VERSION ""

NS_ :

BS_:

BU_: HIL_Tester LOGGER HIL BMS
VAL_TABLE_ TC_StepStatus 2 "TestStepFail" 1 "TestStepPass" 0 "TestStepRunning" ;
VAL_TABLE_ TC_Step 65535 "Beschreibung fr den Wert '0x0'" ;
VAL_TABLE_ TCId 65535 "SNA" ;
VAL_TABLE_ AA_CNTR_State 1 "CLOSED" 0 "OPEN" ;

BO_ 3221225472 VECTOR__INDEPENDENT_SIG_MSG: 0 Vector__XXX
 SG_ ISOSPI_StatusRegContent10 : 0|8@1+ (1,0) [0|0] "" Vector__XXX
 SG_ ISOSPI_StatusRegContent09 : 0|8@1+ (1,0) [0|0] "" Vector__XXX
 SG_ ISOSPI_StatusRegContent08 : 0|8@1+ (1,0) [0|0] "" Vector__XXX
 SG_ ISOSPI_StatusRegContent07 : 0|8@1+ (1,0) [0|0] "" Vector__XXX
 SG_ ISOSPI_StatusRegContent06 : 0|8@1+ (1,0) [0|0] "" Vector__XXX
 SG_ ISOSPI_StatusRegContent05 : 0|8@1+ (1,0) [0|0] "" Vector__XXX
 SG_ ISOSPI_StatusRegContent04 : 0|8@1+ (1,0) [0|0] "" Vector__XXX
 SG_ ISOSPI_GPIOVoltage10 : 0|16@1+ (0.0001,0) [0|6.5535] "V" Vector__XXX
 SG_ ISOSPI_GPIOVoltage09 : 0|16@1+ (0.0001,0) [0|6.5535] "V" Vector__XXX
 SG_ ISOSPI_GPIOVoltage08 : 0|16@1+ (0.0001,0) [0|6.5535] "V" Vector__XXX
 SG_ ISOSPI_GPIOVoltage07 : 0|16@1+ (0.0001,0) [0|6.5535] "V" Vector__XXX
 SG_ ISOSPI_GPIOVoltage06 : 0|16@1+ (0.0001,0) [0|6.5535] "V" Vector__XXX
 SG_ ISOSPI_GPIOVoltage05 : 0|16@1+ (0.0001,0) [0|6.5535] "V" Vector__XXX
 SG_ ISOSPI_GPIOVoltage04 : 0|16@1+ (0.0001,0) [0|6.5535] "V" Vector__XXX
 SG_ ISOSPI_CellVoltage10 : 0|16@1+ (0.0001,0) [0|6.5535] "V" Vector__XXX
 SG_ ISOSPI_CellVoltage09 : 0|16@1+ (0.0001,0) [0|6.5535] "V" Vector__XXX
 SG_ ISOSPI_CellVoltage08 : 0|16@1+ (0.0001,0) [0|6.5535] "V" Vector__XXX
 SG_ ISOSPI_CellVoltage07 : 0|16@1+ (0.0001,0) [0|6.5535] "V" Vector__XXX
 SG_ ISOSPI_CellVoltage06 : 0|16@1+ (0.0001,0) [0|6.5535] "V" Vector__XXX
 SG_ ISOSPI_CellVoltage05 : 0|16@1+ (0.0001,0) [0|6.5535] "V" Vector__XXX
 SG_ ISOSPI_CellVoltage04 : 0|16@1+ (0.0001,0) [0|6.5535] "V" Vector__XXX
 SG_ ISOSPI_StatusRegReadTime : 0|8@1+ (1,0) [0|0] "ms" Vector__XXX
 SG_ ISOSPI_request_03 : 0|8@1- (1,0) [0|0] "" Vector__XXX
 SG_ ISOSPI_request_04 : 0|8@1- (1,0) [0|0] "" Vector__XXX
 SG_ ISOSPI_request_05 : 0|8@1- (1,0) [0|0] "" Vector__XXX
 SG_ ISOSPI_request_02 : 0|8@1- (1,0) [0|0] "" Vector__XXX
 SG_ ISOSPI_request_01 : 0|8@1- (1,0) [0|0] "" Vector__XXX
 SG_ ISOSPI_GPIOMeasTime : 0|8@1- (1,0) [0|0] "ms" Vector__XXX

BO_ 777 RC_Status9: 8 Vector__XXX
 SG_ RC_cntrl09 m9 : 4|60@1- (1,0) [0|0] "" Vector__XXX
 SG_ RC_mux M : 0|4@1- (1,0) [0|0] "" Vector__XXX

BO_ 775 RC_Status7: 8 Vector__XXX
 SG_ RC_cntrl07 m7 : 4|60@1- (1,0) [0|0] "" Vector__XXX
 SG_ RC_mux M : 0|4@1- (1,0) [0|0] "" Vector__XXX

BO_ 774 RC_Status6: 8 Vector__XXX
 SG_ RC_mux M : 0|4@1- (1,0) [0|0] "" Vector__XXX
 SG_ RC_cntrl06 m6 : 4|60@1- (1,0) [0|0] "" Vector__XXX

BO_ 773 RC_Status5: 8 Vector__XXX
 SG_ RC_mux M : 0|4@1- (1,0) [0|0] "" Vector__XXX
 SG_ RC_cntrl05 m5 : 4|60@1- (1,0) [0|0] "" Vector__XXX

BO_ 772 RC_Status4: 8 Vector__XXX
 SG_ RC_mux M : 0|4@1- (1,0) [0|0] "" Vector__XXX
 SG_ RC_cntrl04 m4 : 4|60@1- (1,0) [0|0] "" Vector__XXX

BO_ 771 RC_Status3: 8 Vector__XXX
 SG_ RC_mux M : 0|4@1- (1,0) [0|0] "" Vector__XXX
 SG_ RC_cntrl03 m3 : 4|60@1- (1,0) [0|0] "" Vector__XXX

BO_ 770 RC_Status2: 8 Vector__XXX
 SG_ RC_mux M : 0|4@1- (1,0) [0|0] "" Vector__XXX
 SG_ RC_cntrl02 m2 : 4|60@1- (1,0) [0|0] "" Vector__XXX

BO_ 769 RC_Status1: 8 Vector__XXX
 SG_ RC_mux M : 0|4@1- (1,0) [0|0] "" Vector__XXX
 SG_ RC_cntrl01 m1 : 4|60@1- (1,0) [0|0] "" Vector__XXX

BO_ 768 RC_Status0: 8 Vector__XXX
 SG_ RC_mux M : 0|4@1- (1,0) [0|0] "" Vector__XXX
 SG_ RC_cntrl00 m0 : 4|60@1- (1,0) [0|0] "" Vector__XXX

BO_ 406 RC_CycleCount: 5 Vector__XXX
 SG_ RC_cycleCount16 m16 : 15|32@0+ (1,0) [0|0] "" Vector__XXX
 SG_ RC_cycleCount15 m15 : 15|32@0+ (1,0) [0|0] "" Vector__XXX
 SG_ RC_cycleCount14 m14 : 15|32@0+ (1,0) [0|0] "" Vector__XXX
 SG_ RC_cycleCount13 m13 : 15|32@0+ (1,0) [0|0] "" Vector__XXX
 SG_ RC_cycleCount12 m12 : 15|32@0+ (1,0) [0|0] "" Vector__XXX
 SG_ RC_cycleCount11 m11 : 15|32@0+ (1,0) [0|0] "" Vector__XXX
 SG_ RC_cycleCount10 m10 : 15|32@0+ (1,0) [0|0] "" Vector__XXX
 SG_ RC_cycleCount09 m9 : 15|32@0+ (1,0) [0|0] "" Vector__XXX
 SG_ RC_cycleCount08 m8 : 15|32@0+ (1,0) [0|0] "" Vector__XXX
 SG_ RC_cycleCount07 m7 : 15|32@0+ (1,0) [0|0] "" Vector__XXX
 SG_ RC_cycleCount06 m6 : 15|32@0+ (1,0) [0|0] "" Vector__XXX
 SG_ RC_cycleCount05 m5 : 15|32@0+ (1,0) [0|0] "" Vector__XXX
 SG_ RC_cycleCount04 m4 : 15|32@0+ (1,0) [0|0] "" Vector__XXX
 SG_ RC_cycleCount03 m3 : 15|32@0+ (1,0) [0|0] "" Vector__XXX
 SG_ RC_cycleCount02 m2 : 15|32@0+ (1,0) [0|0] "" Vector__XXX
 SG_ RC_cycleCount01 m1 : 15|32@0+ (1,0) [0|0] "" Vector__XXX
 SG_ RC_cycleCount_mux M : 0|8@1- (1,0) [0|0] "" Vector__XXX
 SG_ RC_cycleCount00 m0 : 15|32@0+ (1,0) [0|0] "" Vector__XXX

BO_ 272 RC_Status: 8 Vector__XXX
 SG_ RC_status07 m7 : 4|60@1- (1,0) [0|0] "" Vector__XXX
 SG_ RC_status06 m6 : 4|60@1- (1,0) [0|0] "" Vector__XXX
 SG_ RC_status05 m5 : 4|60@1- (1,0) [0|0] "" Vector__XXX
 SG_ RC_status04 m4 : 4|60@1- (1,0) [0|0] "" Vector__XXX
 SG_ RC_status03 m3 : 4|60@1- (1,0) [0|0] "" Vector__XXX
 SG_ RC_status02 m2 : 4|60@1- (1,0) [0|0] "" Vector__XXX
 SG_ RC_status01 m1 : 4|60@1- (1,0) [0|0] "" Vector__XXX
 SG_ RC_status00 m0 : 4|60@1- (1,0) [0|0] "" Vector__XXX
 SG_ RC_mux M : 0|4@1- (1,0) [0|0] "" Vector__XXX

BO_ 528 RC_Cntrl: 8 Vector__XXX
 SG_ RC_cntrl15 m15 : 4|60@1- (1,0) [0|0] "" Vector__XXX
 SG_ RC_cntrl09 m9 : 4|60@1- (1,0) [0|0] "" Vector__XXX
 SG_ RC_cntrl07 m7 : 4|60@1- (1,0) [0|0] "" Vector__XXX
 SG_ RC_cntrl06 m6 : 4|60@1- (1,0) [0|0] "" Vector__XXX
 SG_ RC_cntrl05 m5 : 4|60@1- (1,0) [0|0] "" Vector__XXX
 SG_ RC_cntrl04 m4 : 4|60@1- (1,0) [0|0] "" Vector__XXX
 SG_ RC_cntrl03 m3 : 4|60@1- (1,0) [0|0] "" Vector__XXX
 SG_ RC_cntrl02 m2 : 4|60@1- (1,0) [0|0] "" Vector__XXX
 SG_ RC_cntrl01 m1 : 4|60@1- (1,0) [0|0] "" Vector__XXX
 SG_ RC_mux M : 0|4@1+ (1,0) [0|0] "" Vector__XXX
 SG_ RC_cntrl00 m0 : 4|60@1- (1,0) [0|0] "" Vector__XXX

BO_ 277 RC_Stat_ShortToKL30: 8 HIL_Tester
 SG_ RC_Stat_ShortToKL30 : 0|64@1+ (1,0) [0|0] "" Vector__XXX

BO_ 276 RC_Stat_ShortToGND: 8 HIL_Tester
 SG_ RC_Stat_ShortToGND : 0|64@1+ (1,0) [0|0] "" Vector__XXX

BO_ 533 RC_Cntrl_ShortToKL30: 8 HIL_Tester
 SG_ RC_Cntrl_ShortToKL30 : 0|64@1+ (1,0) [0|0] "" Vector__XXX

BO_ 532 RC_Cntrl_ShortToGND: 8 HIL_Tester
 SG_ RC_Cntrl_ShortToGND : 0|64@1+ (1,0) [0|0] "" Vector__XXX

BO_ 368 USB_ISOSPI_RESPONSE_00: 8 Vector__XXX
 SG_ ISOSPI_StatusRegToRead m7 : 8|8@1+ (1,0) [0|0] "0" Vector__XXX
 SG_ ISOSPI_StatusRegContent03 m8 : 32|8@1+ (1,0) [0|0] "" Vector__XXX
 SG_ ISOSPI_StatusRegContent02 m8 : 24|8@1+ (1,0) [0|0] "" Vector__XXX
 SG_ ISOSPI_StatusRegContent01 m8 : 16|8@1+ (1,0) [0|0] "" Vector__XXX
 SG_ ISOSPI_GPIOVoltage03 m6 : 48|16@1+ (0.0001,0) [0|6.5535] "V" Vector__XXX
 SG_ ISOSPI_GPIOVoltage02 m6 : 32|16@1+ (0.0001,0) [0|6.5535] "V" Vector__XXX
 SG_ ISOSPI_GPIOVoltage01 m6 : 16|16@1+ (0.0001,0) [0|6.5535] "V" Vector__XXX
 SG_ ISOSPI_CellVoltage03 m4 : 48|16@1+ (0.0001,0) [0|6.5535] "V" Vector__XXX
 SG_ ISOSPI_CellVoltage02 m4 : 32|16@1+ (0.0001,0) [0|6.5535] "V" Vector__XXX
 SG_ ISOSPI_CellVoltage01 m4 : 16|16@1+ (0.0001,0) [0|6.5535] "V" Vector__XXX
 SG_ ISOSPI_GPIOToRead m6 : 8|8@1- (1,0) [0|0] "" Vector__XXX
 SG_ ISOSPI_GPIOMeasTime m5 : 8|8@1- (1,0) [0|0] "ms" Vector__XXX
 SG_ ISOSPI_configReadTime m2 : 8|8@1- (1,0) [0|0] "ms" Vector__XXX
 SG_ ISOSPI_CellVoltageToRead m4 : 8|8@1- (1,0) [0|0] "0" Vector__XXX
 SG_ ISOSPI_CellMeasTime m3 : 8|8@1- (1,0) [0|0] "ms" Vector__XXX
 SG_ ISOSPI_request_00 M : 0|8@1- (1,0) [0|0] "" Vector__XXX

BO_ 629 USB_ISOSPI_05: 1 Vector__XXX
 SG_ ISOSPI_request_00 M : 0|8@1- (1,0) [0|0] "" Vector__XXX

BO_ 628 USB_ISOSPI_04: 1 Vector__XXX
 SG_ ISOSPI_request_00 M : 0|8@1- (1,0) [0|0] "" Vector__XXX

BO_ 627 USB_ISOSPI_03: 1 Vector__XXX
 SG_ ISOSPI_request_00 M : 0|8@1- (1,0) [0|0] "" Vector__XXX

BO_ 626 USB_ISOSPI_02: 1 Vector__XXX
 SG_ ISOSPI_request_00 M : 0|8@1- (1,0) [0|0] "" Vector__XXX

BO_ 625 USB_ISOSPI_01: 1 Vector__XXX
 SG_ ISOSPI_request_00 M : 0|8@1- (1,0) [0|0] "" Vector__XXX

BO_ 624 USB_ISOSPI_00: 3 Vector__XXX
 SG_ ISOSPI_selftests m13 : 8|8@1- (1,0) [0|0] "" Vector__XXX
 SG_ ISOSPI_ChanneltoBalance m11 : 8|8@1- (1,0) [0|0] "" Vector__XXX
 SG_ ISOSPI_request_00 M : 0|8@1- (1,0) [0|0] "" Vector__XXX

BO_ 297 DAC_CMB_Status: 3 HIL
 SG_ DAC_CMB_Status_05_04_Voltage m67 : 15|16@0+ (0.00122100122100122,0) [0|5] ""  HIL_Tester
 SG_ DAC_CMB_Status_05_03_Voltage m66 : 15|16@0+ (0.00122100122100122,0) [0|5] ""  HIL_Tester
 SG_ DAC_CMB_Status_05_02_Voltage m65 : 15|16@0+ (0.00122100122100122,0) [0|5] ""  HIL_Tester
 SG_ DAC_CMB_Status_05_01_Voltage m64 : 15|16@0+ (0.00122100122100122,0) [0|5] ""  HIL_Tester
 SG_ DAC_CMB_Status_04_04_Voltage m51 : 15|16@0+ (0.00122100122100122,0) [0|5] ""  HIL_Tester
 SG_ DAC_CMB_Status_04_03_Voltage m50 : 15|16@0+ (0.00122100122100122,0) [0|5] ""  HIL_Tester
 SG_ DAC_CMB_Status_04_02_Voltage m49 : 15|16@0+ (0.00122100122100122,0) [0|5] ""  HIL_Tester
 SG_ DAC_CMB_Status_04_01_Voltage m48 : 15|16@0+ (0.00122100122100122,0) [0|5] ""  HIL_Tester
 SG_ DAC_CMB_Status_03_04_Voltage m35 : 15|16@0+ (0.00122100122100122,0) [0|5] ""  HIL_Tester
 SG_ DAC_CMB_Status_03_03_Voltage m34 : 15|16@0+ (0.00122100122100122,0) [0|5] ""  HIL_Tester
 SG_ DAC_CMB_Status_03_02_Voltage m33 : 15|16@0+ (0.00122100122100122,0) [0|5] ""  HIL_Tester
 SG_ DAC_CMB_Status_03_01_Voltage m32 : 15|16@0+ (0.00122100122100122,0) [0|5] ""  HIL_Tester
 SG_ DAC_CMB_Status_02_04_Voltage m19 : 15|16@0+ (0.00122100122100122,0) [0|5] ""  HIL_Tester
 SG_ DAC_CMB_Status_02_03_Voltage m18 : 15|16@0+ (0.00122100122100122,0) [0|5] ""  HIL_Tester
 SG_ DAC_CMB_Status_02_02_Voltage m17 : 15|16@0+ (0.00122100122100122,0) [0|5] ""  HIL_Tester
 SG_ DAC_CMB_Status_02_01_Voltage m16 : 15|16@0+ (0.00122100122100122,0) [0|5] ""  HIL_Tester
 SG_ DAC_CMB_Status_01_04_Voltage m3 : 15|16@0+ (0.00122100122100122,0) [0|5] ""  HIL_Tester
 SG_ DAC_CMB_Status_01_03_Voltage m2 : 15|16@0+ (0.00122100122100122,0) [0|5] ""  HIL_Tester
 SG_ DAC_CMB_Status_01_02_Voltage m1 : 15|16@0+ (0.00122100122100122,0) [0|5] ""  HIL_Tester
 SG_ DAC_CMB_Status_01_01_Voltage m0 : 15|16@0+ (0.00122100122100122,0) [0|5] ""  HIL_Tester
 SG_ DAC_CMB_Status_Channel M : 7|8@0- (1,0) [0|0] ""  HIL_Tester

BO_ 553 DAC_CMB_Cntrl: 3 HIL_Tester
 SG_ DAC_CMB_Cntrl_05_04_Voltage m67 : 15|16@0+ (0.00122100122100122,0) [0|5] ""  HIL_Tester
 SG_ DAC_CMB_Cntrl_05_03_Voltage m66 : 15|16@0+ (0.00122100122100122,0) [0|5] ""  HIL_Tester
 SG_ DAC_CMB_Cntrl_05_02_Voltage m65 : 15|16@0+ (0.00122100122100122,0) [0|5] ""  HIL_Tester
 SG_ DAC_CMB_Cntrl_05_01_Voltage m64 : 15|16@0+ (0.00122100122100122,0) [0|5] ""  HIL_Tester
 SG_ DAC_CMB_Cntrl_04_04_Voltage m51 : 15|16@0+ (0.00122100122100122,0) [0|5] ""  HIL_Tester
 SG_ DAC_CMB_Cntrl_04_03_Voltage m50 : 15|16@0+ (0.00122100122100122,0) [0|5] ""  HIL_Tester
 SG_ DAC_CMB_Cntrl_04_02_Voltage m49 : 15|16@0+ (0.00122100122100122,0) [0|5] ""  HIL_Tester
 SG_ DAC_CMB_Cntrl_04_01_Voltage m48 : 15|16@0+ (0.00122100122100122,0) [0|5] ""  HIL_Tester
 SG_ DAC_CMB_Cntrl_03_04_Voltage m35 : 15|16@0+ (0.00122100122100122,0) [0|5] ""  HIL_Tester
 SG_ DAC_CMB_Cntrl_03_03_Voltage m34 : 15|16@0+ (0.00122100122100122,0) [0|5] ""  HIL_Tester
 SG_ DAC_CMB_Cntrl_03_02_Voltage m33 : 15|16@0+ (0.00122100122100122,0) [0|5] ""  HIL_Tester
 SG_ DAC_CMB_Cntrl_03_01_Voltage m32 : 15|16@0+ (0.00122100122100122,0) [0|5] ""  HIL_Tester
 SG_ DAC_CMB_Cntrl_02_04_Voltage m19 : 15|16@0+ (0.00122100122100122,0) [0|5] ""  HIL_Tester
 SG_ DAC_CMB_Cntrl_02_03_Voltage m18 : 15|16@0+ (0.00122100122100122,0) [0|5] ""  HIL_Tester
 SG_ DAC_CMB_Cntrl_02_02_Voltage m17 : 15|16@0+ (0.00122100122100122,0) [0|5] ""  HIL_Tester
 SG_ DAC_CMB_Cntrl_02_01_Voltage m16 : 15|16@0+ (0.00122100122100122,0) [0|5] ""  HIL_Tester
 SG_ DAC_CMB_Cntrl_01_04_Voltage m3 : 15|16@0+ (0.00122100122100122,0) [0|5] ""  HIL_Tester
 SG_ DAC_CMB_Cntrl_01_03_Voltage m2 : 15|16@0+ (0.00122100122100122,0) [0|5] ""  HIL_Tester
 SG_ DAC_CMB_Cntrl_01_02_Voltage m1 : 15|16@0+ (0.00122100122100122,0) [0|5] ""  HIL_Tester
 SG_ DAC_CMB_Cntrl_01_01_Voltage m0 : 15|16@0+ (0.00122100122100122,0) [0|5] ""  HIL_Tester
 SG_ DAC_CMB_Cntrl_Channel M : 7|8@0- (1,0) [0|0] ""  HIL_Tester

BO_ 554 DAC_CMB_Cntrl2: 3 HIL_Tester
 SG_ DAC_CMB_Cntrl_05_04_Voltage m67 : 15|16@0+ (0.00122100122100122,0) [0|5] ""  HIL_Tester
 SG_ DAC_CMB_Cntrl_05_03_Voltage m66 : 15|16@0+ (0.00122100122100122,0) [0|5] ""  HIL_Tester
 SG_ DAC_CMB_Cntrl_05_02_Voltage m65 : 15|16@0+ (0.00122100122100122,0) [0|5] ""  HIL_Tester
 SG_ DAC_CMB_Cntrl_05_01_Voltage m64 : 15|16@0+ (0.00122100122100122,0) [0|5] ""  HIL_Tester
 SG_ DAC_CMB_Cntrl_04_04_Voltage m51 : 15|16@0+ (0.00122100122100122,0) [0|5] ""  HIL_Tester
 SG_ DAC_CMB_Cntrl_04_03_Voltage m50 : 15|16@0+ (0.00122100122100122,0) [0|5] ""  HIL_Tester
 SG_ DAC_CMB_Cntrl_04_02_Voltage m49 : 15|16@0+ (0.00122100122100122,0) [0|5] ""  HIL_Tester
 SG_ DAC_CMB_Cntrl_04_01_Voltage m48 : 15|16@0+ (0.00122100122100122,0) [0|5] ""  HIL_Tester
 SG_ DAC_CMB_Cntrl_03_04_Voltage m35 : 15|16@0+ (0.00122100122100122,0) [0|5] ""  HIL_Tester
 SG_ DAC_CMB_Cntrl_03_03_Voltage m34 : 15|16@0+ (0.00122100122100122,0) [0|5] ""  HIL_Tester
 SG_ DAC_CMB_Cntrl_03_02_Voltage m33 : 15|16@0+ (0.00122100122100122,0) [0|5] ""  HIL_Tester
 SG_ DAC_CMB_Cntrl_03_01_Voltage m32 : 15|16@0+ (0.00122100122100122,0) [0|5] ""  HIL_Tester
 SG_ DAC_CMB_Cntrl_02_04_Voltage m19 : 15|16@0+ (0.00122100122100122,0) [0|5] ""  HIL_Tester
 SG_ DAC_CMB_Cntrl_02_03_Voltage m18 : 15|16@0+ (0.00122100122100122,0) [0|5] ""  HIL_Tester
 SG_ DAC_CMB_Cntrl_02_02_Voltage m17 : 15|16@0+ (0.00122100122100122,0) [0|5] ""  HIL_Tester
 SG_ DAC_CMB_Cntrl_02_01_Voltage m16 : 15|16@0+ (0.00122100122100122,0) [0|5] ""  HIL_Tester
 SG_ DAC_CMB_Cntrl_01_04_Voltage m3 : 15|16@0+ (0.00122100122100122,0) [0|5] ""  HIL_Tester
 SG_ DAC_CMB_Cntrl_01_03_Voltage m2 : 15|16@0+ (0.00122100122100122,0) [0|5] ""  HIL_Tester
 SG_ DAC_CMB_Cntrl_01_02_Voltage m1 : 15|16@0+ (0.00122100122100122,0) [0|5] ""  HIL_Tester
 SG_ DAC_CMB_Cntrl_01_01_Voltage m0 : 15|16@0+ (0.00122100122100122,0) [0|5] ""  HIL_Tester
 SG_ DAC_CMB_Cntrl_Channel M : 7|8@0- (1,0) [0|0] ""  HIL_Tester

BO_ 555 DAC_CMB_Cntrl3: 3 HIL_Tester
 SG_ DAC_CMB_Cntrl_05_04_Voltage m67 : 15|16@0+ (0.00122100122100122,0) [0|5] ""  HIL_Tester
 SG_ DAC_CMB_Cntrl_05_03_Voltage m66 : 15|16@0+ (0.00122100122100122,0) [0|5] ""  HIL_Tester
 SG_ DAC_CMB_Cntrl_05_02_Voltage m65 : 15|16@0+ (0.00122100122100122,0) [0|5] ""  HIL_Tester
 SG_ DAC_CMB_Cntrl_05_01_Voltage m64 : 15|16@0+ (0.00122100122100122,0) [0|5] ""  HIL_Tester
 SG_ DAC_CMB_Cntrl_04_04_Voltage m51 : 15|16@0+ (0.00122100122100122,0) [0|5] ""  HIL_Tester
 SG_ DAC_CMB_Cntrl_04_03_Voltage m50 : 15|16@0+ (0.00122100122100122,0) [0|5] ""  HIL_Tester
 SG_ DAC_CMB_Cntrl_04_02_Voltage m49 : 15|16@0+ (0.00122100122100122,0) [0|5] ""  HIL_Tester
 SG_ DAC_CMB_Cntrl_04_01_Voltage m48 : 15|16@0+ (0.00122100122100122,0) [0|5] ""  HIL_Tester
 SG_ DAC_CMB_Cntrl_03_04_Voltage m35 : 15|16@0+ (0.00122100122100122,0) [0|5] ""  HIL_Tester
 SG_ DAC_CMB_Cntrl_03_03_Voltage m34 : 15|16@0+ (0.00122100122100122,0) [0|5] ""  HIL_Tester
 SG_ DAC_CMB_Cntrl_03_02_Voltage m33 : 15|16@0+ (0.00122100122100122,0) [0|5] ""  HIL_Tester
 SG_ DAC_CMB_Cntrl_03_01_Voltage m32 : 15|16@0+ (0.00122100122100122,0) [0|5] ""  HIL_Tester
 SG_ DAC_CMB_Cntrl_02_04_Voltage m19 : 15|16@0+ (0.00122100122100122,0) [0|5] ""  HIL_Tester
 SG_ DAC_CMB_Cntrl_02_03_Voltage m18 : 15|16@0+ (0.00122100122100122,0) [0|5] ""  HIL_Tester
 SG_ DAC_CMB_Cntrl_02_02_Voltage m17 : 15|16@0+ (0.00122100122100122,0) [0|5] ""  HIL_Tester
 SG_ DAC_CMB_Cntrl_02_01_Voltage m16 : 15|16@0+ (0.00122100122100122,0) [0|5] ""  HIL_Tester
 SG_ DAC_CMB_Cntrl_01_04_Voltage m3 : 15|16@0+ (0.00122100122100122,0) [0|5] ""  HIL_Tester
 SG_ DAC_CMB_Cntrl_01_03_Voltage m2 : 15|16@0+ (0.00122100122100122,0) [0|5] ""  HIL_Tester
 SG_ DAC_CMB_Cntrl_01_02_Voltage m1 : 15|16@0+ (0.00122100122100122,0) [0|5] ""  HIL_Tester
 SG_ DAC_CMB_Cntrl_01_01_Voltage m0 : 15|16@0+ (0.00122100122100122,0) [0|5] ""  HIL_Tester
 SG_ DAC_CMB_Cntrl_Channel M : 7|8@0- (1,0) [0|0] ""  HIL_Tester

BO_ 288 DAC_BMS_Status: 3 HIL
 SG_ DAC_BMS_Status_05_04_Voltage m67 : 15|16@0+ (0.00122100122100122,0) [0|5] ""  HIL_Tester
 SG_ DAC_BMS_Status_05_03_Voltage m66 : 15|16@0+ (0.00122100122100122,0) [0|5] ""  HIL_Tester
 SG_ DAC_BMS_Status_05_02_Voltage m65 : 15|16@0+ (0.00122100122100122,0) [0|5] ""  HIL_Tester
 SG_ DAC_BMS_Status_05_01_Voltage m64 : 15|16@0+ (0.00122100122100122,0) [0|5] ""  HIL_Tester
 SG_ DAC_BMS_Status_04_04_Voltage m51 : 15|16@0+ (0.00122100122100122,0) [0|5] ""  HIL_Tester
 SG_ DAC_BMS_Status_04_03_Voltage m50 : 15|16@0+ (0.00122100122100122,0) [0|5] ""  HIL_Tester
 SG_ DAC_BMS_Status_04_02_Voltage m49 : 15|16@0+ (0.00122100122100122,0) [0|5] ""  HIL_Tester
 SG_ DAC_BMS_Status_04_01_Voltage m48 : 15|16@0+ (0.00122100122100122,0) [0|5] ""  HIL_Tester
 SG_ DAC_BMS_Status_03_04_Voltage m35 : 15|16@0+ (0.00122100122100122,0) [0|5] ""  HIL_Tester
 SG_ DAC_BMS_Status_03_03_Voltage m34 : 15|16@0+ (0.00122100122100122,0) [0|5] ""  HIL_Tester
 SG_ DAC_BMS_Status_03_02_Voltage m33 : 15|16@0+ (0.00122100122100122,0) [0|5] ""  HIL_Tester
 SG_ DAC_BMS_Status_03_01_Voltage m32 : 15|16@0+ (0.00122100122100122,0) [0|5] ""  HIL_Tester
 SG_ DAC_BMS_Status_02_04_Voltage m19 : 15|16@0+ (0.00122100122100122,0) [0|5] ""  HIL_Tester
 SG_ DAC_BMS_Status_02_03_Voltage m18 : 15|16@0+ (0.00122100122100122,0) [0|5] ""  HIL_Tester
 SG_ DAC_BMS_Status_02_02_Voltage m17 : 15|16@0+ (0.00122100122100122,0) [0|5] ""  HIL_Tester
 SG_ DAC_BMS_Status_02_01_Voltage m16 : 15|16@0+ (0.00122100122100122,0) [0|5] ""  HIL_Tester
 SG_ DAC_BMS_Status_01_04_Voltage m3 : 15|16@0+ (0.00122100122100122,0) [0|5] ""  HIL_Tester
 SG_ DAC_BMS_Status_01_03_Voltage m2 : 15|16@0+ (0.00122100122100122,0) [0|5] ""  HIL_Tester
 SG_ DAC_BMS_Status_01_02_Voltage m1 : 15|16@0+ (0.00122100122100122,0) [0|5] ""  HIL_Tester
 SG_ DAC_BMS_Status_01_01_Voltage m0 : 15|16@0+ (0.00122100122100122,0) [0|5] ""  HIL_Tester
 SG_ DAC_BMS_Status_Channel M : 7|8@0+ (1,0) [0|0] ""  HIL_Tester

BO_ 544 DAC_BMS_Cntrl: 3 HIL_Tester
 SG_ DAC_BMS_Cntrl_05_04_Voltage m67 : 15|16@0+ (0.00122100122100122,0) [0|5] ""  HIL_Tester
 SG_ DAC_BMS_Cntrl_05_03_Voltage m66 : 15|16@0+ (0.00122100122100122,0) [0|5] ""  HIL_Tester
 SG_ DAC_BMS_Cntrl_05_02_Voltage m65 : 15|16@0+ (0.00122100122100122,0) [0|5] ""  HIL_Tester
 SG_ DAC_BMS_Cntrl_05_01_Voltage m64 : 15|16@0+ (0.00122100122100122,0) [0|5] ""  HIL_Tester
 SG_ DAC_BMS_Cntrl_04_04_Voltage m51 : 15|16@0+ (0.00122100122100122,0) [0|5] ""  HIL_Tester
 SG_ DAC_BMS_Cntrl_04_03_Voltage m50 : 15|16@0+ (0.00122100122100122,0) [0|5] ""  HIL_Tester
 SG_ DAC_BMS_Cntrl_04_02_Voltage m49 : 15|16@0+ (0.00122100122100122,0) [0|5] ""  HIL_Tester
 SG_ DAC_BMS_Cntrl_04_01_Voltage m48 : 15|16@0+ (0.00122100122100122,0) [0|5] ""  HIL_Tester
 SG_ DAC_BMS_Cntrl_03_04_Voltage m35 : 15|16@0+ (0.00122100122100122,0) [0|5] ""  HIL_Tester
 SG_ DAC_BMS_Cntrl_03_03_Voltage m34 : 15|16@0+ (0.00122100122100122,0) [0|5] ""  HIL_Tester
 SG_ DAC_BMS_Cntrl_03_02_Voltage m33 : 15|16@0+ (0.00122100122100122,0) [0|5] ""  HIL_Tester
 SG_ DAC_BMS_Cntrl_03_01_Voltage m32 : 15|16@0+ (0.00122100122100122,0) [0|5] ""  HIL_Tester
 SG_ DAC_BMS_Cntrl_02_04_Voltage m19 : 15|16@0+ (0.00122100122100122,0) [0|5] ""  HIL_Tester
 SG_ DAC_BMS_Cntrl_02_03_Voltage m18 : 15|16@0+ (0.00122100122100122,0) [0|5] ""  HIL_Tester
 SG_ DAC_BMS_Cntrl_02_02_Voltage m17 : 15|16@0+ (0.00122100122100122,0) [0|5] ""  HIL_Tester
 SG_ DAC_BMS_Cntrl_02_01_Voltage m16 : 15|16@0+ (0.00122100122100122,0) [0|5] ""  HIL_Tester
 SG_ DAC_BMS_Cntrl_01_04_Voltage m3 : 15|16@0+ (0.00122100122100122,0) [0|5] ""  HIL_Tester
 SG_ DAC_BMS_Cntrl_01_03_Voltage m2 : 15|16@0+ (0.00122100122100122,0) [0|5] ""  HIL_Tester
 SG_ DAC_BMS_Cntrl_01_02_Voltage m1 : 15|16@0+ (0.00122100122100122,0) [0|5] ""  HIL_Tester
 SG_ DAC_BMS_Cntrl_01_01_Voltage m0 : 15|16@0+ (0.00122100122100122,0) [0|5] ""  HIL_Tester
 SG_ DAC_BMS_Cntrl_Channel M : 7|8@0- (1,0) [0|0] ""  HIL_Tester

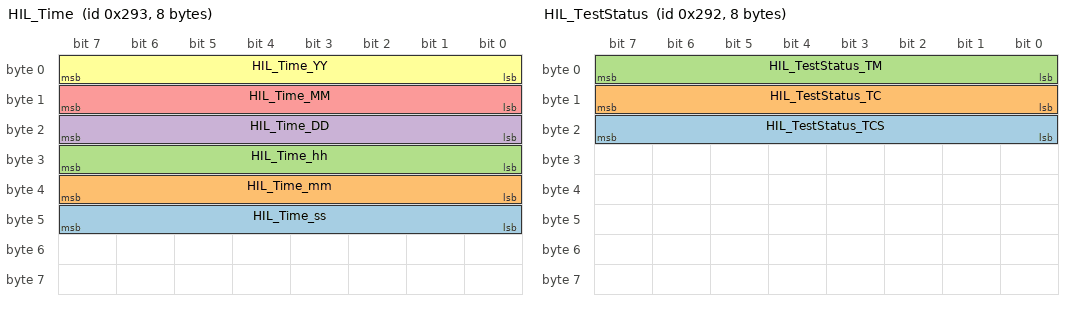
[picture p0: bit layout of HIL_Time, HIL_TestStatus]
BO_ 659 HIL_Time: 8 HIL
 SG_ HIL_Time_ss : 47|8@0+ (1,0) [0|0] ""  HIL_Tester
 SG_ HIL_Time_mm : 39|8@0+ (1,0) [0|0] ""  HIL_Tester
 SG_ HIL_Time_hh : 31|8@0+ (1,0) [0|0] ""  HIL_Tester
 SG_ HIL_Time_DD : 23|8@0+ (1,0) [0|0] ""  HIL_Tester
 SG_ HIL_Time_MM : 15|8@0+ (1,0) [0|0] ""  HIL_Tester
 SG_ HIL_Time_YY : 7|8@0+ (1,0) [0|0] ""  HIL_Tester

BO_ 658 HIL_TestStatus: 8 HIL
 SG_ HIL_TestStatus_TCS : 23|8@0+ (1,0) [0|0] ""  HIL_Tester
 SG_ HIL_TestStatus_TC : 15|8@0+ (1,0) [0|0] ""  HIL_Tester
 SG_ HIL_TestStatus_TM : 7|8@0+ (1,0) [0|0] ""  HIL_Tester

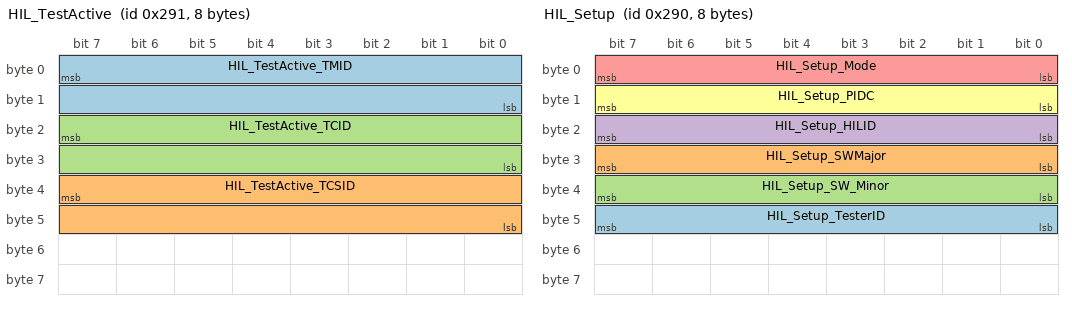
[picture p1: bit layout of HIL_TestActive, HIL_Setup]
BO_ 657 HIL_TestActive: 8 HIL
 SG_ HIL_TestActive_TMID : 7|16@0+ (1,0) [0|0] ""  HIL_Tester
 SG_ HIL_TestActive_TCSID : 39|16@0+ (1,0) [0|0] ""  HIL_Tester
 SG_ HIL_TestActive_TCID : 23|16@0+ (1,0) [0|0] ""  HIL_Tester

BO_ 656 HIL_Setup: 8 HIL
 SG_ HIL_Setup_TesterID : 47|8@0+ (1,0) [0|0] ""  HIL_Tester
 SG_ HIL_Setup_SWMajor : 31|8@0+ (1,0) [0|0] ""  HIL_Tester
 SG_ HIL_Setup_SW_Minor : 39|8@0+ (1,0) [0|0] ""  HIL_Tester
 SG_ HIL_Setup_HILID : 23|8@0+ (1,0) [0|0] ""  HIL_Tester
 SG_ HIL_Setup_Mode : 7|8@0+ (1,0) [0|0] ""  HIL_Tester
 SG_ HIL_Setup_PIDC : 15|8@0+ (1,0) [0|0] ""  HIL_Tester

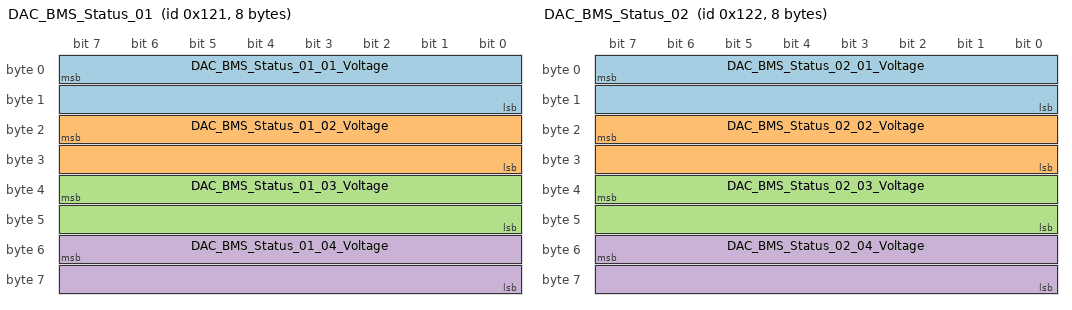
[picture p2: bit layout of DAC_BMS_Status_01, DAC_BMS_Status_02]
BO_ 289 DAC_BMS_Status_01: 8 HIL
 SG_ DAC_BMS_Status_01_01_Voltage : 7|16@0+ (0.00122100122100122,0) [0|5] ""  HIL_Tester
 SG_ DAC_BMS_Status_01_02_Voltage : 23|16@0+ (0.00122100122100122,0) [0|5] ""  HIL_Tester
 SG_ DAC_BMS_Status_01_03_Voltage : 39|16@0+ (0.00122100122100122,0) [0|5] ""  HIL_Tester
 SG_ DAC_BMS_Status_01_04_Voltage : 55|16@0+ (0.00122100122100122,0) [0|5] ""  HIL_Tester

BO_ 290 DAC_BMS_Status_02: 8 HIL
 SG_ DAC_BMS_Status_02_01_Voltage : 7|16@0+ (0.00122100122100122,0) [0|5] ""  HIL_Tester
 SG_ DAC_BMS_Status_02_02_Voltage : 23|16@0+ (0.00122100122100122,0) [0|5] ""  HIL_Tester
 SG_ DAC_BMS_Status_02_03_Voltage : 39|16@0+ (0.00122100122100122,0) [0|5] ""  HIL_Tester
 SG_ DAC_BMS_Status_02_04_Voltage : 55|16@0+ (0.00122100122100122,0) [0|5] ""  HIL_Tester

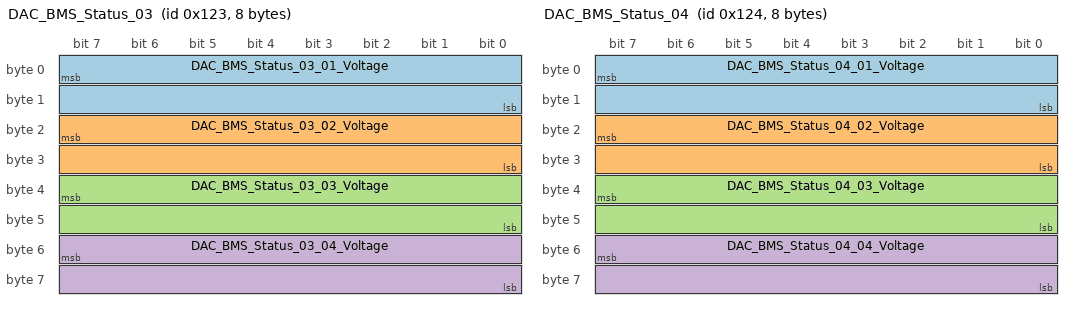
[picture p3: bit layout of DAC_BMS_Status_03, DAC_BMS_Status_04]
BO_ 291 DAC_BMS_Status_03: 8 HIL
 SG_ DAC_BMS_Status_03_01_Voltage : 7|16@0+ (0.00122100122100122,0) [0|5] ""  HIL_Tester
 SG_ DAC_BMS_Status_03_02_Voltage : 23|16@0+ (0.00122100122100122,0) [0|5] ""  HIL_Tester
 SG_ DAC_BMS_Status_03_03_Voltage : 39|16@0+ (0.00122100122100122,0) [0|5] ""  HIL_Tester
 SG_ DAC_BMS_Status_03_04_Voltage : 55|16@0+ (0.00122100122100122,0) [0|5] ""  HIL_Tester

BO_ 292 DAC_BMS_Status_04: 8 HIL
 SG_ DAC_BMS_Status_04_01_Voltage : 7|16@0+ (0.00122100122100122,0) [0|5] ""  HIL_Tester
 SG_ DAC_BMS_Status_04_02_Voltage : 23|16@0+ (0.00122100122100122,0) [0|5] ""  HIL_Tester
 SG_ DAC_BMS_Status_04_03_Voltage : 39|16@0+ (0.00122100122100122,0) [0|5] ""  HIL_Tester
 SG_ DAC_BMS_Status_04_04_Voltage : 55|16@0+ (0.00122100122100122,0) [0|5] ""  HIL_Tester

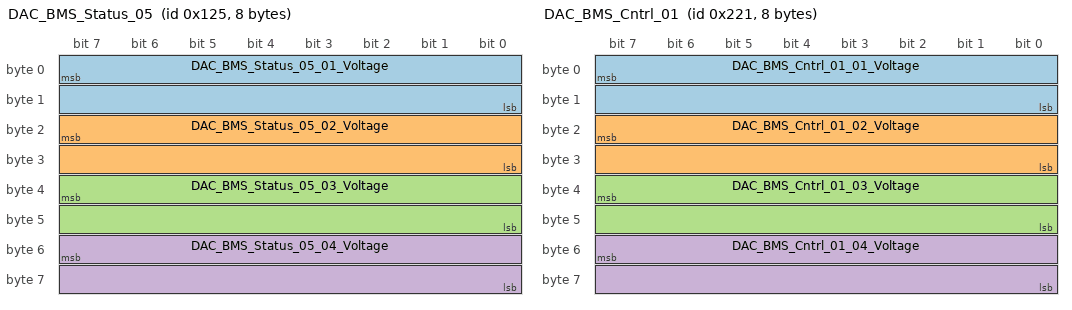
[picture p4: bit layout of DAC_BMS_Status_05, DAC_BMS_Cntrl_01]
BO_ 293 DAC_BMS_Status_05: 8 HIL
 SG_ DAC_BMS_Status_05_01_Voltage : 7|16@0+ (0.00122100122100122,0) [0|5] ""  HIL_Tester
 SG_ DAC_BMS_Status_05_02_Voltage : 23|16@0+ (0.00122100122100122,0) [0|5] ""  HIL_Tester
 SG_ DAC_BMS_Status_05_03_Voltage : 39|16@0+ (0.00122100122100122,0) [0|5] ""  HIL_Tester
 SG_ DAC_BMS_Status_05_04_Voltage : 55|16@0+ (0.00122100122100122,0) [0|5] ""  HIL_Tester

BO_ 545 DAC_BMS_Cntrl_01: 8 HIL_Tester
 SG_ DAC_BMS_Cntrl_01_01_Voltage : 7|16@0+ (0.00122100122100122,0) [0|5] ""  HIL
 SG_ DAC_BMS_Cntrl_01_02_Voltage : 23|16@0+ (0.00122100122100122,0) [0|5] ""  HIL
 SG_ DAC_BMS_Cntrl_01_03_Voltage : 39|16@0+ (0.00122100122100122,0) [0|5] ""  HIL
 SG_ DAC_BMS_Cntrl_01_04_Voltage : 55|16@0+ (0.00122100122100122,0) [0|5] ""  HIL

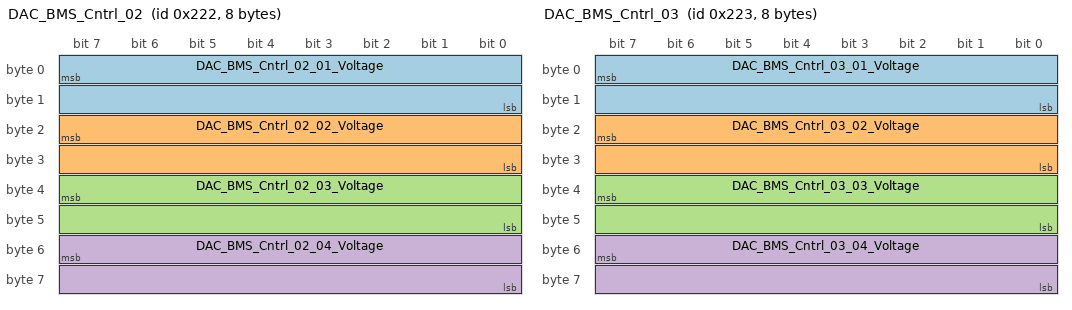
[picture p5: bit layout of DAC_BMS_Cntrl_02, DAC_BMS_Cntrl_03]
BO_ 546 DAC_BMS_Cntrl_02: 8 HIL_Tester
 SG_ DAC_BMS_Cntrl_02_01_Voltage : 7|16@0+ (0.00122100122100122,0) [0|5] ""  HIL
 SG_ DAC_BMS_Cntrl_02_02_Voltage : 23|16@0+ (0.00122100122100122,0) [0|5] ""  HIL
 SG_ DAC_BMS_Cntrl_02_03_Voltage : 39|16@0+ (0.00122100122100122,0) [0|5] ""  HIL
 SG_ DAC_BMS_Cntrl_02_04_Voltage : 55|16@0+ (0.00122100122100122,0) [0|5] ""  HIL

BO_ 547 DAC_BMS_Cntrl_03: 8 HIL_Tester
 SG_ DAC_BMS_Cntrl_03_01_Voltage : 7|16@0+ (0.00122100122100122,0) [0|5] ""  HIL
 SG_ DAC_BMS_Cntrl_03_02_Voltage : 23|16@0+ (0.00122100122100122,0) [0|5] ""  HIL
 SG_ DAC_BMS_Cntrl_03_03_Voltage : 39|16@0+ (0.00122100122100122,0) [0|5] ""  HIL
 SG_ DAC_BMS_Cntrl_03_04_Voltage : 55|16@0+ (0.00122100122100122,0) [0|5] ""  HIL

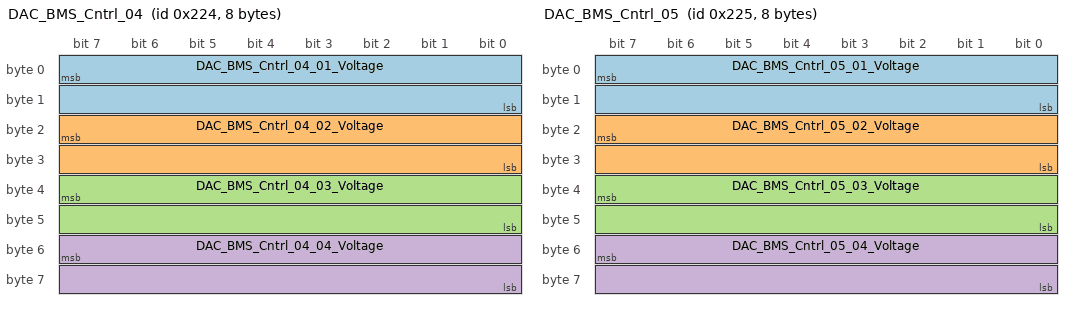
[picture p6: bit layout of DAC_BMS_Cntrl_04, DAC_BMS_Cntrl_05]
BO_ 548 DAC_BMS_Cntrl_04: 8 HIL_Tester
 SG_ DAC_BMS_Cntrl_04_01_Voltage : 7|16@0+ (0.00122100122100122,0) [0|5] ""  HIL
 SG_ DAC_BMS_Cntrl_04_02_Voltage : 23|16@0+ (0.00122100122100122,0) [0|5] ""  HIL
 SG_ DAC_BMS_Cntrl_04_03_Voltage : 39|16@0+ (0.00122100122100122,0) [0|5] ""  HIL
 SG_ DAC_BMS_Cntrl_04_04_Voltage : 55|16@0+ (0.00122100122100122,0) [0|5] ""  HIL

BO_ 549 DAC_BMS_Cntrl_05: 8 HIL_Tester
 SG_ DAC_BMS_Cntrl_05_01_Voltage : 7|16@0+ (0.00122100122100122,0) [0|5] ""  HIL
 SG_ DAC_BMS_Cntrl_05_02_Voltage : 23|16@0+ (0.00122100122100122,0) [0|5] ""  HIL
 SG_ DAC_BMS_Cntrl_05_03_Voltage : 39|16@0+ (0.00122100122100122,0) [0|5] ""  HIL
 SG_ DAC_BMS_Cntrl_05_04_Voltage : 55|16@0+ (0.00122100122100122,0) [0|5] ""  HIL

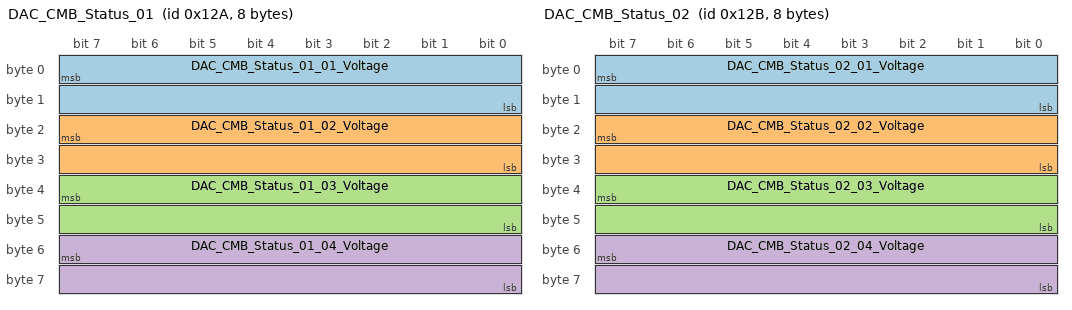
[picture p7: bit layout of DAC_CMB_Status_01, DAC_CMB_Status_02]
BO_ 298 DAC_CMB_Status_01: 8 HIL
 SG_ DAC_CMB_Status_01_01_Voltage : 7|16@0+ (0.00122100122100122,0) [0|5] ""  HIL_Tester
 SG_ DAC_CMB_Status_01_02_Voltage : 23|16@0+ (0.00122100122100122,0) [0|5] ""  HIL_Tester
 SG_ DAC_CMB_Status_01_03_Voltage : 39|16@0+ (0.00122100122100122,0) [0|5] ""  HIL_Tester
 SG_ DAC_CMB_Status_01_04_Voltage : 55|16@0+ (0.00122100122100122,0) [0|5] ""  HIL_Tester

BO_ 299 DAC_CMB_Status_02: 8 HIL
 SG_ DAC_CMB_Status_02_01_Voltage : 7|16@0+ (0.00122100122100122,0) [0|5] ""  HIL_Tester
 SG_ DAC_CMB_Status_02_02_Voltage : 23|16@0+ (0.00122100122100122,0) [0|5] ""  HIL_Tester
 SG_ DAC_CMB_Status_02_03_Voltage : 39|16@0+ (0.00122100122100122,0) [0|5] ""  HIL_Tester
 SG_ DAC_CMB_Status_02_04_Voltage : 55|16@0+ (0.00122100122100122,0) [0|5] ""  HIL_Tester

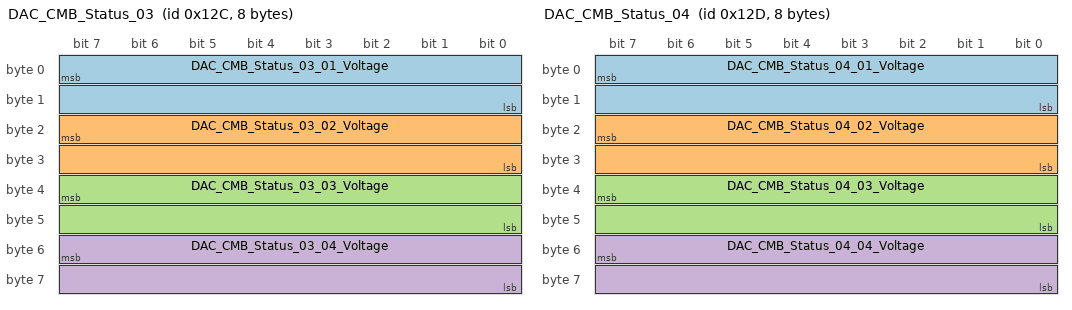
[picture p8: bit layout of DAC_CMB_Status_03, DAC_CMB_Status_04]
BO_ 300 DAC_CMB_Status_03: 8 HIL
 SG_ DAC_CMB_Status_03_01_Voltage : 7|16@0+ (0.00122100122100122,0) [0|5] ""  HIL_Tester
 SG_ DAC_CMB_Status_03_02_Voltage : 23|16@0+ (0.00122100122100122,0) [0|5] ""  HIL_Tester
 SG_ DAC_CMB_Status_03_03_Voltage : 39|16@0+ (0.00122100122100122,0) [0|5] ""  HIL_Tester
 SG_ DAC_CMB_Status_03_04_Voltage : 55|16@0+ (0.00122100122100122,0) [0|5] ""  HIL_Tester

BO_ 301 DAC_CMB_Status_04: 8 HIL
 SG_ DAC_CMB_Status_04_01_Voltage : 7|16@0+ (0.00122100122100122,0) [0|5] ""  HIL_Tester
 SG_ DAC_CMB_Status_04_02_Voltage : 23|16@0+ (0.00122100122100122,0) [0|5] ""  HIL_Tester
 SG_ DAC_CMB_Status_04_03_Voltage : 39|16@0+ (0.00122100122100122,0) [0|5] ""  HIL_Tester
 SG_ DAC_CMB_Status_04_04_Voltage : 55|16@0+ (0.00122100122100122,0) [0|5] ""  HIL_Tester

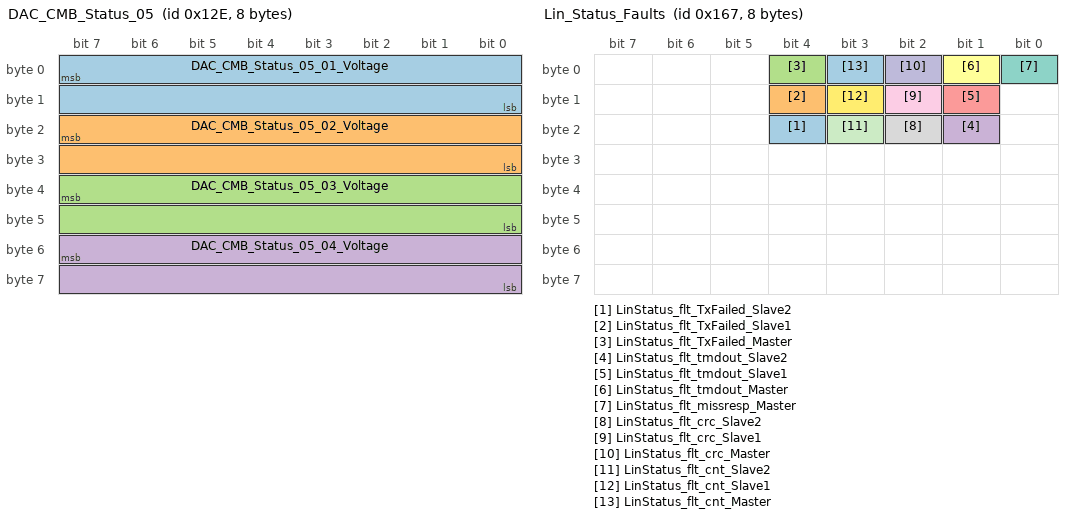
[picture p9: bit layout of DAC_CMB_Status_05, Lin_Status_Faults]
BO_ 302 DAC_CMB_Status_05: 8 HIL
 SG_ DAC_CMB_Status_05_01_Voltage : 7|16@0+ (0.00122100122100122,0) [0|5] ""  HIL_Tester
 SG_ DAC_CMB_Status_05_02_Voltage : 23|16@0+ (0.00122100122100122,0) [0|5] ""  HIL_Tester
 SG_ DAC_CMB_Status_05_03_Voltage : 39|16@0+ (0.00122100122100122,0) [0|5] ""  HIL_Tester
 SG_ DAC_CMB_Status_05_04_Voltage : 55|16@0+ (0.00122100122100122,0) [0|5] ""  HIL_Tester

BO_ 321 PS_StatusA_01: 8 HIL
 SG_ PS_StatusA_01_01_VerifyStatus m0 : 63|8@0+ (1,0) [0|255] ""  HIL_Tester
 SG_ PS_StatusA_01_01_Modes m0 : 55|8@0+ (1,0) [0|255] ""  HIL_Tester
 SG_ PS_StatusA_01_01_Enable m0 : 15|8@0+ (1,0) [0|255] ""  HIL_Tester
 SG_ PS_StatusA_01_01_VoltageActual m0 : 23|16@0+ (0.001,0) [0|32] ""  HIL_Tester
 SG_ PS_StatusA_01_01_CurrentActual m0 : 39|16@0+ (0.001,0) [0|32] ""  HIL_Tester
 SG_ PS_StatusA_01_02_VerifyStatus m1 : 63|8@0+ (1,0) [0|255] ""  HIL_Tester
 SG_ PS_StatusA_01_02_Modes m1 : 55|8@0+ (1,0) [0|255] ""  HIL_Tester
 SG_ PS_StatusA_01_02_Enable m1 : 15|8@0+ (1,0) [0|255] ""  HIL_Tester
 SG_ PS_StatusA_01_02_VoltageActual m1 : 23|16@0+ (0.001,0) [0|32] ""  HIL_Tester
 SG_ PS_StatusA_01_02_CurrentActual m1 : 39|16@0+ (0.001,0) [0|32] ""  HIL_Tester
 SG_ PS_StatusA_01_03_VerifyStatus m2 : 63|8@0+ (1,0) [0|255] ""  HIL_Tester
 SG_ PS_StatusA_01_03_Modes m2 : 55|8@0+ (1,0) [0|255] ""  HIL_Tester
 SG_ PS_StatusA_01_03_Enable m2 : 15|8@0+ (1,0) [0|255] ""  HIL_Tester
 SG_ PS_StatusA_01_03_VoltageActual m2 : 23|16@0+ (0.001,0) [0|32] ""  HIL_Tester
 SG_ PS_StatusA_01_03_CurrentActual m2 : 39|16@0+ (0.001,0) [0|32] ""  HIL_Tester
 SG_ PS_StatusA_01_04_VerifyStatus m3 : 63|8@0+ (1,0) [0|255] ""  HIL_Tester
 SG_ PS_StatusA_01_04_Modes m3 : 55|8@0+ (1,0) [0|255] ""  HIL_Tester
 SG_ PS_StatusA_01_04_Enable m3 : 15|8@0+ (1,0) [0|255] ""  HIL_Tester
 SG_ PS_StatusA_01_04_VoltageActual m3 : 23|16@0+ (0.001,0) [0|32] ""  HIL_Tester
 SG_ PS_StatusA_01_04_CurrentActual m3 : 39|16@0+ (0.001,0) [0|32] ""  HIL_Tester
 SG_ PS_StatusA_01_Channel M : 7|8@0- (1,0) [0|4] ""  HIL_Tester

BO_ 322 PS_StatusA_02: 8 HIL
 SG_ PS_StatusA_02_01_VerifyStatus m0 : 63|8@0+ (1,0) [0|255] ""  HIL_Tester
 SG_ PS_StatusA_02_01_Modes m0 : 55|8@0+ (1,0) [0|255] ""  HIL_Tester
 SG_ PS_StatusA_02_01_Enable m0 : 15|8@0+ (1,0) [0|255] ""  HIL_Tester
 SG_ PS_StatusA_02_01_VoltageActual m0 : 23|16@0+ (0.001,0) [0|32] ""  HIL_Tester
 SG_ PS_StatusA_02_01_CurrentActual m0 : 39|16@0+ (0.001,0) [0|32] ""  HIL_Tester
 SG_ PS_StatusA_02_02_VerifyStatus m1 : 63|8@0+ (1,0) [0|255] ""  HIL_Tester
 SG_ PS_StatusA_02_02_Modes m1 : 55|8@0+ (1,0) [0|255] ""  HIL_Tester
 SG_ PS_StatusA_02_02_Enable m1 : 15|8@0+ (1,0) [0|255] ""  HIL_Tester
 SG_ PS_StatusA_02_02_VoltageActual m1 : 23|16@0+ (0.001,0) [0|32] ""  HIL_Tester
 SG_ PS_StatusA_02_02_CurrentActual m1 : 39|16@0+ (0.001,0) [0|32] ""  HIL_Tester
 SG_ PS_StatusA_02_03_VerifyStatus m2 : 63|8@0+ (1,0) [0|255] ""  HIL_Tester
 SG_ PS_StatusA_02_03_Modes m2 : 55|8@0+ (1,0) [0|255] ""  HIL_Tester
 SG_ PS_StatusA_02_03_Enable m2 : 15|8@0+ (1,0) [0|255] ""  HIL_Tester
 SG_ PS_StatusA_02_03_VoltageActual m2 : 23|16@0+ (0.001,0) [0|32] ""  HIL_Tester
 SG_ PS_StatusA_02_03_CurrentActual m2 : 39|16@0+ (0.001,0) [0|32] ""  HIL_Tester
 SG_ PS_StatusA_02_04_VerifyStatus m3 : 63|8@0+ (1,0) [0|255] ""  HIL_Tester
 SG_ PS_StatusA_02_04_Modes m3 : 55|8@0+ (1,0) [0|255] ""  HIL_Tester
 SG_ PS_StatusA_02_04_Enable m3 : 15|8@0+ (1,0) [0|255] ""  HIL_Tester
 SG_ PS_StatusA_02_04_VoltageActual m3 : 23|16@0+ (0.001,0) [0|32] ""  HIL_Tester
 SG_ PS_StatusA_02_04_CurrentActual m3 : 39|16@0+ (0.001,0) [0|32] ""  HIL_Tester
 SG_ PS_StatusA_02_Channel M : 7|8@0- (1,0) [0|4] ""  HIL_Tester

BO_ 323 PS_StatusA_03: 8 HIL
 SG_ PS_StatusA_03_01_VerifyStatus m0 : 63|8@0+ (1,0) [0|255] ""  HIL_Tester
 SG_ PS_StatusA_03_01_Modes m0 : 55|8@0+ (1,0) [0|255] ""  HIL_Tester
 SG_ PS_StatusA_03_01_Enable m0 : 15|8@0+ (1,0) [0|255] ""  HIL_Tester
 SG_ PS_StatusA_03_01_VoltageActual m0 : 23|16@0+ (0.001,0) [0|32] ""  HIL_Tester
 SG_ PS_StatusA_03_01_CurrentActual m0 : 39|16@0+ (0.001,0) [0|32] ""  HIL_Tester
 SG_ PS_StatusA_03_02_VerifyStatus m1 : 63|8@0+ (1,0) [0|255] ""  HIL_Tester
 SG_ PS_StatusA_03_02_Modes m1 : 55|8@0+ (1,0) [0|255] ""  HIL_Tester
 SG_ PS_StatusA_03_02_Enable m1 : 15|8@0+ (1,0) [0|255] ""  HIL_Tester
 SG_ PS_StatusA_03_02_VoltageActual m1 : 23|16@0+ (0.001,0) [0|32] ""  HIL_Tester
 SG_ PS_StatusA_03_02_CurrentActual m1 : 39|16@0+ (0.001,0) [0|32] ""  HIL_Tester
 SG_ PS_StatusA_03_03_VerifyStatus m2 : 63|8@0+ (1,0) [0|255] ""  HIL_Tester
 SG_ PS_StatusA_03_03_Modes m2 : 55|8@0+ (1,0) [0|255] ""  HIL_Tester
 SG_ PS_StatusA_03_03_Enable m2 : 15|8@0+ (1,0) [0|255] ""  HIL_Tester
 SG_ PS_StatusA_03_03_VoltageActual m2 : 23|16@0+ (0.001,0) [0|32] ""  HIL_Tester
 SG_ PS_StatusA_03_03_CurrentActual m2 : 39|16@0+ (0.001,0) [0|32] ""  HIL_Tester
 SG_ PS_StatusA_03_04_VerifyStatus m3 : 63|8@0+ (1,0) [0|255] ""  HIL_Tester
 SG_ PS_StatusA_03_04_Modes m3 : 55|8@0+ (1,0) [0|255] ""  HIL_Tester
 SG_ PS_StatusA_03_04_Enable m3 : 15|8@0+ (1,0) [0|255] ""  HIL_Tester
 SG_ PS_StatusA_03_04_VoltageActual m3 : 23|16@0+ (0.001,0) [0|32] ""  HIL_Tester
 SG_ PS_StatusA_03_04_CurrentActual m3 : 39|16@0+ (0.001,0) [0|32] ""  HIL_Tester
 SG_ PS_StatusA_03_Channel M : 7|8@0- (1,0) [0|4] ""  HIL_Tester

BO_ 324 PS_StatusA_04: 8 HIL
 SG_ PS_StatusA_04_01_VerifyStatus m0 : 63|8@0+ (1,0) [0|255] ""  HIL_Tester
 SG_ PS_StatusA_04_01_Modes m0 : 55|8@0+ (1,0) [0|255] ""  HIL_Tester
 SG_ PS_StatusA_04_01_Enable m0 : 15|8@0+ (1,0) [0|255] ""  HIL_Tester
 SG_ PS_StatusA_04_01_VoltageActual m0 : 23|16@0+ (0.001,0) [0|32] ""  HIL_Tester
 SG_ PS_StatusA_04_01_CurrentActual m0 : 39|16@0+ (0.001,0) [0|32] ""  HIL_Tester
 SG_ PS_StatusA_04_02_VerifyStatus m1 : 63|8@0+ (1,0) [0|255] ""  HIL_Tester
 SG_ PS_StatusA_04_02_Modes m1 : 55|8@0+ (1,0) [0|255] ""  HIL_Tester
 SG_ PS_StatusA_04_02_Enable m1 : 15|8@0+ (1,0) [0|255] ""  HIL_Tester
 SG_ PS_StatusA_04_02_VoltageActual m1 : 23|16@0+ (0.001,0) [0|32] ""  HIL_Tester
 SG_ PS_StatusA_04_02_CurrentActual m1 : 39|16@0+ (0.001,0) [0|32] ""  HIL_Tester
 SG_ PS_StatusA_04_03_VerifyStatus m2 : 63|8@0+ (1,0) [0|255] ""  HIL_Tester
 SG_ PS_StatusA_04_03_Modes m2 : 55|8@0+ (1,0) [0|255] ""  HIL_Tester
 SG_ PS_StatusA_04_03_Enable m2 : 15|8@0+ (1,0) [0|255] ""  HIL_Tester
 SG_ PS_StatusA_04_03_VoltageActual m2 : 23|16@0+ (0.001,0) [0|32] ""  HIL_Tester
 SG_ PS_StatusA_04_03_CurrentActual m2 : 39|16@0+ (0.001,0) [0|32] ""  HIL_Tester
 SG_ PS_StatusA_04_04_VerifyStatus m3 : 63|8@0+ (1,0) [0|255] ""  HIL_Tester
 SG_ PS_StatusA_04_04_Modes m3 : 55|8@0+ (1,0) [0|255] ""  HIL_Tester
 SG_ PS_StatusA_04_04_Enable m3 : 15|8@0+ (1,0) [0|255] ""  HIL_Tester
 SG_ PS_StatusA_04_04_VoltageActual m3 : 23|16@0+ (0.001,0) [0|32] ""  HIL_Tester
 SG_ PS_StatusA_04_04_CurrentActual m3 : 39|16@0+ (0.001,0) [0|32] ""  HIL_Tester
 SG_ PS_StatusA_04_Channel M : 7|8@0- (1,0) [0|4] ""  HIL_Tester

BO_ 325 PS_StatusA_05: 8 HIL
 SG_ PS_StatusA_05_01_VerifyStatus m0 : 63|8@0+ (1,0) [0|255] ""  HIL_Tester
 SG_ PS_StatusA_05_01_Modes m0 : 55|8@0+ (1,0) [0|255] ""  HIL_Tester
 SG_ PS_StatusA_05_01_Enable m0 : 15|8@0+ (1,0) [0|255] ""  HIL_Tester
 SG_ PS_StatusA_05_01_VoltageActual m0 : 23|16@0+ (0.001,0) [0|32] ""  HIL_Tester
 SG_ PS_StatusA_05_01_CurrentActual m0 : 39|16@0+ (0.001,0) [0|32] ""  HIL_Tester
 SG_ PS_StatusA_05_02_VerifyStatus m1 : 63|8@0+ (1,0) [0|255] ""  HIL_Tester
 SG_ PS_StatusA_05_02_Modes m1 : 55|8@0+ (1,0) [0|255] ""  HIL_Tester
 SG_ PS_StatusA_05_02_Enable m1 : 15|8@0+ (1,0) [0|255] ""  HIL_Tester
 SG_ PS_StatusA_05_02_VoltageActual m1 : 23|16@0+ (0.001,0) [0|32] ""  HIL_Tester
 SG_ PS_StatusA_05_02_CurrentActual m1 : 39|16@0+ (0.001,0) [0|32] ""  HIL_Tester
 SG_ PS_StatusA_05_03_VerifyStatus m2 : 63|8@0+ (1,0) [0|255] ""  HIL_Tester
 SG_ PS_StatusA_05_03_Modes m2 : 55|8@0+ (1,0) [0|255] ""  HIL_Tester
 SG_ PS_StatusA_05_03_Enable m2 : 15|8@0+ (1,0) [0|255] ""  HIL_Tester
 SG_ PS_StatusA_05_03_VoltageActual m2 : 23|16@0+ (0.001,0) [0|32] ""  HIL_Tester
 SG_ PS_StatusA_05_03_CurrentActual m2 : 39|16@0+ (0.001,0) [0|32] ""  HIL_Tester
 SG_ PS_StatusA_05_04_VerifyStatus m3 : 63|8@0+ (1,0) [0|255] ""  HIL_Tester
 SG_ PS_StatusA_05_04_Modes m3 : 55|8@0+ (1,0) [0|255] ""  HIL_Tester
 SG_ PS_StatusA_05_04_Enable m3 : 15|8@0+ (1,0) [0|255] ""  HIL_Tester
 SG_ PS_StatusA_05_04_VoltageActual m3 : 23|16@0+ (0.001,0) [0|32] ""  HIL_Tester
 SG_ PS_StatusA_05_04_CurrentActual m3 : 39|16@0+ (0.001,0) [0|32] ""  HIL_Tester
 SG_ PS_StatusA_05_Channel M : 7|8@0- (1,0) [0|4] ""  HIL_Tester

BO_ 326 PS_StatusA_06: 8 HIL
 SG_ PS_StatusA_06_01_VerifyStatus m0 : 63|8@0+ (1,0) [0|255] ""  HIL_Tester
 SG_ PS_StatusA_06_01_Modes m0 : 55|8@0+ (1,0) [0|255] ""  HIL_Tester
 SG_ PS_StatusA_06_01_Enable m0 : 15|8@0+ (1,0) [0|255] ""  HIL_Tester
 SG_ PS_StatusA_06_01_VoltageActual m0 : 23|16@0+ (0.001,0) [0|32] ""  HIL_Tester
 SG_ PS_StatusA_06_01_CurrentActual m0 : 39|16@0+ (0.001,0) [0|32] ""  HIL_Tester
 SG_ PS_StatusA_06_02_VerifyStatus m1 : 63|8@0+ (1,0) [0|255] ""  HIL_Tester
 SG_ PS_StatusA_06_02_Modes m1 : 55|8@0+ (1,0) [0|255] ""  HIL_Tester
 SG_ PS_StatusA_06_02_Enable m1 : 15|8@0+ (1,0) [0|255] ""  HIL_Tester
 SG_ PS_StatusA_06_02_VoltageActual m1 : 23|16@0+ (0.001,0) [0|32] ""  HIL_Tester
 SG_ PS_StatusA_06_02_CurrentActual m1 : 39|16@0+ (0.001,0) [0|32] ""  HIL_Tester
 SG_ PS_StatusA_06_03_VerifyStatus m2 : 63|8@0+ (1,0) [0|255] ""  HIL_Tester
 SG_ PS_StatusA_06_03_Modes m2 : 55|8@0+ (1,0) [0|255] ""  HIL_Tester
 SG_ PS_StatusA_06_03_Enable m2 : 15|8@0+ (1,0) [0|255] ""  HIL_Tester
 SG_ PS_StatusA_06_03_VoltageActual m2 : 23|16@0+ (0.001,0) [0|32] ""  HIL_Tester
 SG_ PS_StatusA_06_03_CurrentActual m2 : 39|16@0+ (0.001,0) [0|32] ""  HIL_Tester
 SG_ PS_StatusA_06_04_VerifyStatus m3 : 63|8@0+ (1,0) [0|255] ""  HIL_Tester
 SG_ PS_StatusA_06_04_Modes m3 : 55|8@0+ (1,0) [0|255] ""  HIL_Tester
 SG_ PS_StatusA_06_04_Enable m3 : 15|8@0+ (1,0) [0|255] ""  HIL_Tester
 SG_ PS_StatusA_06_04_VoltageActual m3 : 23|16@0+ (0.001,0) [0|32] ""  HIL_Tester
 SG_ PS_StatusA_06_04_CurrentActual m3 : 39|16@0+ (0.001,0) [0|32] ""  HIL_Tester
 SG_ PS_StatusA_06_Channel M : 7|8@0- (1,0) [0|4] ""  HIL_Tester

BO_ 327 PS_StatusA_07: 8 HIL
 SG_ PS_StatusA_07_01_VerifyStatus m0 : 63|8@0+ (1,0) [0|255] ""  HIL_Tester
 SG_ PS_StatusA_07_01_Modes m0 : 55|8@0+ (1,0) [0|255] ""  HIL_Tester
 SG_ PS_StatusA_07_01_Enable m0 : 15|8@0+ (1,0) [0|255] ""  HIL_Tester
 SG_ PS_StatusA_07_01_VoltageActual m0 : 23|16@0+ (0.001,0) [0|32] ""  HIL_Tester
 SG_ PS_StatusA_07_01_CurrentActual m0 : 39|16@0+ (0.001,0) [0|32] ""  HIL_Tester
 SG_ PS_StatusA_07_02_VerifyStatus m1 : 63|8@0+ (1,0) [0|255] ""  HIL_Tester
 SG_ PS_StatusA_07_02_Modes m1 : 55|8@0+ (1,0) [0|255] ""  HIL_Tester
 SG_ PS_StatusA_07_02_Enable m1 : 15|8@0+ (1,0) [0|255] ""  HIL_Tester
 SG_ PS_StatusA_07_02_VoltageActual m1 : 23|16@0+ (0.001,0) [0|32] ""  HIL_Tester
 SG_ PS_StatusA_07_02_CurrentActual m1 : 39|16@0+ (0.001,0) [0|32] ""  HIL_Tester
 SG_ PS_StatusA_07_03_VerifyStatus m2 : 63|8@0+ (1,0) [0|255] ""  HIL_Tester
 SG_ PS_StatusA_07_03_Modes m2 : 55|8@0+ (1,0) [0|255] ""  HIL_Tester
 SG_ PS_StatusA_07_03_Enable m2 : 15|8@0+ (1,0) [0|255] ""  HIL_Tester
 SG_ PS_StatusA_07_03_VoltageActual m2 : 23|16@0+ (0.001,0) [0|32] ""  HIL_Tester
 SG_ PS_StatusA_07_03_CurrentActual m2 : 39|16@0+ (0.001,0) [0|32] ""  HIL_Tester
 SG_ PS_StatusA_07_04_VerifyStatus m3 : 63|8@0+ (1,0) [0|255] ""  HIL_Tester
 SG_ PS_StatusA_07_04_Modes m3 : 55|8@0+ (1,0) [0|255] ""  HIL_Tester
 SG_ PS_StatusA_07_04_Enable m3 : 15|8@0+ (1,0) [0|255] ""  HIL_Tester
 SG_ PS_StatusA_07_04_VoltageActual m3 : 23|16@0+ (0.001,0) [0|32] ""  HIL_Tester
 SG_ PS_StatusA_07_04_CurrentActual m3 : 39|16@0+ (0.001,0) [0|32] ""  HIL_Tester
 SG_ PS_StatusA_07_Channel M : 7|8@0- (1,0) [0|4] ""  HIL_Tester

BO_ 328 PS_StatusA_08: 8 HIL
 SG_ PS_StatusA_08_01_VerifyStatus m0 : 63|8@0+ (1,0) [0|255] ""  HIL_Tester
 SG_ PS_StatusA_08_01_Modes m0 : 55|8@0+ (1,0) [0|255] ""  HIL_Tester
 SG_ PS_StatusA_08_01_Enable m0 : 15|8@0+ (1,0) [0|255] ""  HIL_Tester
 SG_ PS_StatusA_08_01_VoltageActual m0 : 23|16@0+ (0.001,0) [0|32] ""  HIL_Tester
 SG_ PS_StatusA_08_01_CurrentActual m0 : 39|16@0+ (0.001,0) [0|32] ""  HIL_Tester
 SG_ PS_StatusA_08_02_VerifyStatus m1 : 63|8@0+ (1,0) [0|255] ""  HIL_Tester
 SG_ PS_StatusA_08_02_Modes m1 : 55|8@0+ (1,0) [0|255] ""  HIL_Tester
 SG_ PS_StatusA_08_02_Enable m1 : 15|8@0+ (1,0) [0|255] ""  HIL_Tester
 SG_ PS_StatusA_08_02_VoltageActual m1 : 23|16@0+ (0.001,0) [0|32] ""  HIL_Tester
 SG_ PS_StatusA_08_02_CurrentActual m1 : 39|16@0+ (0.001,0) [0|32] ""  HIL_Tester
 SG_ PS_StatusA_08_03_VerifyStatus m2 : 63|8@0+ (1,0) [0|255] ""  HIL_Tester
 SG_ PS_StatusA_08_03_Modes m2 : 55|8@0+ (1,0) [0|255] ""  HIL_Tester
 SG_ PS_StatusA_08_03_Enable m2 : 15|8@0+ (1,0) [0|255] ""  HIL_Tester
 SG_ PS_StatusA_08_03_VoltageActual m2 : 23|16@0+ (0.001,0) [0|32] ""  HIL_Tester
 SG_ PS_StatusA_08_03_CurrentActual m2 : 39|16@0+ (0.001,0) [0|32] ""  HIL_Tester
 SG_ PS_StatusA_08_04_VerifyStatus m3 : 63|8@0+ (1,0) [0|255] ""  HIL_Tester
 SG_ PS_StatusA_08_04_Modes m3 : 55|8@0+ (1,0) [0|255] ""  HIL_Tester
 SG_ PS_StatusA_08_04_Enable m3 : 15|8@0+ (1,0) [0|255] ""  HIL_Tester
 SG_ PS_StatusA_08_04_VoltageActual m3 : 23|16@0+ (0.001,0) [0|32] ""  HIL_Tester
 SG_ PS_StatusA_08_04_CurrentActual m3 : 39|16@0+ (0.001,0) [0|32] ""  HIL_Tester
 SG_ PS_StatusA_08_Channel M : 7|8@0- (1,0) [0|4] ""  HIL_Tester

BO_ 329 PS_StatusA_09: 8 HIL
 SG_ PS_StatusA_09_01_VerifyStatus m0 : 63|8@0+ (1,0) [0|255] ""  HIL_Tester
 SG_ PS_StatusA_09_01_Modes m0 : 55|8@0+ (1,0) [0|255] ""  HIL_Tester
 SG_ PS_StatusA_09_01_Enable m0 : 15|8@0+ (1,0) [0|255] ""  HIL_Tester
 SG_ PS_StatusA_09_01_VoltageActual m0 : 23|16@0+ (0.001,0) [0|32] ""  HIL_Tester
 SG_ PS_StatusA_09_01_CurrentActual m0 : 39|16@0+ (0.001,0) [0|32] ""  HIL_Tester
 SG_ PS_StatusA_09_02_VerifyStatus m1 : 63|8@0+ (1,0) [0|255] ""  HIL_Tester
 SG_ PS_StatusA_09_02_Modes m1 : 55|8@0+ (1,0) [0|255] ""  HIL_Tester
 SG_ PS_StatusA_09_02_Enable m1 : 15|8@0+ (1,0) [0|255] ""  HIL_Tester
 SG_ PS_StatusA_09_02_VoltageActual m1 : 23|16@0+ (0.001,0) [0|32] ""  HIL_Tester
 SG_ PS_StatusA_09_02_CurrentActual m1 : 39|16@0+ (0.001,0) [0|32] ""  HIL_Tester
 SG_ PS_StatusA_09_03_VerifyStatus m2 : 63|8@0+ (1,0) [0|255] ""  HIL_Tester
 SG_ PS_StatusA_09_03_Modes m2 : 55|8@0+ (1,0) [0|255] ""  HIL_Tester
 SG_ PS_StatusA_09_03_Enable m2 : 15|8@0+ (1,0) [0|255] ""  HIL_Tester
 SG_ PS_StatusA_09_03_VoltageActual m2 : 23|16@0+ (0.001,0) [0|32] ""  HIL_Tester
 SG_ PS_StatusA_09_03_CurrentActual m2 : 39|16@0+ (0.001,0) [0|32] ""  HIL_Tester
 SG_ PS_StatusA_09_04_VerifyStatus m3 : 63|8@0+ (1,0) [0|255] ""  HIL_Tester
 SG_ PS_StatusA_09_04_Modes m3 : 55|8@0+ (1,0) [0|255] ""  HIL_Tester
 SG_ PS_StatusA_09_04_Enable m3 : 15|8@0+ (1,0) [0|255] ""  HIL_Tester
 SG_ PS_StatusA_09_04_VoltageActual m3 : 23|16@0+ (0.001,0) [0|32] ""  HIL_Tester
 SG_ PS_StatusA_09_04_CurrentActual m3 : 39|16@0+ (0.001,0) [0|32] ""  HIL_Tester
 SG_ PS_StatusA_09_Channel M : 7|8@0- (1,0) [0|4] ""  HIL_Tester

BO_ 337 PS_StatusR_01: 8 HIL
 SG_ PS_StatusR_01_01_VerifyRequest m0 : 63|8@0+ (1,0) [0|255] ""  HIL_Tester
 SG_ PS_StatusR_01_01_Modes m0 : 55|8@0+ (1,0) [0|255] ""  HIL_Tester
 SG_ PS_StatusR_01_01_Enable m0 : 15|8@0+ (1,0) [0|255] ""  HIL_Tester
 SG_ PS_StatusR_01_01_VoltageTarget m0 : 23|16@0+ (0.001,0) [0|32] ""  HIL_Tester
 SG_ PS_StatusR_01_01_CurrentLimit m0 : 39|16@0+ (0.001,0) [0|32] ""  HIL_Tester
 SG_ PS_StatusR_01_02_VerifyRequest m1 : 63|8@0+ (1,0) [0|255] ""  HIL_Tester
 SG_ PS_StatusR_01_02_Modes m1 : 55|8@0+ (1,0) [0|255] ""  HIL_Tester
 SG_ PS_StatusR_01_02_Enable m1 : 15|8@0+ (1,0) [0|255] ""  HIL_Tester
 SG_ PS_StatusR_01_02_VoltageTarget m1 : 23|16@0+ (0.001,0) [0|32] ""  HIL_Tester
 SG_ PS_StatusR_01_02_CurrentLimit m1 : 39|16@0+ (0.001,0) [0|32] ""  HIL_Tester
 SG_ PS_StatusR_01_03_VerifyRequest m2 : 63|8@0+ (1,0) [0|255] ""  HIL_Tester
 SG_ PS_StatusR_01_03_Modes m2 : 55|8@0+ (1,0) [0|255] ""  HIL_Tester
 SG_ PS_StatusR_01_03_Enable m2 : 15|8@0+ (1,0) [0|255] ""  HIL_Tester
 SG_ PS_StatusR_01_03_VoltageTarget m2 : 23|16@0+ (0.001,0) [0|32] ""  HIL_Tester
 SG_ PS_StatusR_01_03_CurrentLimit m2 : 39|16@0+ (0.001,0) [0|32] ""  HIL_Tester
 SG_ PS_StatusR_01_04_VerifyRequest m3 : 63|8@0+ (1,0) [0|255] ""  HIL_Tester
 SG_ PS_StatusR_01_04_Modes m3 : 55|8@0+ (1,0) [0|255] ""  HIL_Tester
 SG_ PS_StatusR_01_04_Enable m3 : 15|8@0+ (1,0) [0|255] ""  HIL_Tester
 SG_ PS_StatusR_01_04_VoltageTarget m3 : 23|16@0+ (0.001,0) [0|32] ""  HIL_Tester
 SG_ PS_StatusR_01_04_CurrentLimit m3 : 39|16@0+ (0.001,0) [0|32] ""  HIL_Tester
 SG_ PS_StatusR_01_Channel M : 7|8@0- (1,0) [0|4] ""  HIL_Tester

BO_ 338 PS_StatusR_02: 8 HIL
 SG_ PS_StatusR_02_01_VerifyRequest m0 : 63|8@0+ (1,0) [0|255] ""  HIL_Tester
 SG_ PS_StatusR_02_01_Modes m0 : 55|8@0+ (1,0) [0|255] ""  HIL_Tester
 SG_ PS_StatusR_02_01_Enable m0 : 15|8@0+ (1,0) [0|255] ""  HIL_Tester
 SG_ PS_StatusR_02_01_VoltageTarget m0 : 23|16@0+ (0.001,0) [0|32] ""  HIL_Tester
 SG_ PS_StatusR_02_01_CurrentLimit m0 : 39|16@0+ (0.001,0) [0|32] ""  HIL_Tester
 SG_ PS_StatusR_02_02_VerifyRequest m1 : 63|8@0+ (1,0) [0|255] ""  HIL_Tester
 SG_ PS_StatusR_02_02_Modes m1 : 55|8@0+ (1,0) [0|255] ""  HIL_Tester
 SG_ PS_StatusR_02_02_Enable m1 : 15|8@0+ (1,0) [0|255] ""  HIL_Tester
 SG_ PS_StatusR_02_02_VoltageTarget m1 : 23|16@0+ (0.001,0) [0|32] ""  HIL_Tester
 SG_ PS_StatusR_02_02_CurrentLimit m1 : 39|16@0+ (0.001,0) [0|32] ""  HIL_Tester
 SG_ PS_StatusR_02_03_VerifyRequest m2 : 63|8@0+ (1,0) [0|255] ""  HIL_Tester
 SG_ PS_StatusR_02_03_Modes m2 : 55|8@0+ (1,0) [0|255] ""  HIL_Tester
 SG_ PS_StatusR_02_03_Enable m2 : 15|8@0+ (1,0) [0|255] ""  HIL_Tester
 SG_ PS_StatusR_02_03_VoltageTarget m2 : 23|16@0+ (0.001,0) [0|32] ""  HIL_Tester
 SG_ PS_StatusR_02_03_CurrentLimit m2 : 39|16@0+ (0.001,0) [0|32] ""  HIL_Tester
 SG_ PS_StatusR_02_04_VerifyRequest m3 : 63|8@0+ (1,0) [0|255] ""  HIL_Tester
 SG_ PS_StatusR_02_04_Modes m3 : 55|8@0+ (1,0) [0|255] ""  HIL_Tester
 SG_ PS_StatusR_02_04_Enable m3 : 15|8@0+ (1,0) [0|255] ""  HIL_Tester
 SG_ PS_StatusR_02_04_VoltageTarget m3 : 23|16@0+ (0.001,0) [0|32] ""  HIL_Tester
 SG_ PS_StatusR_02_04_CurrentLimit m3 : 39|16@0+ (0.001,0) [0|32] ""  HIL_Tester
 SG_ PS_StatusR_02_Channel M : 7|8@0- (1,0) [0|4] ""  HIL_Tester

BO_ 339 PS_StatusR_03: 8 HIL
 SG_ PS_StatusR_03_01_VerifyRequest m0 : 63|8@0+ (1,0) [0|255] ""  HIL_Tester
 SG_ PS_StatusR_03_01_Modes m0 : 55|8@0+ (1,0) [0|255] ""  HIL_Tester
 SG_ PS_StatusR_03_01_Enable m0 : 15|8@0+ (1,0) [0|255] ""  HIL_Tester
 SG_ PS_StatusR_03_01_VoltageTarget m0 : 23|16@0+ (0.001,0) [0|32] ""  HIL_Tester
 SG_ PS_StatusR_03_01_CurrentLimit m0 : 39|16@0+ (0.001,0) [0|32] ""  HIL_Tester
 SG_ PS_StatusR_03_02_VerifyRequest m1 : 63|8@0+ (1,0) [0|255] ""  HIL_Tester
 SG_ PS_StatusR_03_02_Modes m1 : 55|8@0+ (1,0) [0|255] ""  HIL_Tester
 SG_ PS_StatusR_03_02_Enable m1 : 15|8@0+ (1,0) [0|255] ""  HIL_Tester
 SG_ PS_StatusR_03_02_VoltageTarget m1 : 23|16@0+ (0.001,0) [0|32] ""  HIL_Tester
 SG_ PS_StatusR_03_02_CurrentLimit m1 : 39|16@0+ (0.001,0) [0|32] ""  HIL_Tester
 SG_ PS_StatusR_03_03_VerifyRequest m2 : 63|8@0+ (1,0) [0|255] ""  HIL_Tester
 SG_ PS_StatusR_03_03_Modes m2 : 55|8@0+ (1,0) [0|255] ""  HIL_Tester
 SG_ PS_StatusR_03_03_Enable m2 : 15|8@0+ (1,0) [0|255] ""  HIL_Tester
 SG_ PS_StatusR_03_03_VoltageTarget m2 : 23|16@0+ (0.001,0) [0|32] ""  HIL_Tester
 SG_ PS_StatusR_03_03_CurrentLimit m2 : 39|16@0+ (0.001,0) [0|32] ""  HIL_Tester
 SG_ PS_StatusR_03_04_VerifyRequest m3 : 63|8@0+ (1,0) [0|255] ""  HIL_Tester
 SG_ PS_StatusR_03_04_Modes m3 : 55|8@0+ (1,0) [0|255] ""  HIL_Tester
 SG_ PS_StatusR_03_04_Enable m3 : 15|8@0+ (1,0) [0|255] ""  HIL_Tester
 SG_ PS_StatusR_03_04_VoltageTarget m3 : 23|16@0+ (0.001,0) [0|32] ""  HIL_Tester
 SG_ PS_StatusR_03_04_CurrentLimit m3 : 39|16@0+ (0.001,0) [0|32] ""  HIL_Tester
 SG_ PS_StatusR_03_Channel M : 7|8@0- (1,0) [0|4] ""  HIL_Tester

BO_ 340 PS_StatusR_04: 8 HIL
 SG_ PS_StatusR_04_01_VerifyRequest m0 : 63|8@0+ (1,0) [0|255] ""  HIL_Tester
 SG_ PS_StatusR_04_01_Modes m0 : 55|8@0+ (1,0) [0|255] ""  HIL_Tester
 SG_ PS_StatusR_04_01_Enable m0 : 15|8@0+ (1,0) [0|255] ""  HIL_Tester
 SG_ PS_StatusR_04_01_VoltageTarget m0 : 23|16@0+ (0.001,0) [0|32] ""  HIL_Tester
 SG_ PS_StatusR_04_01_CurrentLimit m0 : 39|16@0+ (0.001,0) [0|32] ""  HIL_Tester
 SG_ PS_StatusR_04_02_VerifyRequest m1 : 63|8@0+ (1,0) [0|255] ""  HIL_Tester
 SG_ PS_StatusR_04_02_Modes m1 : 55|8@0+ (1,0) [0|255] ""  HIL_Tester
 SG_ PS_StatusR_04_02_Enable m1 : 15|8@0+ (1,0) [0|255] ""  HIL_Tester
 SG_ PS_StatusR_04_02_VoltageTarget m1 : 23|16@0+ (0.001,0) [0|32] ""  HIL_Tester
 SG_ PS_StatusR_04_02_CurrentLimit m1 : 39|16@0+ (0.001,0) [0|32] ""  HIL_Tester
 SG_ PS_StatusR_04_03_VerifyRequest m2 : 63|8@0+ (1,0) [0|255] ""  HIL_Tester
 SG_ PS_StatusR_04_03_Modes m2 : 55|8@0+ (1,0) [0|255] ""  HIL_Tester
 SG_ PS_StatusR_04_03_Enable m2 : 15|8@0+ (1,0) [0|255] ""  HIL_Tester
 SG_ PS_StatusR_04_03_VoltageTarget m2 : 23|16@0+ (0.001,0) [0|32] ""  HIL_Tester
 SG_ PS_StatusR_04_03_CurrentLimit m2 : 39|16@0+ (0.001,0) [0|32] ""  HIL_Tester
 SG_ PS_StatusR_04_04_VerifyRequest m3 : 63|8@0+ (1,0) [0|255] ""  HIL_Tester
 SG_ PS_StatusR_04_04_Modes m3 : 55|8@0+ (1,0) [0|255] ""  HIL_Tester
 SG_ PS_StatusR_04_04_Enable m3 : 15|8@0+ (1,0) [0|255] ""  HIL_Tester
 SG_ PS_StatusR_04_04_VoltageTarget m3 : 23|16@0+ (0.001,0) [0|32] ""  HIL_Tester
 SG_ PS_StatusR_04_04_CurrentLimit m3 : 39|16@0+ (0.001,0) [0|32] ""  HIL_Tester
 SG_ PS_StatusR_04_Channel M : 7|8@0- (1,0) [0|4] ""  HIL_Tester

BO_ 341 PS_StatusR_05: 8 HIL
 SG_ PS_StatusR_05_01_VerifyRequest m0 : 63|8@0+ (1,0) [0|255] ""  HIL_Tester
 SG_ PS_StatusR_05_01_Modes m0 : 55|8@0+ (1,0) [0|255] ""  HIL_Tester
 SG_ PS_StatusR_05_01_Enable m0 : 15|8@0+ (1,0) [0|255] ""  HIL_Tester
 SG_ PS_StatusR_05_01_VoltageTarget m0 : 23|16@0+ (0.001,0) [0|32] ""  HIL_Tester
 SG_ PS_StatusR_05_01_CurrentLimit m0 : 39|16@0+ (0.001,0) [0|32] ""  HIL_Tester
 SG_ PS_StatusR_05_02_VerifyRequest m1 : 63|8@0+ (1,0) [0|255] ""  HIL_Tester
 SG_ PS_StatusR_05_02_Modes m1 : 55|8@0+ (1,0) [0|255] ""  HIL_Tester
 SG_ PS_StatusR_05_02_Enable m1 : 15|8@0+ (1,0) [0|255] ""  HIL_Tester
 SG_ PS_StatusR_05_02_VoltageTarget m1 : 23|16@0+ (0.001,0) [0|32] ""  HIL_Tester
 SG_ PS_StatusR_05_02_CurrentLimit m1 : 39|16@0+ (0.001,0) [0|32] ""  HIL_Tester
 SG_ PS_StatusR_05_03_VerifyRequest m2 : 63|8@0+ (1,0) [0|255] ""  HIL_Tester
 SG_ PS_StatusR_05_03_Modes m2 : 55|8@0+ (1,0) [0|255] ""  HIL_Tester
 SG_ PS_StatusR_05_03_Enable m2 : 15|8@0+ (1,0) [0|255] ""  HIL_Tester
 SG_ PS_StatusR_05_03_VoltageTarget m2 : 23|16@0+ (0.001,0) [0|32] ""  HIL_Tester
 SG_ PS_StatusR_05_03_CurrentLimit m2 : 39|16@0+ (0.001,0) [0|32] ""  HIL_Tester
 SG_ PS_StatusR_05_04_VerifyRequest m3 : 63|8@0+ (1,0) [0|255] ""  HIL_Tester
 SG_ PS_StatusR_05_04_Modes m3 : 55|8@0+ (1,0) [0|255] ""  HIL_Tester
 SG_ PS_StatusR_05_04_Enable m3 : 15|8@0+ (1,0) [0|255] ""  HIL_Tester
 SG_ PS_StatusR_05_04_VoltageTarget m3 : 23|16@0+ (0.001,0) [0|32] ""  HIL_Tester
 SG_ PS_StatusR_05_04_CurrentLimit m3 : 39|16@0+ (0.001,0) [0|32] ""  HIL_Tester
 SG_ PS_StatusR_05_Channel M : 7|8@0- (1,0) [0|4] ""  HIL_Tester

BO_ 342 PS_StatusR_06: 8 HIL
 SG_ PS_StatusR_06_01_VerifyRequest m0 : 63|8@0+ (1,0) [0|255] ""  HIL_Tester
 SG_ PS_StatusR_06_01_Modes m0 : 55|8@0+ (1,0) [0|255] ""  HIL_Tester
 SG_ PS_StatusR_06_01_Enable m0 : 15|8@0+ (1,0) [0|255] ""  HIL_Tester
 SG_ PS_StatusR_06_01_VoltageTarget m0 : 23|16@0+ (0.001,0) [0|32] ""  HIL_Tester
 SG_ PS_StatusR_06_01_CurrentLimit m0 : 39|16@0+ (0.001,0) [0|32] ""  HIL_Tester
 SG_ PS_StatusR_06_02_VerifyRequest m1 : 63|8@0+ (1,0) [0|255] ""  HIL_Tester
 SG_ PS_StatusR_06_02_Modes m1 : 55|8@0+ (1,0) [0|255] ""  HIL_Tester
 SG_ PS_StatusR_06_02_Enable m1 : 15|8@0+ (1,0) [0|255] ""  HIL_Tester
 SG_ PS_StatusR_06_02_VoltageTarget m1 : 23|16@0+ (0.001,0) [0|32] ""  HIL_Tester
 SG_ PS_StatusR_06_02_CurrentLimit m1 : 39|16@0+ (0.001,0) [0|32] ""  HIL_Tester
 SG_ PS_StatusR_06_03_VerifyRequest m2 : 63|8@0+ (1,0) [0|255] ""  HIL_Tester
 SG_ PS_StatusR_06_03_Modes m2 : 55|8@0+ (1,0) [0|255] ""  HIL_Tester
 SG_ PS_StatusR_06_03_Enable m2 : 15|8@0+ (1,0) [0|255] ""  HIL_Tester
 SG_ PS_StatusR_06_03_VoltageTarget m2 : 23|16@0+ (0.001,0) [0|32] ""  HIL_Tester
 SG_ PS_StatusR_06_03_CurrentLimit m2 : 39|16@0+ (0.001,0) [0|32] ""  HIL_Tester
 SG_ PS_StatusR_06_04_VerifyRequest m3 : 63|8@0+ (1,0) [0|255] ""  HIL_Tester
 SG_ PS_StatusR_06_04_Modes m3 : 55|8@0+ (1,0) [0|255] ""  HIL_Tester
 SG_ PS_StatusR_06_04_Enable m3 : 15|8@0+ (1,0) [0|255] ""  HIL_Tester
 SG_ PS_StatusR_06_04_VoltageTarget m3 : 23|16@0+ (0.001,0) [0|32] ""  HIL_Tester
 SG_ PS_StatusR_06_04_CurrentLimit m3 : 39|16@0+ (0.001,0) [0|32] ""  HIL_Tester
 SG_ PS_StatusR_06_Channel M : 7|8@0- (1,0) [0|4] ""  HIL_Tester

BO_ 343 PS_StatusR_07: 8 HIL
 SG_ PS_StatusR_07_01_VerifyRequest m0 : 63|8@0+ (1,0) [0|255] ""  HIL_Tester
 SG_ PS_StatusR_07_01_Modes m0 : 55|8@0+ (1,0) [0|255] ""  HIL_Tester
 SG_ PS_StatusR_07_01_Enable m0 : 15|8@0+ (1,0) [0|255] ""  HIL_Tester
 SG_ PS_StatusR_07_01_VoltageTarget m0 : 23|16@0+ (0.001,0) [0|32] ""  HIL_Tester
 SG_ PS_StatusR_07_01_CurrentLimit m0 : 39|16@0+ (0.001,0) [0|32] ""  HIL_Tester
 SG_ PS_StatusR_07_02_VerifyRequest m1 : 63|8@0+ (1,0) [0|255] ""  HIL_Tester
 SG_ PS_StatusR_07_02_Modes m1 : 55|8@0+ (1,0) [0|255] ""  HIL_Tester
 SG_ PS_StatusR_07_02_Enable m1 : 15|8@0+ (1,0) [0|255] ""  HIL_Tester
 SG_ PS_StatusR_07_02_VoltageTarget m1 : 23|16@0+ (0.001,0) [0|32] ""  HIL_Tester
 SG_ PS_StatusR_07_02_CurrentLimit m1 : 39|16@0+ (0.001,0) [0|32] ""  HIL_Tester
 SG_ PS_StatusR_07_03_VerifyRequest m2 : 63|8@0+ (1,0) [0|255] ""  HIL_Tester
 SG_ PS_StatusR_07_03_Modes m2 : 55|8@0+ (1,0) [0|255] ""  HIL_Tester
 SG_ PS_StatusR_07_03_Enable m2 : 15|8@0+ (1,0) [0|255] ""  HIL_Tester
 SG_ PS_StatusR_07_03_VoltageTarget m2 : 23|16@0+ (0.001,0) [0|32] ""  HIL_Tester
 SG_ PS_StatusR_07_03_CurrentLimit m2 : 39|16@0+ (0.001,0) [0|32] ""  HIL_Tester
 SG_ PS_StatusR_07_04_VerifyRequest m3 : 63|8@0+ (1,0) [0|255] ""  HIL_Tester
 SG_ PS_StatusR_07_04_Modes m3 : 55|8@0+ (1,0) [0|255] ""  HIL_Tester
 SG_ PS_StatusR_07_04_Enable m3 : 15|8@0+ (1,0) [0|255] ""  HIL_Tester
 SG_ PS_StatusR_07_04_VoltageTarget m3 : 23|16@0+ (0.001,0) [0|32] ""  HIL_Tester
 SG_ PS_StatusR_07_04_CurrentLimit m3 : 39|16@0+ (0.001,0) [0|32] ""  HIL_Tester
 SG_ PS_StatusR_07_Channel M : 7|8@0- (1,0) [0|4] ""  HIL_Tester

BO_ 344 PS_StatusR_08: 8 HIL
 SG_ PS_StatusR_08_01_VerifyRequest m0 : 63|8@0+ (1,0) [0|255] ""  HIL_Tester
 SG_ PS_StatusR_08_01_Modes m0 : 55|8@0+ (1,0) [0|255] ""  HIL_Tester
 SG_ PS_StatusR_08_01_Enable m0 : 15|8@0+ (1,0) [0|255] ""  HIL_Tester
 SG_ PS_StatusR_08_01_VoltageTarget m0 : 23|16@0+ (0.001,0) [0|32] ""  HIL_Tester
 SG_ PS_StatusR_08_01_CurrentLimit m0 : 39|16@0+ (0.001,0) [0|32] ""  HIL_Tester
 SG_ PS_StatusR_08_02_VerifyRequest m1 : 63|8@0+ (1,0) [0|255] ""  HIL_Tester
 SG_ PS_StatusR_08_02_Modes m1 : 55|8@0+ (1,0) [0|255] ""  HIL_Tester
 SG_ PS_StatusR_08_02_Enable m1 : 15|8@0+ (1,0) [0|255] ""  HIL_Tester
 SG_ PS_StatusR_08_02_VoltageTarget m1 : 23|16@0+ (0.001,0) [0|32] ""  HIL_Tester
 SG_ PS_StatusR_08_02_CurrentLimit m1 : 39|16@0+ (0.001,0) [0|32] ""  HIL_Tester
 SG_ PS_StatusR_08_03_VerifyRequest m2 : 63|8@0+ (1,0) [0|255] ""  HIL_Tester
 SG_ PS_StatusR_08_03_Modes m2 : 55|8@0+ (1,0) [0|255] ""  HIL_Tester
 SG_ PS_StatusR_08_03_Enable m2 : 15|8@0+ (1,0) [0|255] ""  HIL_Tester
 SG_ PS_StatusR_08_03_VoltageTarget m2 : 23|16@0+ (0.001,0) [0|32] ""  HIL_Tester
 SG_ PS_StatusR_08_03_CurrentLimit m2 : 39|16@0+ (0.001,0) [0|32] ""  HIL_Tester
 SG_ PS_StatusR_08_04_VerifyRequest m3 : 63|8@0+ (1,0) [0|255] ""  HIL_Tester
 SG_ PS_StatusR_08_04_Modes m3 : 55|8@0+ (1,0) [0|255] ""  HIL_Tester
 SG_ PS_StatusR_08_04_Enable m3 : 15|8@0+ (1,0) [0|255] ""  HIL_Tester
 SG_ PS_StatusR_08_04_VoltageTarget m3 : 23|16@0+ (0.001,0) [0|32] ""  HIL_Tester
 SG_ PS_StatusR_08_04_CurrentLimit m3 : 39|16@0+ (0.001,0) [0|32] ""  HIL_Tester
 SG_ PS_StatusR_08_Channel M : 7|8@0- (1,0) [0|4] ""  HIL_Tester

BO_ 345 PS_StatusR_09: 8 HIL
 SG_ PS_StatusR_09_01_VerifyRequest m0 : 63|8@0+ (1,0) [0|255] ""  HIL_Tester
 SG_ PS_StatusR_09_01_Modes m0 : 55|8@0+ (1,0) [0|255] ""  HIL_Tester
 SG_ PS_StatusR_09_01_Enable m0 : 15|8@0+ (1,0) [0|255] ""  HIL_Tester
 SG_ PS_StatusR_09_01_VoltageTarget m0 : 23|16@0+ (0.001,0) [0|32] ""  HIL_Tester
 SG_ PS_StatusR_09_01_CurrentLimit m0 : 39|16@0+ (0.001,0) [0|32] ""  HIL_Tester
 SG_ PS_StatusR_09_02_VerifyRequest m1 : 63|8@0+ (1,0) [0|255] ""  HIL_Tester
 SG_ PS_StatusR_09_02_Modes m1 : 55|8@0+ (1,0) [0|255] ""  HIL_Tester
 SG_ PS_StatusR_09_02_Enable m1 : 15|8@0+ (1,0) [0|255] ""  HIL_Tester
 SG_ PS_StatusR_09_02_VoltageTarget m1 : 23|16@0+ (0.001,0) [0|32] ""  HIL_Tester
 SG_ PS_StatusR_09_02_CurrentLimit m1 : 39|16@0+ (0.001,0) [0|32] ""  HIL_Tester
 SG_ PS_StatusR_09_03_VerifyRequest m2 : 63|8@0+ (1,0) [0|255] ""  HIL_Tester
 SG_ PS_StatusR_09_03_Modes m2 : 55|8@0+ (1,0) [0|255] ""  HIL_Tester
 SG_ PS_StatusR_09_03_Enable m2 : 15|8@0+ (1,0) [0|255] ""  HIL_Tester
 SG_ PS_StatusR_09_03_VoltageTarget m2 : 23|16@0+ (0.001,0) [0|32] ""  HIL_Tester
 SG_ PS_StatusR_09_03_CurrentLimit m2 : 39|16@0+ (0.001,0) [0|32] ""  HIL_Tester
 SG_ PS_StatusR_09_04_VerifyRequest m3 : 63|8@0+ (1,0) [0|255] ""  HIL_Tester
 SG_ PS_StatusR_09_04_Modes m3 : 55|8@0+ (1,0) [0|255] ""  HIL_Tester
 SG_ PS_StatusR_09_04_Enable m3 : 15|8@0+ (1,0) [0|255] ""  HIL_Tester
 SG_ PS_StatusR_09_04_VoltageTarget m3 : 23|16@0+ (0.001,0) [0|32] ""  HIL_Tester
 SG_ PS_StatusR_09_04_CurrentLimit m3 : 39|16@0+ (0.001,0) [0|32] ""  HIL_Tester
 SG_ PS_StatusR_09_Channel M : 7|8@0- (1,0) [0|4] ""  HIL_Tester

BO_ 593 PS_Cntrl_01: 8 HIL_Tester
 SG_ PS_Cntrl_01_01_VerifyRequest m0 : 63|8@0+ (1,0) [0|255] ""  HIL
 SG_ PS_Cntrl_01_01_Modes m0 : 55|8@0+ (1,0) [0|255] ""  HIL
 SG_ PS_Cntrl_01_01_Enable m0 : 15|8@0+ (1,0) [0|255] ""  HIL
 SG_ PS_Cntrl_01_01_VoltageTarget m0 : 23|16@0+ (0.001,0) [0|32] ""  HIL
 SG_ PS_Cntrl_01_01_CurrentLimit m0 : 39|16@0+ (0.001,0) [0|32] ""  HIL
 SG_ PS_Cntrl_01_02_VerifyRequest m1 : 63|8@0+ (1,0) [0|255] ""  HIL
 SG_ PS_Cntrl_01_02_Modes m1 : 55|8@0+ (1,0) [0|255] ""  HIL
 SG_ PS_Cntrl_01_02_Enable m1 : 15|8@0+ (1,0) [0|255] ""  HIL
 SG_ PS_Cntrl_01_02_VoltageTarget m1 : 23|16@0+ (0.001,0) [0|32] ""  HIL
 SG_ PS_Cntrl_01_02_CurrentLimit m1 : 39|16@0+ (0.001,0) [0|32] ""  HIL
 SG_ PS_Cntrl_01_03_VerifyRequest m2 : 63|8@0+ (1,0) [0|255] ""  HIL
 SG_ PS_Cntrl_01_03_Modes m2 : 55|8@0+ (1,0) [0|255] ""  HIL
 SG_ PS_Cntrl_01_03_Enable m2 : 15|8@0+ (1,0) [0|255] ""  HIL
 SG_ PS_Cntrl_01_03_VoltageTarget m2 : 23|16@0+ (0.001,0) [0|32] ""  HIL
 SG_ PS_Cntrl_01_03_CurrentLimit m2 : 39|16@0+ (0.001,0) [0|32] ""  HIL
 SG_ PS_Cntrl_01_04_VerifyRequest m3 : 63|8@0+ (1,0) [0|255] ""  HIL
 SG_ PS_Cntrl_01_04_Modes m3 : 55|8@0+ (1,0) [0|255] ""  HIL
 SG_ PS_Cntrl_01_04_Enable m3 : 15|8@0+ (1,0) [0|255] ""  HIL
 SG_ PS_Cntrl_01_04_VoltageTarget m3 : 23|16@0+ (0.001,0) [0|32] "V"  HIL
 SG_ PS_Cntrl_01_04_CurrentLimit m3 : 39|16@0+ (0.001,0) [0|32] "A"  HIL
 SG_ PS_Cntrl_01_Channel M : 7|8@0- (1,0) [0|4] ""  HIL

BO_ 594 PS_Cntrl_02: 8 HIL_Tester
 SG_ PS_Cntrl_02_01_VerifyRequest m0 : 63|8@0+ (1,0) [0|255] ""  HIL
 SG_ PS_Cntrl_02_01_Modes m0 : 55|8@0+ (1,0) [0|255] ""  HIL
 SG_ PS_Cntrl_02_01_Enable m0 : 15|8@0+ (1,0) [0|255] ""  HIL
 SG_ PS_Cntrl_02_01_VoltageTarget m0 : 23|16@0+ (0.001,0) [0|32] ""  HIL
 SG_ PS_Cntrl_02_01_CurrentLimit m0 : 39|16@0+ (0.001,0) [0|32] ""  HIL
 SG_ PS_Cntrl_02_02_VerifyRequest m1 : 63|8@0+ (1,0) [0|255] ""  HIL
 SG_ PS_Cntrl_02_02_Modes m1 : 55|8@0+ (1,0) [0|255] ""  HIL
 SG_ PS_Cntrl_02_02_Enable m1 : 15|8@0+ (1,0) [0|255] ""  HIL
 SG_ PS_Cntrl_02_02_VoltageTarget m1 : 23|16@0+ (0.001,0) [0|32] ""  HIL
 SG_ PS_Cntrl_02_02_CurrentLimit m1 : 39|16@0+ (0.001,0) [0|32] ""  HIL
 SG_ PS_Cntrl_02_03_VerifyRequest m2 : 63|8@0+ (1,0) [0|255] ""  HIL
 SG_ PS_Cntrl_02_03_Modes m2 : 55|8@0+ (1,0) [0|255] ""  HIL
 SG_ PS_Cntrl_02_03_Enable m2 : 15|8@0+ (1,0) [0|255] ""  HIL
 SG_ PS_Cntrl_02_03_VoltageTarget m2 : 23|16@0+ (0.001,0) [0|32] ""  HIL
 SG_ PS_Cntrl_02_03_CurrentLimit m2 : 39|16@0+ (0.001,0) [0|32] ""  HIL
 SG_ PS_Cntrl_02_04_VerifyRequest m3 : 63|8@0+ (1,0) [0|255] ""  HIL
 SG_ PS_Cntrl_02_04_Modes m3 : 55|8@0+ (1,0) [0|255] ""  HIL
 SG_ PS_Cntrl_02_04_Enable m3 : 15|8@0+ (1,0) [0|255] ""  HIL
 SG_ PS_Cntrl_02_04_VoltageTarget m3 : 23|16@0+ (0.001,0) [0|32] ""  HIL
 SG_ PS_Cntrl_02_04_CurrentLimit m3 : 39|16@0+ (0.001,0) [0|32] ""  HIL
 SG_ PS_Cntrl_02_Channel M : 7|8@0- (1,0) [0|4] ""  HIL

BO_ 595 PS_Cntrl_03: 8 HIL_Tester
 SG_ PS_Cntrl_03_01_VerifyRequest m0 : 63|8@0+ (1,0) [0|255] ""  HIL
 SG_ PS_Cntrl_03_01_Modes m0 : 55|8@0+ (1,0) [0|255] ""  HIL
 SG_ PS_Cntrl_03_01_Enable m0 : 15|8@0+ (1,0) [0|255] ""  HIL
 SG_ PS_Cntrl_03_01_VoltageTarget m0 : 23|16@0+ (0.001,0) [0|32] ""  HIL
 SG_ PS_Cntrl_03_01_CurrentLimit m0 : 39|16@0+ (0.001,0) [0|32] ""  HIL
 SG_ PS_Cntrl_03_02_VerifyRequest m1 : 63|8@0+ (1,0) [0|255] ""  HIL
 SG_ PS_Cntrl_03_02_Modes m1 : 55|8@0+ (1,0) [0|255] ""  HIL
 SG_ PS_Cntrl_03_02_Enable m1 : 15|8@0+ (1,0) [0|255] ""  HIL
 SG_ PS_Cntrl_03_02_VoltageTarget m1 : 23|16@0+ (0.001,0) [0|32] ""  HIL
 SG_ PS_Cntrl_03_02_CurrentLimit m1 : 39|16@0+ (0.001,0) [0|32] ""  HIL
 SG_ PS_Cntrl_03_03_VerifyRequest m2 : 63|8@0+ (1,0) [0|255] ""  HIL
 SG_ PS_Cntrl_03_03_Modes m2 : 55|8@0+ (1,0) [0|255] ""  HIL
 SG_ PS_Cntrl_03_03_Enable m2 : 15|8@0+ (1,0) [0|255] ""  HIL
 SG_ PS_Cntrl_03_03_VoltageTarget m2 : 23|16@0+ (0.001,0) [0|32] ""  HIL
 SG_ PS_Cntrl_03_03_CurrentLimit m2 : 39|16@0+ (0.001,0) [0|32] ""  HIL
 SG_ PS_Cntrl_03_04_VerifyRequest m3 : 63|8@0+ (1,0) [0|255] ""  HIL
 SG_ PS_Cntrl_03_04_Modes m3 : 55|8@0+ (1,0) [0|255] ""  HIL
 SG_ PS_Cntrl_03_04_Enable m3 : 15|8@0+ (1,0) [0|255] ""  HIL
 SG_ PS_Cntrl_03_04_VoltageTarget m3 : 23|16@0+ (0.001,0) [0|32] ""  HIL
 SG_ PS_Cntrl_03_04_CurrentLimit m3 : 39|16@0+ (0.001,0) [0|32] ""  HIL
 SG_ PS_Cntrl_03_Channel M : 7|8@0- (1,0) [0|4] ""  HIL

BO_ 596 PS_Cntrl_04: 8 HIL_Tester
 SG_ PS_Cntrl_04_01_VerifyRequest m0 : 63|8@0+ (1,0) [0|255] ""  HIL
 SG_ PS_Cntrl_04_01_Modes m0 : 55|8@0+ (1,0) [0|255] ""  HIL
 SG_ PS_Cntrl_04_01_Enable m0 : 15|8@0+ (1,0) [0|255] ""  HIL
 SG_ PS_Cntrl_04_01_VoltageTarget m0 : 23|16@0+ (0.001,0) [0|32] ""  HIL
 SG_ PS_Cntrl_04_01_CurrentLimit m0 : 39|16@0+ (0.001,0) [0|32] ""  HIL
 SG_ PS_Cntrl_04_02_VerifyRequest m1 : 63|8@0+ (1,0) [0|255] ""  HIL
 SG_ PS_Cntrl_04_02_Modes m1 : 55|8@0+ (1,0) [0|255] ""  HIL
 SG_ PS_Cntrl_04_02_Enable m1 : 15|8@0+ (1,0) [0|255] ""  HIL
 SG_ PS_Cntrl_04_02_VoltageTarget m1 : 23|16@0+ (0.001,0) [0|32] ""  HIL
 SG_ PS_Cntrl_04_02_CurrentLimit m1 : 39|16@0+ (0.001,0) [0|32] ""  HIL
 SG_ PS_Cntrl_04_03_VerifyRequest m2 : 63|8@0+ (1,0) [0|255] ""  HIL
 SG_ PS_Cntrl_04_03_Modes m2 : 55|8@0+ (1,0) [0|255] ""  HIL
 SG_ PS_Cntrl_04_03_Enable m2 : 15|8@0+ (1,0) [0|255] ""  HIL
 SG_ PS_Cntrl_04_03_VoltageTarget m2 : 23|16@0+ (0.001,0) [0|32] ""  HIL
 SG_ PS_Cntrl_04_03_CurrentLimit m2 : 39|16@0+ (0.001,0) [0|32] ""  HIL
 SG_ PS_Cntrl_04_04_VerifyRequest m3 : 63|8@0+ (1,0) [0|255] ""  HIL
 SG_ PS_Cntrl_04_04_Modes m3 : 55|8@0+ (1,0) [0|255] ""  HIL
 SG_ PS_Cntrl_04_04_Enable m3 : 15|8@0+ (1,0) [0|255] ""  HIL
 SG_ PS_Cntrl_04_04_VoltageTarget m3 : 23|16@0+ (0.001,0) [0|32] ""  HIL
 SG_ PS_Cntrl_04_04_CurrentLimit m3 : 39|16@0+ (0.001,0) [0|32] ""  HIL
 SG_ PS_Cntrl_04_Channel M : 7|8@0- (1,0) [0|4] ""  HIL

BO_ 597 PS_Cntrl_05: 8 HIL_Tester
 SG_ PS_Cntrl_05_01_VerifyRequest m0 : 63|8@0+ (1,0) [0|255] ""  HIL
 SG_ PS_Cntrl_05_01_Modes m0 : 55|8@0+ (1,0) [0|255] ""  HIL
 SG_ PS_Cntrl_05_01_Enable m0 : 15|8@0+ (1,0) [0|255] ""  HIL
 SG_ PS_Cntrl_05_01_VoltageTarget m0 : 23|16@0+ (0.001,0) [0|32] ""  HIL
 SG_ PS_Cntrl_05_01_CurrentLimit m0 : 39|16@0+ (0.001,0) [0|32] ""  HIL
 SG_ PS_Cntrl_05_02_VerifyRequest m1 : 63|8@0+ (1,0) [0|255] ""  HIL
 SG_ PS_Cntrl_05_02_Modes m1 : 55|8@0+ (1,0) [0|255] ""  HIL
 SG_ PS_Cntrl_05_02_Enable m1 : 15|8@0+ (1,0) [0|255] ""  HIL
 SG_ PS_Cntrl_05_02_VoltageTarget m1 : 23|16@0+ (0.001,0) [0|32] ""  HIL
 SG_ PS_Cntrl_05_02_CurrentLimit m1 : 39|16@0+ (0.001,0) [0|32] ""  HIL
 SG_ PS_Cntrl_05_03_VerifyRequest m2 : 63|8@0+ (1,0) [0|255] ""  HIL
 SG_ PS_Cntrl_05_03_Modes m2 : 55|8@0+ (1,0) [0|255] ""  HIL
 SG_ PS_Cntrl_05_03_Enable m2 : 15|8@0+ (1,0) [0|255] ""  HIL
 SG_ PS_Cntrl_05_03_VoltageTarget m2 : 23|16@0+ (0.001,0) [0|32] ""  HIL
 SG_ PS_Cntrl_05_03_CurrentLimit m2 : 39|16@0+ (0.001,0) [0|32] ""  HIL
 SG_ PS_Cntrl_05_04_VerifyRequest m3 : 63|8@0+ (1,0) [0|255] ""  HIL
 SG_ PS_Cntrl_05_04_Modes m3 : 55|8@0+ (1,0) [0|255] ""  HIL
 SG_ PS_Cntrl_05_04_Enable m3 : 15|8@0+ (1,0) [0|255] ""  HIL
 SG_ PS_Cntrl_05_04_VoltageTarget m3 : 23|16@0+ (0.001,0) [0|32] ""  HIL
 SG_ PS_Cntrl_05_04_CurrentLimit m3 : 39|16@0+ (0.001,0) [0|32] ""  HIL
 SG_ PS_Cntrl_05_Channel M : 7|8@0- (1,0) [0|4] ""  HIL

BO_ 598 PS_Cntrl_06: 8 HIL_Tester
 SG_ PS_Cntrl_06_01_VerifyRequest m0 : 63|8@0+ (1,0) [0|255] ""  HIL
 SG_ PS_Cntrl_06_01_Modes m0 : 55|8@0+ (1,0) [0|255] ""  HIL
 SG_ PS_Cntrl_06_01_Enable m0 : 15|8@0+ (1,0) [0|255] ""  HIL
 SG_ PS_Cntrl_06_01_VoltageTarget m0 : 23|16@0+ (0.001,0) [0|32] ""  HIL
 SG_ PS_Cntrl_06_01_CurrentLimit m0 : 39|16@0+ (0.001,0) [0|32] ""  HIL
 SG_ PS_Cntrl_06_02_VerifyRequest m1 : 63|8@0+ (1,0) [0|255] ""  HIL
 SG_ PS_Cntrl_06_02_Modes m1 : 55|8@0+ (1,0) [0|255] ""  HIL
 SG_ PS_Cntrl_06_02_Enable m1 : 15|8@0+ (1,0) [0|255] ""  HIL
 SG_ PS_Cntrl_06_02_VoltageTarget m1 : 23|16@0+ (0.001,0) [0|32] ""  HIL
 SG_ PS_Cntrl_06_02_CurrentLimit m1 : 39|16@0+ (0.001,0) [0|32] ""  HIL
 SG_ PS_Cntrl_06_03_VerifyRequest m2 : 63|8@0+ (1,0) [0|255] ""  HIL
 SG_ PS_Cntrl_06_03_Modes m2 : 55|8@0+ (1,0) [0|255] ""  HIL
 SG_ PS_Cntrl_06_03_Enable m2 : 15|8@0+ (1,0) [0|255] ""  HIL
 SG_ PS_Cntrl_06_03_VoltageTarget m2 : 23|16@0+ (0.001,0) [0|32] ""  HIL
 SG_ PS_Cntrl_06_03_CurrentLimit m2 : 39|16@0+ (0.001,0) [0|32] ""  HIL
 SG_ PS_Cntrl_06_04_VerifyRequest m3 : 63|8@0+ (1,0) [0|255] ""  HIL
 SG_ PS_Cntrl_06_04_Modes m3 : 55|8@0+ (1,0) [0|255] ""  HIL
 SG_ PS_Cntrl_06_04_Enable m3 : 15|8@0+ (1,0) [0|255] ""  HIL
 SG_ PS_Cntrl_06_04_VoltageTarget m3 : 23|16@0+ (0.001,0) [0|32] ""  HIL
 SG_ PS_Cntrl_06_04_CurrentLimit m3 : 39|16@0+ (0.001,0) [0|32] ""  HIL
 SG_ PS_Cntrl_06_Channel M : 7|8@0- (1,0) [0|4] ""  HIL

BO_ 599 PS_Cntrl_07: 8 HIL_Tester
 SG_ PS_Cntrl_07_01_VerifyRequest m0 : 63|8@0+ (1,0) [0|255] ""  HIL
 SG_ PS_Cntrl_07_01_Modes m0 : 55|8@0+ (1,0) [0|255] ""  HIL
 SG_ PS_Cntrl_07_01_Enable m0 : 15|8@0+ (1,0) [0|255] ""  HIL
 SG_ PS_Cntrl_07_01_VoltageTarget m0 : 23|16@0+ (0.001,0) [0|32] ""  HIL
 SG_ PS_Cntrl_07_01_CurrentLimit m0 : 39|16@0+ (0.001,0) [0|32] ""  HIL
 SG_ PS_Cntrl_07_02_VerifyRequest m1 : 63|8@0+ (1,0) [0|255] ""  HIL
 SG_ PS_Cntrl_07_02_Modes m1 : 55|8@0+ (1,0) [0|255] ""  HIL
 SG_ PS_Cntrl_07_02_Enable m1 : 15|8@0+ (1,0) [0|255] ""  HIL
 SG_ PS_Cntrl_07_02_VoltageTarget m1 : 23|16@0+ (0.001,0) [0|32] ""  HIL
 SG_ PS_Cntrl_07_02_CurrentLimit m1 : 39|16@0+ (0.001,0) [0|32] ""  HIL
 SG_ PS_Cntrl_07_03_VerifyRequest m2 : 63|8@0+ (1,0) [0|255] ""  HIL
 SG_ PS_Cntrl_07_03_Modes m2 : 55|8@0+ (1,0) [0|255] ""  HIL
 SG_ PS_Cntrl_07_03_Enable m2 : 15|8@0+ (1,0) [0|255] ""  HIL
 SG_ PS_Cntrl_07_03_VoltageTarget m2 : 23|16@0+ (0.001,0) [0|32] ""  HIL
 SG_ PS_Cntrl_07_03_CurrentLimit m2 : 39|16@0+ (0.001,0) [0|32] ""  HIL
 SG_ PS_Cntrl_07_04_VerifyRequest m3 : 63|8@0+ (1,0) [0|255] ""  HIL
 SG_ PS_Cntrl_07_04_Modes m3 : 55|8@0+ (1,0) [0|255] ""  HIL
 SG_ PS_Cntrl_07_04_Enable m3 : 15|8@0+ (1,0) [0|255] ""  HIL
 SG_ PS_Cntrl_07_04_VoltageTarget m3 : 23|16@0+ (0.001,0) [0|32] ""  HIL
 SG_ PS_Cntrl_07_04_CurrentLimit m3 : 39|16@0+ (0.001,0) [0|32] ""  HIL
 SG_ PS_Cntrl_07_Channel M : 7|8@0- (1,0) [0|4] ""  HIL

BO_ 600 PS_Cntrl_08: 8 HIL_Tester
 SG_ PS_Cntrl_08_01_VerifyRequest m0 : 63|8@0+ (1,0) [0|255] ""  HIL
 SG_ PS_Cntrl_08_01_Modes m0 : 55|8@0+ (1,0) [0|255] ""  HIL
 SG_ PS_Cntrl_08_01_Enable m0 : 15|8@0+ (1,0) [0|255] ""  HIL
 SG_ PS_Cntrl_08_01_VoltageTarget m0 : 23|16@0+ (0.001,0) [0|32] ""  HIL
 SG_ PS_Cntrl_08_01_CurrentLimit m0 : 39|16@0+ (0.001,0) [0|32] ""  HIL
 SG_ PS_Cntrl_08_02_VerifyRequest m1 : 63|8@0+ (1,0) [0|255] ""  HIL
 SG_ PS_Cntrl_08_02_Modes m1 : 55|8@0+ (1,0) [0|255] ""  HIL
 SG_ PS_Cntrl_08_02_Enable m1 : 15|8@0+ (1,0) [0|255] ""  HIL
 SG_ PS_Cntrl_08_02_VoltageTarget m1 : 23|16@0+ (0.001,0) [0|32] ""  HIL
 SG_ PS_Cntrl_08_02_CurrentLimit m1 : 39|16@0+ (0.001,0) [0|32] ""  HIL
 SG_ PS_Cntrl_08_03_VerifyRequest m2 : 63|8@0+ (1,0) [0|255] ""  HIL
 SG_ PS_Cntrl_08_03_Modes m2 : 55|8@0+ (1,0) [0|255] ""  HIL
 SG_ PS_Cntrl_08_03_Enable m2 : 15|8@0+ (1,0) [0|255] ""  HIL
 SG_ PS_Cntrl_08_03_VoltageTarget m2 : 23|16@0+ (0.001,0) [0|32] ""  HIL
 SG_ PS_Cntrl_08_03_CurrentLimit m2 : 39|16@0+ (0.001,0) [0|32] ""  HIL
 SG_ PS_Cntrl_08_04_VerifyRequest m3 : 63|8@0+ (1,0) [0|255] ""  HIL
 SG_ PS_Cntrl_08_04_Modes m3 : 55|8@0+ (1,0) [0|255] ""  HIL
 SG_ PS_Cntrl_08_04_Enable m3 : 15|8@0+ (1,0) [0|255] ""  HIL
 SG_ PS_Cntrl_08_04_VoltageTarget m3 : 23|16@0+ (0.001,0) [0|32] ""  HIL
 SG_ PS_Cntrl_08_04_CurrentLimit m3 : 39|16@0+ (0.001,0) [0|32] ""  HIL
 SG_ PS_Cntrl_08_Channel M : 7|8@0- (1,0) [0|4] ""  HIL

BO_ 601 PS_Cntrl_09: 8 HIL_Tester
 SG_ PS_Cntrl_09_01_VerifyRequest m0 : 63|8@0+ (1,0) [0|255] ""  HIL
 SG_ PS_Cntrl_09_01_Modes m0 : 55|8@0+ (1,0) [0|255] ""  HIL
 SG_ PS_Cntrl_09_01_Enable m0 : 15|8@0+ (1,0) [0|255] ""  HIL
 SG_ PS_Cntrl_09_01_VoltageTarget m0 : 23|16@0+ (0.001,0) [0|32] ""  HIL
 SG_ PS_Cntrl_09_01_CurrentLimit m0 : 39|16@0+ (0.001,0) [0|32] ""  HIL
 SG_ PS_Cntrl_09_02_VerifyRequest m1 : 63|8@0+ (1,0) [0|255] ""  HIL
 SG_ PS_Cntrl_09_02_Modes m1 : 55|8@0+ (1,0) [0|255] ""  HIL
 SG_ PS_Cntrl_09_02_Enable m1 : 15|8@0+ (1,0) [0|255] ""  HIL
 SG_ PS_Cntrl_09_02_VoltageTarget m1 : 23|16@0+ (0.001,0) [0|32] ""  HIL
 SG_ PS_Cntrl_09_02_CurrentLimit m1 : 39|16@0+ (0.001,0) [0|32] ""  HIL
 SG_ PS_Cntrl_09_03_VerifyRequest m2 : 63|8@0+ (1,0) [0|255] ""  HIL
 SG_ PS_Cntrl_09_03_Modes m2 : 55|8@0+ (1,0) [0|255] ""  HIL
 SG_ PS_Cntrl_09_03_Enable m2 : 15|8@0+ (1,0) [0|255] ""  HIL
 SG_ PS_Cntrl_09_03_VoltageTarget m2 : 23|16@0+ (0.001,0) [0|32] ""  HIL
 SG_ PS_Cntrl_09_03_CurrentLimit m2 : 39|16@0+ (0.001,0) [0|32] ""  HIL
 SG_ PS_Cntrl_09_04_VerifyRequest m3 : 63|8@0+ (1,0) [0|255] ""  HIL
 SG_ PS_Cntrl_09_04_Modes m3 : 55|8@0+ (1,0) [0|255] ""  HIL
 SG_ PS_Cntrl_09_04_Enable m3 : 15|8@0+ (1,0) [0|255] ""  HIL
 SG_ PS_Cntrl_09_04_VoltageTarget m3 : 23|16@0+ (0.001,0) [0|32] ""  HIL
 SG_ PS_Cntrl_09_04_CurrentLimit m3 : 39|16@0+ (0.001,0) [0|32] ""  HIL
 SG_ PS_Cntrl_09_Channel M : 7|8@0- (1,0) [0|4] ""  HIL

BO_ 258 ContactorMonitor_Control2_Cyclic: 1 HIL_Tester

BO_ 257 ContactorMonitor_Control1_Edge: 1 HIL_Tester

BO_ 359 Lin_Status_Faults: 8 HIL
 SG_ LinStatus_flt_TxFailed_Slave2 : 20|1@1+ (1,0) [0|0] ""  HIL_Tester
 SG_ LinStatus_flt_TxFailed_Slave1 : 12|1@1+ (1,0) [0|0] ""  HIL_Tester
 SG_ LinStatus_flt_TxFailed_Master : 4|1@1+ (1,0) [0|0] ""  HIL_Tester
 SG_ LinStatus_flt_tmdout_Slave2 : 17|1@1+ (1,0) [0|0] ""  HIL_Tester
 SG_ LinStatus_flt_tmdout_Slave1 : 9|1@1+ (1,0) [0|0] ""  HIL_Tester
 SG_ LinStatus_flt_tmdout_Master : 1|1@1+ (1,0) [0|0] ""  HIL_Tester
 SG_ LinStatus_flt_missresp_Master : 0|1@1+ (1,0) [0|0] ""  HIL_Tester
 SG_ LinStatus_flt_crc_Slave2 : 18|1@1+ (1,0) [0|0] ""  HIL_Tester
 SG_ LinStatus_flt_crc_Slave1 : 10|1@1+ (1,0) [0|0] ""  HIL_Tester
 SG_ LinStatus_flt_crc_Master : 2|1@1+ (1,0) [0|0] ""  HIL_Tester
 SG_ LinStatus_flt_cnt_Slave2 : 19|1@1+ (1,0) [0|0] ""  HIL_Tester
 SG_ LinStatus_flt_cnt_Slave1 : 11|1@1+ (1,0) [0|0] ""  HIL_Tester
 SG_ LinStatus_flt_cnt_Master : 3|1@1+ (1,0) [0|0] ""  HIL_Tester

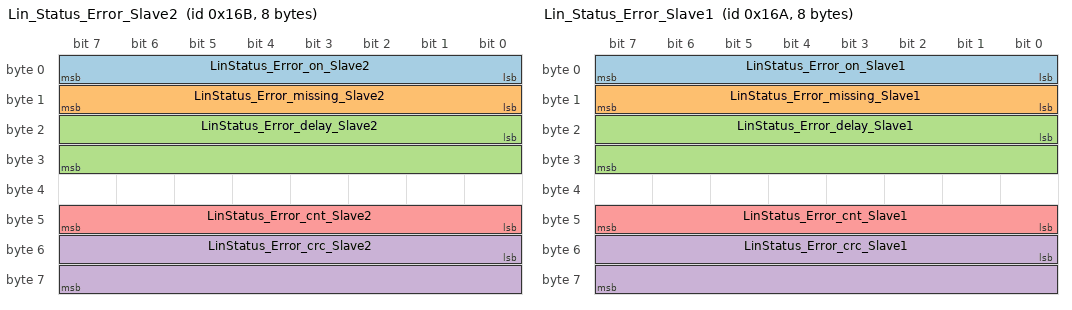
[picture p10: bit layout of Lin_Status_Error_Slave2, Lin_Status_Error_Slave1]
BO_ 363 Lin_Status_Error_Slave2: 8 HIL
 SG_ LinStatus_Error_on_Slave2 : 0|8@1+ (1,0) [0|0] ""  HIL_Tester
 SG_ LinStatus_Error_missing_Slave2 : 8|8@1+ (1,0) [0|0] ""  HIL_Tester
 SG_ LinStatus_Error_delay_Slave2 : 16|16@1+ (1,0) [0|0] ""  HIL_Tester
 SG_ LinStatus_Error_crc_Slave2 : 48|16@1- (1,0) [0|0] ""  HIL_Tester
 SG_ LinStatus_Error_cnt_Slave2 : 40|8@1- (1,0) [0|0] ""  HIL_Tester

BO_ 362 Lin_Status_Error_Slave1: 8 HIL
 SG_ LinStatus_Error_on_Slave1 : 0|8@1+ (1,0) [0|0] ""  HIL_Tester
 SG_ LinStatus_Error_missing_Slave1 : 8|8@1+ (1,0) [0|0] ""  HIL_Tester
 SG_ LinStatus_Error_delay_Slave1 : 16|16@1+ (1,0) [0|0] ""  HIL_Tester
 SG_ LinStatus_Error_crc_Slave1 : 48|16@1- (1,0) [0|0] ""  HIL_Tester
 SG_ LinStatus_Error_cnt_Slave1 : 40|8@1- (1,0) [0|0] ""  HIL_Tester

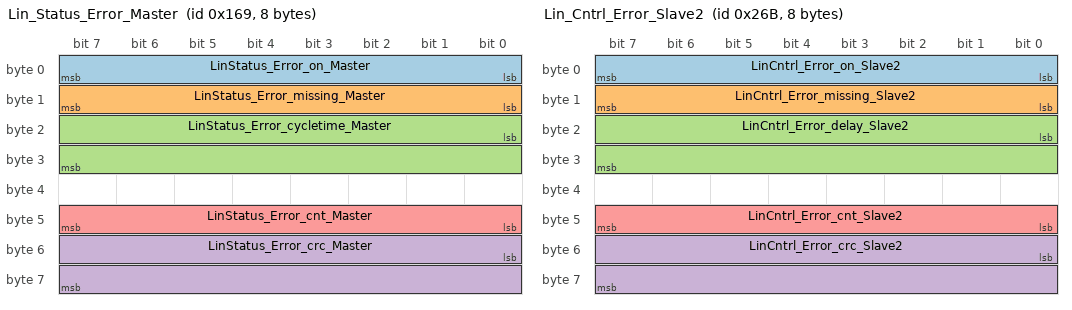
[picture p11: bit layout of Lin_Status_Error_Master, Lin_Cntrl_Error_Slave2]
BO_ 361 Lin_Status_Error_Master: 8 HIL
 SG_ LinStatus_Error_on_Master : 0|8@1+ (1,0) [0|0] ""  HIL_Tester
 SG_ LinStatus_Error_missing_Master : 8|8@1+ (1,0) [0|0] ""  HIL_Tester
 SG_ LinStatus_Error_cycletime_Master : 16|16@1+ (1,0) [0|0] ""  HIL_Tester
 SG_ LinStatus_Error_crc_Master : 48|16@1- (1,0) [0|0] ""  HIL_Tester
 SG_ LinStatus_Error_cnt_Master : 40|8@1- (1,0) [0|0] ""  HIL_Tester

BO_ 619 Lin_Cntrl_Error_Slave2: 8 HIL_Tester
 SG_ LinCntrl_Error_on_Slave2 : 0|8@1+ (1,0) [0|0] ""  HIL
 SG_ LinCntrl_Error_missing_Slave2 : 8|8@1+ (1,0) [0|0] ""  HIL
 SG_ LinCntrl_Error_delay_Slave2 : 16|16@1+ (1,0) [0|0] ""  HIL
 SG_ LinCntrl_Error_crc_Slave2 : 48|16@1- (1,0) [0|0] ""  HIL
 SG_ LinCntrl_Error_cnt_Slave2 : 40|8@1- (1,0) [0|0] ""  HIL

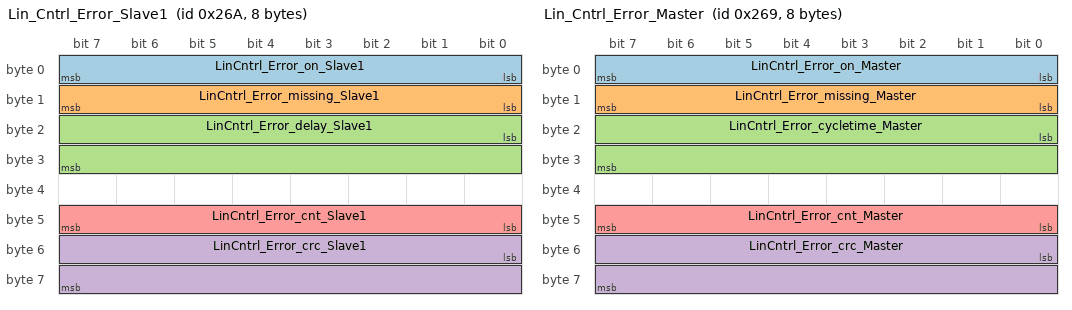
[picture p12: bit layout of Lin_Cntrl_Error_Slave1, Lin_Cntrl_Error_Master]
BO_ 618 Lin_Cntrl_Error_Slave1: 8 HIL_Tester
 SG_ LinCntrl_Error_on_Slave1 : 0|8@1+ (1,0) [0|0] ""  HIL
 SG_ LinCntrl_Error_missing_Slave1 : 8|8@1+ (1,0) [0|0] ""  HIL
 SG_ LinCntrl_Error_delay_Slave1 : 16|16@1+ (1,0) [0|0] ""  HIL
 SG_ LinCntrl_Error_crc_Slave1 : 48|16@1- (1,0) [0|0] ""  HIL
 SG_ LinCntrl_Error_cnt_Slave1 : 40|8@1- (1,0) [0|0] ""  HIL

BO_ 617 Lin_Cntrl_Error_Master: 8 HIL_Tester
 SG_ LinCntrl_Error_on_Master : 0|8@1+ (1,0) [0|0] ""  HIL
 SG_ LinCntrl_Error_missing_Master : 8|8@1+ (1,0) [0|0] ""  HIL
 SG_ LinCntrl_Error_cycletime_Master : 16|16@1+ (1,0) [0|0] ""  HIL
 SG_ LinCntrl_Error_crc_Master : 48|16@1- (1,0) [0|0] ""  HIL
 SG_ LinCntrl_Error_cnt_Master : 40|8@1- (1,0) [0|0] ""  HIL

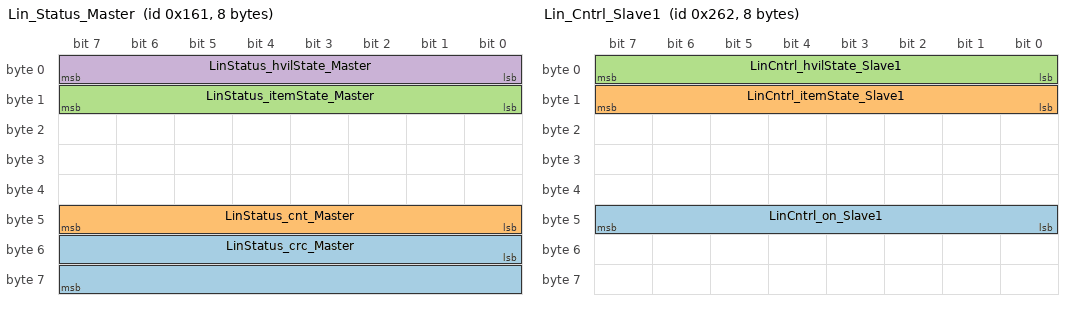
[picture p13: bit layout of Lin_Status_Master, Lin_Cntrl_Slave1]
BO_ 353 Lin_Status_Master: 8 HIL
 SG_ LinStatus_crc_Master : 48|16@1+ (1,0) [0|0] ""  HIL_Tester
 SG_ LinStatus_cnt_Master : 40|8@1+ (1,0) [0|0] ""  HIL_Tester
 SG_ LinStatus_itemState_Master : 8|8@1+ (1,0) [0|0] ""  HIL_Tester
 SG_ LinStatus_hvilState_Master : 0|8@1+ (1,0) [0|0] ""  HIL_Tester

BO_ 610 Lin_Cntrl_Slave1: 8 HIL_Tester
 SG_ LinCntrl_on_Slave1 : 40|8@1+ (1,0) [0|0] ""  HIL
 SG_ LinCntrl_itemState_Slave1 : 8|8@1+ (1,0) [0|0] ""  HIL
 SG_ LinCntrl_hvilState_Slave1 : 0|8@1+ (1,0) [0|0] ""  HIL

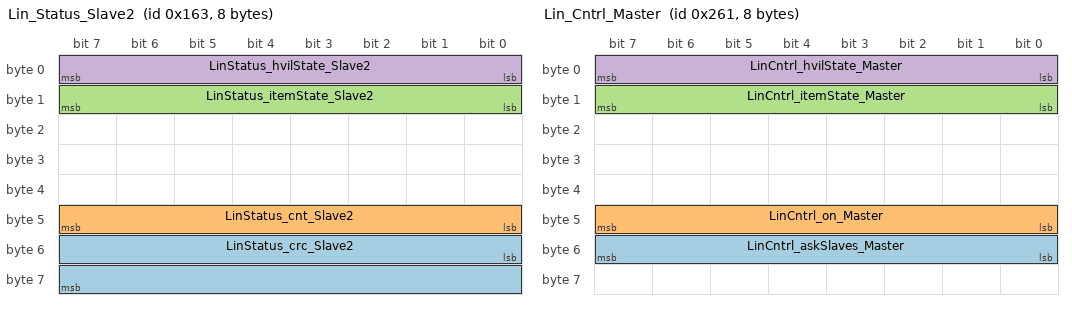
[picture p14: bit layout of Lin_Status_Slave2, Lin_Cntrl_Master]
BO_ 355 Lin_Status_Slave2: 8 HIL
 SG_ LinStatus_crc_Slave2 : 48|16@1+ (1,0) [0|0] ""  HIL_Tester
 SG_ LinStatus_cnt_Slave2 : 40|8@1+ (1,0) [0|0] ""  HIL_Tester
 SG_ LinStatus_itemState_Slave2 : 8|8@1+ (1,0) [0|0] ""  HIL_Tester
 SG_ LinStatus_hvilState_Slave2 : 0|8@1+ (1,0) [0|0] ""  HIL_Tester

BO_ 609 Lin_Cntrl_Master: 8 HIL_Tester
 SG_ LinCntrl_askSlaves_Master : 48|8@1+ (1,0) [0|0] ""  HIL
 SG_ LinCntrl_on_Master : 40|8@1+ (1,0) [0|0] ""  HIL
 SG_ LinCntrl_itemState_Master : 8|8@1+ (1,0) [0|0] ""  HIL
 SG_ LinCntrl_hvilState_Master : 0|8@1+ (1,0) [0|0] ""  HIL

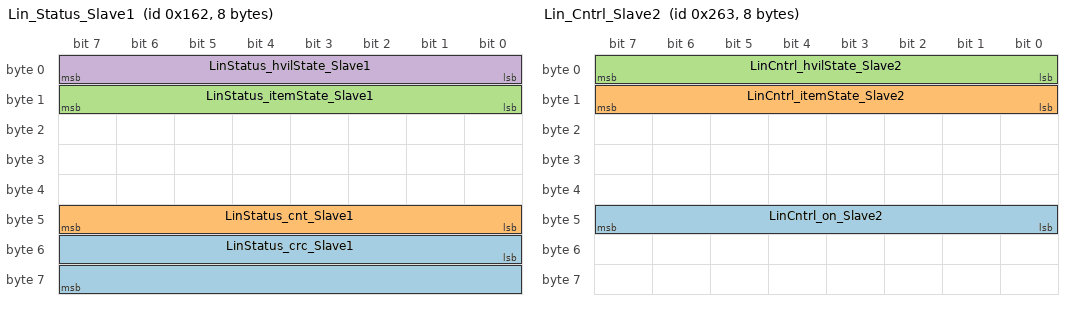
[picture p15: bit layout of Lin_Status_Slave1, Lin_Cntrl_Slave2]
BO_ 354 Lin_Status_Slave1: 8 HIL
 SG_ LinStatus_crc_Slave1 : 48|16@1+ (1,0) [0|0] ""  HIL_Tester
 SG_ LinStatus_cnt_Slave1 : 40|8@1+ (1,0) [0|0] ""  HIL_Tester
 SG_ LinStatus_itemState_Slave1 : 8|8@1+ (1,0) [0|0] ""  HIL_Tester
 SG_ LinStatus_hvilState_Slave1 : 0|8@1+ (1,0) [0|0] ""  HIL_Tester

BO_ 611 Lin_Cntrl_Slave2: 8 HIL_Tester
 SG_ LinCntrl_on_Slave2 : 40|8@1+ (1,0) [0|0] ""  HIL
 SG_ LinCntrl_itemState_Slave2 : 8|8@1+ (1,0) [0|0] ""  HIL
 SG_ LinCntrl_hvilState_Slave2 : 0|8@1+ (1,0) [0|0] ""  HIL

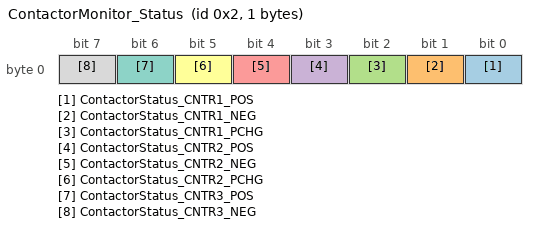
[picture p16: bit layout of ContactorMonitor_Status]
BO_ 2 ContactorMonitor_Status: 1 HIL
 SG_ ContactorStatus_CNTR1_POS : 0|1@0+ (1,0) [0|0] ""  HIL_Tester
 SG_ ContactorStatus_CNTR1_NEG : 1|1@0+ (1,0) [0|0] ""  HIL_Tester
 SG_ ContactorStatus_CNTR1_PCHG : 2|1@0+ (1,0) [0|0] ""  HIL_Tester
 SG_ ContactorStatus_CNTR2_POS : 3|1@0+ (1,0) [0|0] ""  HIL_Tester
 SG_ ContactorStatus_CNTR2_NEG : 4|1@0+ (1,0) [0|0] ""  HIL_Tester
 SG_ ContactorStatus_CNTR2_PCHG : 5|1@0+ (1,0) [0|0] ""  HIL_Tester
 SG_ ContactorStatus_CNTR3_POS : 6|1@0+ (1,0) [0|0] ""  HIL_Tester
 SG_ ContactorStatus_CNTR3_NEG : 7|1@0+ (1,0) [0|0] ""  HIL_Tester

BO_ 273 RCJ2Stat: 8 HIL
 SG_ RCJ2Stat_HALL_SENSE_OC : 0|1@0+ (1,0) [0|0] ""  HIL_Tester
 SG_ RCJ2Stat_HALL_SUPPLY_OC : 1|1@0+ (1,0) [0|0] ""  HIL_Tester
 SG_ RCJ2Stat_HALL_GND_OC : 2|1@0+ (1,0) [0|0] ""  HIL_Tester
 SG_ RCJ2Stat_NTC1_GND_OC : 3|1@0+ (1,0) [0|0] ""  HIL_Tester
 SG_ RCJ2Stat_ISENSE_GND_OC : 4|1@0+ (1,0) [0|0] ""  HIL_Tester
 SG_ RCJ2Stat_ISENSE_SUPPLY_OC : 5|1@0+ (1,0) [0|0] ""  HIL_Tester
 SG_ RCJ2Stat_ISENSE_CAN_LOW_OC : 6|1@0+ (1,0) [0|0] ""  HIL_Tester
 SG_ RCJ2Stat_ISENSE_CAN_HIGH_OC : 7|1@0+ (1,0) [0|0] ""  HIL_Tester
 SG_ RCJ2Stat_PWR_GND1_OC : 16|1@0+ (1,0) [0|0] ""  HIL_Tester
 SG_ RCJ2Stat_PCAN_LOW_OC : 17|1@0+ (1,0) [0|0] ""  HIL_Tester
 SG_ RCJ2Stat_PCAN_HIGH_OC : 18|1@0+ (1,0) [0|0] ""  HIL_Tester
 SG_ RCJ2Stat_CNTR_PWR1_OC : 19|1@0+ (1,0) [0|0] ""  HIL_Tester
 SG_ RCJ2Stat_ADDR1__NTC1_OC : 20|1@0+ (1,0) [0|0] ""  HIL_Tester
 SG_ RCJ2Stat_POS_CNTR1_PLUS_OC : 21|1@0+ (1,0) [0|0] ""  HIL_Tester
 SG_ RCJ2Stat_PCH_CNTR1_PLUS_OC : 22|1@0+ (1,0) [0|0] ""  HIL_Tester
 SG_ RCJ2Stat_NEG_CNTR1_PLUS_OC : 23|1@0+ (1,0) [0|0] ""  HIL_Tester
 SG_ RCJ2Stat_ADDR5_OC : 32|1@0+ (1,0) [0|0] ""  HIL_Tester
 SG_ RCJ2Stat_NTC2_GND_OC : 33|1@0+ (1,0) [0|0] ""  HIL_Tester
 SG_ RCJ2Stat_KEY_OC : 34|1@0+ (1,0) [0|0] ""  HIL_Tester
 SG_ RCJ2Stat_GPIO1_PLUS_OC : 35|1@0+ (1,0) [0|0] ""  HIL_Tester
 SG_ RCJ2Stat_LIN1_OC : 36|1@0+ (1,0) [0|0] ""  HIL_Tester
 SG_ RCJ2Stat_SUPPLY_PWR_12V_OC : 37|1@0+ (1,0) [0|0] ""  HIL_Tester
 SG_ RCJ2Stat_HVIL_IN_OC : 38|1@0+ (1,0) [0|0] ""  HIL_Tester
 SG_ RCJ2Stat_HVIL_OUT_OC : 39|1@0+ (1,0) [0|0] ""  HIL_Tester
 SG_ RCJ2Stat_PWR_GND2_OC : 48|1@0+ (1,0) [0|0] ""  HIL_Tester
 SG_ RCJ2Stat_PTCAN_H_OC : 49|1@0+ (1,0) [0|0] ""  HIL_Tester
 SG_ RCJ2Stat_PTCAN_L_OC : 50|1@0+ (1,0) [0|0] ""  HIL_Tester
 SG_ RCJ2Stat_CNTR_PWR2_OC : 51|1@0+ (1,0) [0|0] ""  HIL_Tester
 SG_ RCJ2Stat_ADDR2_NTC2_OC : 52|1@0+ (1,0) [0|0] ""  HIL_Tester
 SG_ RCJ2Stat_POS_CNTR1_MINUS_OC : 53|1@0+ (1,0) [0|0] ""  HIL_Tester
 SG_ RCJ2Stat_PCH_CNTR1_MINUS_OC : 54|1@0+ (1,0) [0|0] ""  HIL_Tester
 SG_ RCJ2Stat_NEG_CNTR1_MINUS_OC : 55|1@0+ (1,0) [0|0] ""  HIL_Tester
 SG_ RCJ2Stat_HALL_SENSE_ALT : 8|1@0+ (1,0) [0|0] ""  HIL_Tester
 SG_ RCJ2Stat_HALL_SUPPLY_AUX : 9|1@0+ (1,0) [0|0] ""  HIL_Tester
 SG_ RCJ2Stat_HALL_GND_AUX : 10|1@0+ (1,0) [0|0] ""  HIL_Tester
 SG_ RCJ2Stat_NTC1_GND_ALT : 11|1@0+ (1,0) [0|0] ""  HIL_Tester
 SG_ RCJ2Stat_ISENSE_GND_AUX : 12|1@0+ (1,0) [0|0] ""  HIL_Tester
 SG_ RCJ2Stat_ISENSE_SUPPLY_AUX : 13|1@0+ (1,0) [0|0] ""  HIL_Tester
 SG_ RCJ2Stat_ISENSE_CAN_LOW_ALT : 14|1@0+ (1,0) [0|0] ""  HIL_Tester
 SG_ RCJ2Stat_ISENSE_CAN_HIGH_ALT : 15|1@0+ (1,0) [0|0] ""  HIL_Tester
 SG_ RCJ2Stat_PWR_GND1_AUX : 24|1@0+ (1,0) [0|0] ""  HIL_Tester
 SG_ RCJ2Stat_PCAN_LOW_ALT : 25|1@0+ (1,0) [0|0] ""  HIL_Tester
 SG_ RCJ2Stat_PCAN_HIGH_ALT : 26|1@0+ (1,0) [0|0] ""  HIL_Tester
 SG_ RCJ2Stat_CNTR_PWR1_ALT : 27|1@0+ (1,0) [0|0] ""  HIL_Tester
 SG_ RCJ2Stat_ADDR1__NTC1_ALT : 28|1@0+ (1,0) [0|0] ""  HIL_Tester
 SG_ RCJ2Stat_POS_CNTR1_PLUS_AUX : 29|1@0+ (1,0) [0|0] ""  HIL_Tester
 SG_ RCJ2Stat_PCH_CNTR1_PLUS_AUX : 30|1@0+ (1,0) [0|0] ""  HIL_Tester
 SG_ RCJ2Stat_NEG_CNTR1_PLUS_AUX : 31|1@0+ (1,0) [0|0] ""  HIL_Tester
 SG_ RCJ2Stat_ADDR5_ALT : 40|1@0+ (1,0) [0|0] ""  HIL_Tester
 SG_ RCJ2Stat_NTC2_GND_ALT : 41|1@0+ (1,0) [0|0] ""  HIL_Tester
 SG_ RCJ2Stat_KEY_ALT : 42|1@0+ (1,0) [0|0] ""  HIL_Tester
 SG_ RCJ2Stat_GPIO1_PLUS_ALT : 43|1@0+ (1,0) [0|0] ""  HIL_Tester
 SG_ RCJ2Stat_LIN1_ALT : 44|1@0+ (1,0) [0|0] ""  HIL_Tester
 SG_ RCJ2Stat_SUPPLY_PWR_12V_AUX : 45|1@0+ (1,0) [0|0] ""  HIL_Tester
 SG_ RCJ2Stat_HVIL_IN_AUX : 46|1@0+ (1,0) [0|0] ""  HIL_Tester
 SG_ RCJ2Stat_HVIL_OUT_AUX : 47|1@0+ (1,0) [0|0] ""  HIL_Tester
 SG_ RCJ2Stat_PWR_GND2_ALT : 56|1@0+ (1,0) [0|0] ""  HIL_Tester
 SG_ RCJ2Stat_PTCAN_H_ALT : 57|1@0+ (1,0) [0|0] ""  HIL_Tester
 SG_ RCJ2Stat_PTCAN_L_ALT : 58|1@0+ (1,0) [0|0] ""  HIL_Tester
 SG_ RCJ2Stat_CNTR_PWR2_ALT : 59|1@0+ (1,0) [0|0] ""  HIL_Tester
 SG_ RCJ2Stat_ADDR2_NTC2_ALT : 60|1@0+ (1,0) [0|0] ""  HIL_Tester
 SG_ RCJ2Stat_POS_CNTR1_MINUS_AUX : 61|1@0+ (1,0) [0|0] ""  HIL_Tester
 SG_ RCJ2Stat_PCH_CNTR1_MINUS_AUX : 62|1@0+ (1,0) [0|0] ""  HIL_Tester
 SG_ RCJ2Stat_NEG_CNTR1_MINUS_AUX : 63|1@0+ (1,0) [0|0] ""  HIL_Tester

BO_ 529 RCJ2Cntrl: 8 HIL_Tester
 SG_ RCJ2Cntrl_HALL_SENSE_OC : 0|1@0+ (1,0) [0|0] ""  HIL_Tester
 SG_ RCJ2Cntrl_HALL_SUPPLY_OC : 1|1@0+ (1,0) [0|0] ""  HIL_Tester
 SG_ RCJ2Cntrl_HALL_GND_OC : 2|1@0+ (1,0) [0|0] ""  HIL_Tester
 SG_ RCJ2Cntrl_NTC1_GND_OC : 3|1@0+ (1,0) [0|0] ""  HIL_Tester
 SG_ RCJ2Cntrl_ISENSE_GND_OC : 4|1@0+ (1,0) [0|0] ""  HIL_Tester
 SG_ RCJ2Cntrl_ISENSE_SUPPLY_OC : 5|1@0+ (1,0) [0|0] ""  HIL_Tester
 SG_ RCJ2Cntrl_ISENSE_CAN_LOW_OC : 6|1@0+ (1,0) [0|0] ""  HIL_Tester
 SG_ RCJ2Cntrl_ISENSE_CAN_HIGH_OC : 7|1@0+ (1,0) [0|0] ""  HIL_Tester
 SG_ RCJ2Cntrl_PWR_GND1_OC : 16|1@0+ (1,0) [0|0] ""  HIL_Tester
 SG_ RCJ2Cntrl_PCAN_LOW_OC : 17|1@0+ (1,0) [0|0] ""  HIL_Tester
 SG_ RCJ2Cntrl_PCAN_HIGH_OC : 18|1@0+ (1,0) [0|0] ""  HIL_Tester
 SG_ RCJ2Cntrl_CNTR_PWR1_OC : 19|1@0+ (1,0) [0|0] ""  HIL_Tester
 SG_ RCJ2Cntrl_ADDR1__NTC1_OC : 20|1@0+ (1,0) [0|0] ""  HIL_Tester
 SG_ RCJ2Cntrl_POS_CNTR1_PLUS_OC : 21|1@0+ (1,0) [0|0] ""  HIL_Tester
 SG_ RCJ2Cntrl_PCH_CNTR1_PLUS_OC : 22|1@0+ (1,0) [0|0] ""  HIL_Tester
 SG_ RCJ2Cntrl_NEG_CNTR1_PLUS_OC : 23|1@0+ (1,0) [0|0] ""  HIL_Tester
 SG_ RCJ2Cntrl_ADDR5_OC : 32|1@0+ (1,0) [0|0] ""  HIL_Tester
 SG_ RCJ2Cntrl_NTC2_GND_OC : 33|1@0+ (1,0) [0|0] ""  HIL_Tester
 SG_ RCJ2Cntrl_KEY_OC : 34|1@0+ (1,0) [0|0] ""  HIL_Tester
 SG_ RCJ2Cntrl_GPIO1_PLUS_OC : 35|1@0+ (1,0) [0|0] ""  HIL_Tester
 SG_ RCJ2Cntrl_LIN1_OC : 36|1@0+ (1,0) [0|0] ""  HIL_Tester
 SG_ RCJ2Cntrl_SUPPLY_PWR_12V_OC : 37|1@0+ (1,0) [0|0] ""  HIL_Tester
 SG_ RCJ2Cntrl_HVIL_IN_OC : 38|1@0+ (1,0) [0|0] ""  HIL_Tester
 SG_ RCJ2Cntrl_HVIL_OUT_OC : 39|1@0+ (1,0) [0|0] ""  HIL_Tester
 SG_ RCJ2Cntrl_PWR_GND2_OC : 48|1@0+ (1,0) [0|0] ""  HIL_Tester
 SG_ RCJ2Cntrl_PTCAN_H_OC : 49|1@0+ (1,0) [0|0] ""  HIL_Tester
 SG_ RCJ2Cntrl_PTCAN_L_OC : 50|1@0+ (1,0) [0|0] ""  HIL_Tester
 SG_ RCJ2Cntrl_CNTR_PWR2_OC : 51|1@0+ (1,0) [0|0] ""  HIL_Tester
 SG_ RCJ2Cntrl_ADDR2_NTC2_OC : 52|1@0+ (1,0) [0|0] ""  HIL_Tester
 SG_ RCJ2Cntrl_POS_CNTR1_MINUS_OC : 53|1@0+ (1,0) [0|0] ""  HIL_Tester
 SG_ RCJ2Cntrl_PCH_CNTR1_MINUS_OC : 54|1@0+ (1,0) [0|0] ""  HIL_Tester
 SG_ RCJ2Cntrl_NEG_CNTR1_MINUS_OC : 55|1@0+ (1,0) [0|0] ""  HIL_Tester
 SG_ RCJ2Cntrl_HALL_SENSE_ALT : 8|1@0+ (1,0) [0|0] ""  HIL_Tester
 SG_ RCJ2Cntrl_HALL_SUPPLY_AUX : 9|1@0+ (1,0) [0|0] ""  HIL_Tester
 SG_ RCJ2Cntrl_HALL_GND_AUX : 10|1@0+ (1,0) [0|0] ""  HIL_Tester
 SG_ RCJ2Cntrl_NTC1_GND_ALT : 11|1@0+ (1,0) [0|0] ""  HIL_Tester
 SG_ RCJ2Cntrl_ISENSE_GND_AUX : 12|1@0+ (1,0) [0|0] ""  HIL_Tester
 SG_ RCJ2Cntrl_ISENSE_SUPPLY_AUX : 13|1@0+ (1,0) [0|0] ""  HIL_Tester
 SG_ RCJ2Cntrl_ISENSE_CAN_LOW_ALT : 14|1@0+ (1,0) [0|0] ""  HIL_Tester
 SG_ RCJ2Cntrl_ISENSE_CAN_HIGH_ALT : 15|1@0+ (1,0) [0|0] ""  HIL_Tester
 SG_ RCJ2Cntrl_PWR_GND1_AUX : 24|1@0+ (1,0) [0|0] ""  HIL_Tester
 SG_ RCJ2Cntrl_PCAN_LOW_ALT : 25|1@0+ (1,0) [0|0] ""  HIL_Tester
 SG_ RCJ2Cntrl_PCAN_HIGH_ALT : 26|1@0+ (1,0) [0|0] ""  HIL_Tester
 SG_ RCJ2Cntrl_CNTR_PWR1_ALT : 27|1@0+ (1,0) [0|0] ""  HIL_Tester
 SG_ RCJ2Cntrl_ADDR1__NTC1_ALT : 28|1@0+ (1,0) [0|0] ""  HIL_Tester
 SG_ RCJ2Cntrl_POS_CNTR1_PLUS_AUX : 29|1@0+ (1,0) [0|0] ""  HIL_Tester
 SG_ RCJ2Cntrl_PCH_CNTR1_PLUS_AUX : 30|1@0+ (1,0) [0|0] ""  HIL_Tester
 SG_ RCJ2Cntrl_NEG_CNTR1_PLUS_AUX : 31|1@0+ (1,0) [0|0] ""  HIL_Tester
 SG_ RCJ2Cntrl_ADDR5_ALT : 40|1@0+ (1,0) [0|0] ""  HIL_Tester
 SG_ RCJ2Cntrl_NTC2_GND_ALT : 41|1@0+ (1,0) [0|0] ""  HIL_Tester
 SG_ RCJ2Cntrl_KEY_ALT : 42|1@0+ (1,0) [0|0] ""  HIL_Tester
 SG_ RCJ2Cntrl_GPIO1_PLUS_ALT : 43|1@0+ (1,0) [0|0] ""  HIL_Tester
 SG_ RCJ2Cntrl_LIN1_ALT : 44|1@0+ (1,0) [0|0] ""  HIL_Tester
 SG_ RCJ2Cntrl_SUPPLY_PWR_12V_AUX : 45|1@0+ (1,0) [0|0] ""  HIL_Tester
 SG_ RCJ2Cntrl_HVIL_IN_AUX : 46|1@0+ (1,0) [0|0] ""  HIL_Tester
 SG_ RCJ2Cntrl_HVIL_OUT_AUX : 47|1@0+ (1,0) [0|0] ""  HIL_Tester
 SG_ RCJ2Cntrl_PWR_GND2_ALT : 56|1@0+ (1,0) [0|0] ""  HIL_Tester
 SG_ RCJ2Cntrl_PTCAN_H_ALT : 57|1@0+ (1,0) [0|0] ""  HIL_Tester
 SG_ RCJ2Cntrl_PTCAN_L_ALT : 58|1@0+ (1,0) [0|0] ""  HIL_Tester
 SG_ RCJ2Cntrl_CNTR_PWR2_ALT : 59|1@0+ (1,0) [0|0] ""  HIL_Tester
 SG_ RCJ2Cntrl_ADDR2_NTC2_ALT : 60|1@0+ (1,0) [0|0] ""  HIL_Tester
 SG_ RCJ2Cntrl_POS_CNTR1_MINUS_AUX : 61|1@0+ (1,0) [0|0] ""  HIL_Tester
 SG_ RCJ2Cntrl_PCH_CNTR1_MINUS_AUX : 62|1@0+ (1,0) [0|0] ""  HIL_Tester
 SG_ RCJ2Cntrl_NEG_CNTR1_MINUS_AUX : 63|1@0+ (1,0) [0|0] ""  HIL_Tester

BO_ 275 RCJ4Stat: 8 HIL
 SG_ RCJ4Stat_Link_MINUS_OC : 0|1@0+ (1,0) [0|0] ""  HIL_Tester
 SG_ RCJ4Stat_Pack_MINUS_OC : 1|1@0+ (1,0) [0|0] ""  HIL_Tester
 SG_ RCJ4Stat_Pack_PLUS_OC : 2|1@0+ (1,0) [0|0] ""  HIL_Tester
 SG_ RCJ4Stat_Link_PLUS_OC : 3|1@0+ (1,0) [0|0] ""  HIL_Tester
 SG_ RCJ4Stat_POS_LINK_2_OC : 4|1@0+ (1,0) [0|0] ""  HIL_Tester
 SG_ RCJ4Stat_POS_LINK_3_OC : 5|1@0+ (1,0) [0|0] ""  HIL_Tester
 SG_ RCJ4Stat_NEG_LINK_3_OC : 6|1@0+ (1,0) [0|0] ""  HIL_Tester
 SG_ RCJ4Stat_NEG_LINK_2_OC : 7|1@0+ (1,0) [0|0] ""  HIL_Tester
 SG_ RCJ4Stat_COMM_PLUS_OC : 16|1@0+ (1,0) [0|0] ""  HIL_Tester
 SG_ RCJ4Stat_COMM_MINUS_OC : 17|1@0+ (1,0) [0|0] ""  HIL_Tester
 SG_ RCJ4Stat_COMM_NC0_OC : 18|1@0+ (1,0) [0|0] ""  HIL_Tester
 SG_ RCJ4Stat_COMM_SHIELD_OC : 19|1@0+ (1,0) [0|0] ""  HIL_Tester
 SG_ RCJ4Stat_Link_Active_Dischg_AUX : 32|1@0+ (1,0) [0|0] ""  HIL_Tester
 SG_ RCJ4Stat_Link_Weld_AUX : 33|1@0+ (1,0) [0|0] ""  HIL_Tester
 SG_ RCJ4Stat_Pack_Weld_AUX : 34|1@0+ (1,0) [0|0] ""  HIL_Tester
 SG_ RCJ4Stat_ : 35|1@0+ (1,0) [0|0] ""  HIL_Tester
 SG_ RCJ4Stat_CNTR_HiSideStuck_AUX : 36|1@0+ (1,0) [0|0] ""  HIL_Tester
 SG_ RCJ4Stat_POS_CNTR1_LoSideSC_AUX : 37|1@0+ (1,0) [0|0] ""  HIL_Tester
 SG_ RCJ4Stat_PCH_CNTR1_LoSideSC_AUX : 38|1@0+ (1,0) [0|0] ""  HIL_Tester
 SG_ RCJ4Stat_NEG_CNTR1_LoSideSC_AUX : 39|1@0+ (1,0) [0|0] ""  HIL_Tester
 SG_ RCJ4Stat_POS_CNTR1_WELD_AUX : 48|1@0+ (1,0) [0|0] ""  HIL_Tester
 SG_ RCJ4Stat_PCH_CNTR1_WELD_AUX : 49|1@0+ (1,0) [0|0] ""  HIL_Tester
 SG_ RCJ4Stat_NEG_CNTR1_WELD_AUX : 50|1@0+ (1,0) [0|0] ""  HIL_Tester
 SG_ RCJ4Stat_POS_CNTR2_WELD_AUX : 51|1@0+ (1,0) [0|0] ""  HIL_Tester
 SG_ RCJ4Stat_PCH_CNTR2_WELD_AUX : 52|1@0+ (1,0) [0|0] ""  HIL_Tester
 SG_ RCJ4Stat_NEG_CNTR2_WELD_AUX : 53|1@0+ (1,0) [0|0] ""  HIL_Tester
 SG_ RCJ4Stat_POS_CNTR3_WELD_AUX : 54|1@0+ (1,0) [0|0] ""  HIL_Tester
 SG_ RCJ4Stat_NEG_CNTR3_WELD_AUX : 55|1@0+ (1,0) [0|0] ""  HIL_Tester
 SG_ RCJ4Stat_Link_MINUS_ALT : 8|1@0+ (1,0) [0|0] ""  HIL_Tester
 SG_ RCJ4Stat_Pack_MINUS_ALT : 9|1@0+ (1,0) [0|0] ""  HIL_Tester
 SG_ RCJ4Stat_Pack_PLUS_ALT : 10|1@0+ (1,0) [0|0] ""  HIL_Tester
 SG_ RCJ4Stat_Link_PLUS_ALT : 11|1@0+ (1,0) [0|0] ""  HIL_Tester
 SG_ RCJ4Stat_POS_LINK_2_ALT : 12|1@0+ (1,0) [0|0] ""  HIL_Tester
 SG_ RCJ4Stat_Link2_MINUS_ALT : 13|1@0+ (1,0) [0|0] ""  HIL_Tester
 SG_ RCJ4Stat_NEG_LINK_3_ALT : 14|1@0+ (1,0) [0|0] ""  HIL_Tester
 SG_ RCJ4Stat_Link2_PLUS_ALT : 15|1@0+ (1,0) [0|0] ""  HIL_Tester
 SG_ RCJ4Stat_COMM_PLUS_ALT : 24|1@0+ (1,0) [0|0] ""  HIL_Tester
 SG_ RCJ4Stat_COMM_MINUS_ALT : 25|1@0+ (1,0) [0|0] ""  HIL_Tester
 SG_ RCJ4Stat_COMM_NC0_ALT : 26|1@0+ (1,0) [0|0] ""  HIL_Tester
 SG_ RCJ4Stat_COMM_SHIELD_ALT : 27|1@0+ (1,0) [0|0] ""  HIL_Tester
 SG_ RCJ4Stat_Iso_PosPack_Error_SC : 40|1@0+ (1,0) [0|0] ""  HIL_Tester
 SG_ RCJ4Stat_Iso_NegPack_Error_SC : 41|1@0+ (1,0) [0|0] ""  HIL_Tester
 SG_ RCJ4Stat_Iso_PosLink_Error_SC : 42|1@0+ (1,0) [0|0] ""  HIL_Tester
 SG_ RCJ4Stat_Iso_NegLink_Error_SC : 43|1@0+ (1,0) [0|0] ""  HIL_Tester
 SG_ RCJ4Stat_POS_CNTR1_HVOpen_OC : 56|1@0+ (1,0) [0|0] ""  HIL_Tester
 SG_ RCJ4Stat_PCH_CNTR1_HVOpen_OC : 57|1@0+ (1,0) [0|0] ""  HIL_Tester
 SG_ RCJ4Stat_NEG_CNTR1_HVOpen_OC : 58|1@0+ (1,0) [0|0] ""  HIL_Tester
 SG_ RCJ4Stat_POS_CNTR2_HVOpen_OC : 59|1@0+ (1,0) [0|0] ""  HIL_Tester
 SG_ RCJ4Stat_PCH_CNTR2_HVOpen_OC : 60|1@0+ (1,0) [0|0] ""  HIL_Tester
 SG_ RCJ4Stat_NEG_CNTR2_HVOpen_OC : 61|1@0+ (1,0) [0|0] ""  HIL_Tester
 SG_ RCJ4Stat_POS_CNTR3_HVOpen_OC : 62|1@0+ (1,0) [0|0] ""  HIL_Tester
 SG_ RCJ4Stat_NEG_CNTR3_HVOpen_OC : 63|1@0+ (1,0) [0|0] ""  HIL_Tester

BO_ 531 RCJ4Cntrl: 8 HIL_Tester
 SG_ RCJ4Cntrl_Link_MINUS_OC : 0|1@0+ (1,0) [0|0] ""  HIL_Tester
 SG_ RCJ4Cntrl_Pack_MINUS_OC : 1|1@0+ (1,0) [0|0] ""  HIL_Tester
 SG_ RCJ4Cntrl_Pack_PLUS_OC : 2|1@0+ (1,0) [0|0] ""  HIL_Tester
 SG_ RCJ4Cntrl_Link_PLUS_OC : 3|1@0+ (1,0) [0|0] ""  HIL_Tester
 SG_ RCJ4Cntrl_POS_LINK_2_OC : 4|1@0+ (1,0) [0|0] ""  HIL_Tester
 SG_ RCJ4Cntrl_POS_LINK_3_OC : 5|1@0+ (1,0) [0|0] ""  HIL_Tester
 SG_ RCJ4Cntrl_NEG_LINK_3_OC : 6|1@0+ (1,0) [0|0] ""  HIL_Tester
 SG_ RCJ4Cntrl_NEG_LINK_2_OC : 7|1@0+ (1,0) [0|0] ""  HIL_Tester
 SG_ RCJ4Cntrl_COMM_PLUS_OC : 16|1@0+ (1,0) [0|0] ""  HIL_Tester
 SG_ RCJ4Cntrl_COMM_MINUS_OC : 17|1@0+ (1,0) [0|0] ""  HIL_Tester
 SG_ RCJ4Cntrl_COMM_NC0_OC : 18|1@0+ (1,0) [0|0] ""  HIL_Tester
 SG_ RCJ4Cntrl_COMM_SHIELD_OC : 19|1@0+ (1,0) [0|0] ""  HIL_Tester
 SG_ RCJ4Cntrl_Link_Active_Dischg_AUX : 32|1@0+ (1,0) [0|0] ""  HIL_Tester
 SG_ RCJ4Cntrl_Link_Weld_AUX : 33|1@0+ (1,0) [0|0] ""  HIL_Tester
 SG_ RCJ4Cntrl_Pack_Weld_AUX : 34|1@0+ (1,0) [0|0] ""  HIL_Tester
 SG_ RCJ4Cntrl_ : 35|1@0+ (1,0) [0|0] ""  HIL_Tester
 SG_ RCJ4Cntrl_CNTR_HiSideStuck_AUX : 36|1@0+ (1,0) [0|0] ""  HIL_Tester
 SG_ RCJ4Cntrl_POS_CNTR1_LoSideSC_AUX : 37|1@0+ (1,0) [0|0] ""  HIL_Tester
 SG_ RCJ4Cntrl_PCH_CNTR1_LoSideSC_AUX : 38|1@0+ (1,0) [0|0] ""  HIL_Tester
 SG_ RCJ4Cntrl_NEG_CNTR1_LoSideSC_AUX : 39|1@0+ (1,0) [0|0] ""  HIL_Tester
 SG_ RCJ4Cntrl_POS_CNTR1_WELD_AUX : 48|1@0+ (1,0) [0|0] ""  HIL_Tester
 SG_ RCJ4Cntrl_PCH_CNTR1_WELD_AUX : 49|1@0+ (1,0) [0|0] ""  HIL_Tester
 SG_ RCJ4Cntrl_NEG_CNTR1_WELD_AUX : 50|1@0+ (1,0) [0|0] ""  HIL_Tester
 SG_ RCJ4Cntrl_POS_CNTR2_WELD_AUX : 51|1@0+ (1,0) [0|0] ""  HIL_Tester
 SG_ RCJ4Cntrl_PCH_CNTR2_WELD_AUX : 52|1@0+ (1,0) [0|0] ""  HIL_Tester
 SG_ RCJ4Cntrl_NEG_CNTR2_WELD_AUX : 53|1@0+ (1,0) [0|0] ""  HIL_Tester
 SG_ RCJ4Cntrl_POS_CNTR3_WELD_AUX : 54|1@0+ (1,0) [0|0] ""  HIL_Tester
 SG_ RCJ4Cntrl_NEG_CNTR3_WELD_AUX : 55|1@0+ (1,0) [0|0] ""  HIL_Tester
 SG_ RCJ4Cntrl_Link_MINUS_ALT : 8|1@0+ (1,0) [0|0] ""  HIL_Tester
 SG_ RCJ4Cntrl_Pack_MINUS_ALT : 9|1@0+ (1,0) [0|0] ""  HIL_Tester
 SG_ RCJ4Cntrl_Pack_PLUS_ALT : 10|1@0+ (1,0) [0|0] ""  HIL_Tester
 SG_ RCJ4Cntrl_Link_PLUS_ALT : 11|1@0+ (1,0) [0|0] ""  HIL_Tester
 SG_ RCJ4Cntrl_POS_LINK_2_ALT : 12|1@0+ (1,0) [0|0] ""  HIL_Tester
 SG_ RCJ4Cntrl_Link2_MINUS_ALT : 13|1@0+ (1,0) [0|0] ""  HIL_Tester
 SG_ RCJ4Cntrl_NEG_LINK_3_ALT : 14|1@0+ (1,0) [0|0] ""  HIL_Tester
 SG_ RCJ4Cntrl_Link2_PLUS_ALT : 15|1@0+ (1,0) [0|0] ""  HIL_Tester
 SG_ RCJ4Cntrl_COMM_PLUS_ALT : 24|1@0+ (1,0) [0|0] ""  HIL_Tester
 SG_ RCJ4Cntrl_COMM_MINUS_ALT : 25|1@0+ (1,0) [0|0] ""  HIL_Tester
 SG_ RCJ4Cntrl_COMM_NC0_ALT : 26|1@0+ (1,0) [0|0] ""  HIL_Tester
 SG_ RCJ4Cntrl_COMM_SHIELD_ALT : 27|1@0+ (1,0) [0|0] ""  HIL_Tester
 SG_ RCJ4Cntrl_Iso_PosPack_Error_SC : 40|1@0+ (1,0) [0|0] ""  HIL_Tester
 SG_ RCJ4Cntrl_Iso_NegPack_Error_SC : 41|1@0+ (1,0) [0|0] ""  HIL_Tester
 SG_ RCJ4Cntrl_Iso_PosLink_Error_SC : 42|1@0+ (1,0) [0|0] ""  HIL_Tester
 SG_ RCJ4Cntrl_Iso_NegLink_Error_SC : 43|1@0+ (1,0) [0|0] ""  HIL_Tester
 SG_ RCJ4Cntrl_POS_CNTR1_HVOpen_OC : 56|1@0+ (1,0) [0|0] ""  HIL_Tester
 SG_ RCJ4Cntrl_PCH_CNTR1_HVOpen_OC : 57|1@0+ (1,0) [0|0] ""  HIL_Tester
 SG_ RCJ4Cntrl_NEG_CNTR1_HVOpen_OC : 58|1@0+ (1,0) [0|0] ""  HIL_Tester
 SG_ RCJ4Cntrl_POS_CNTR2_HVOpen_OC : 59|1@0+ (1,0) [0|0] ""  HIL_Tester
 SG_ RCJ4Cntrl_PCH_CNTR2_HVOpen_OC : 60|1@0+ (1,0) [0|0] ""  HIL_Tester
 SG_ RCJ4Cntrl_NEG_CNTR2_HVOpen_OC : 61|1@0+ (1,0) [0|0] ""  HIL_Tester
 SG_ RCJ4Cntrl_POS_CNTR3_HVOpen_OC : 62|1@0+ (1,0) [0|0] ""  HIL_Tester
 SG_ RCJ4Cntrl_NEG_CNTR3_HVOpen_OC : 63|1@0+ (1,0) [0|0] ""  HIL_Tester

BO_ 274 RCJ7Stat: 8 HIL
 SG_ RCJ7Stat_ADDR_GND_NTC4_GND_OC : 0|1@0+ (1,0) [0|0] ""  HIL_Tester
 SG_ RCJ7Stat_NEG_CNTR3_PLUS_OC : 1|1@0+ (1,0) [0|0] ""  HIL_Tester
 SG_ RCJ7Stat_POS_CNTR3_PLUS_OC : 2|1@0+ (1,0) [0|0] ""  HIL_Tester
 SG_ RCJ7Stat_NEG_CNTR2_PLUS_OC : 3|1@0+ (1,0) [0|0] ""  HIL_Tester
 SG_ RCJ7Stat_PCH_CNTR2_PLUS_OC : 4|1@0+ (1,0) [0|0] ""  HIL_Tester
 SG_ RCJ7Stat_POS_CNTR2_PLUS_OC : 5|1@0+ (1,0) [0|0] ""  HIL_Tester
 SG_ RCJ7Stat_SCAN_HIGH_OC : 6|1@0+ (1,0) [0|0] ""  HIL_Tester
 SG_ RCJ7Stat_ADDR_GND_NTC3_GND_OC : 7|1@0+ (1,0) [0|0] ""  HIL_Tester
 SG_ RCJ7Stat_ADDR4_NTC4_PRES_OC : 16|1@0+ (1,0) [0|0] ""  HIL_Tester
 SG_ RCJ7Stat_GPIO2_PLUS_OC : 17|1@0+ (1,0) [0|0] ""  HIL_Tester
 SG_ RCJ7Stat_NEG_CNTR3_MINUS_OC : 18|1@0+ (1,0) [0|0] ""  HIL_Tester
 SG_ RCJ7Stat_POS_CNTR3_MINUS_OC : 19|1@0+ (1,0) [0|0] ""  HIL_Tester
 SG_ RCJ7Stat_NEG_CNTR2_MINUS_OC : 20|1@0+ (1,0) [0|0] ""  HIL_Tester
 SG_ RCJ7Stat_PCH2_MINUS_OC : 21|1@0+ (1,0) [0|0] ""  HIL_Tester
 SG_ RCJ7Stat_POS_CNTR2_MINUS_OC : 22|1@0+ (1,0) [0|0] ""  HIL_Tester
 SG_ RCJ7Stat_SCAN_LOW_OC : 23|1@0+ (1,0) [0|0] ""  HIL_Tester
 SG_ RCJ7Stat_ADDR3_NTC3_OC : 32|1@0+ (1,0) [0|0] ""  HIL_Tester
 SG_ RCJ7Stat_PRESSURE_SUPPLY_OC : 33|1@0+ (1,0) [0|0] ""  HIL_Tester
 SG_ RCJ7Stat_ADDR_GND_NTC4_GND_ALT : 8|1@0+ (1,0) [0|0] ""  HIL_Tester
 SG_ RCJ7Stat_NEG_CNTR3_PLUS_AUX : 9|1@0+ (1,0) [0|0] ""  HIL_Tester
 SG_ RCJ7Stat_POS_CNTR3_PLUS_AUX : 10|1@0+ (1,0) [0|0] ""  HIL_Tester
 SG_ RCJ7Stat_NEG_CNTR2_PLUS_AUX : 11|1@0+ (1,0) [0|0] ""  HIL_Tester
 SG_ RCJ7Stat_PCH_CNTR2_PLUS_AUX : 12|1@0+ (1,0) [0|0] ""  HIL_Tester
 SG_ RCJ7Stat_POS_CNTR2_PLUS_AUX : 13|1@0+ (1,0) [0|0] ""  HIL_Tester
 SG_ RCJ7Stat_SCAN_HIGH_ALT : 14|1@0+ (1,0) [0|0] ""  HIL_Tester
 SG_ RCJ7Stat_ADDR_GND_NTC3_GND_AUX : 15|1@0+ (1,0) [0|0] ""  HIL_Tester
 SG_ RCJ7Stat_ADDR4_NTC4_PRES_ALT : 24|1@0+ (1,0) [0|0] ""  HIL_Tester
 SG_ RCJ7Stat_GPIO2_PLUS_ALT : 25|1@0+ (1,0) [0|0] ""  HIL_Tester
 SG_ RCJ7Stat_NEG_CNTR3_MINUS_AUX : 26|1@0+ (1,0) [0|0] ""  HIL_Tester
 SG_ RCJ7Stat_POS_CNTR3_MINUS_AUX : 27|1@0+ (1,0) [0|0] ""  HIL_Tester
 SG_ RCJ7Stat_NEG_CNTR2_MINUS_AUX : 28|1@0+ (1,0) [0|0] ""  HIL_Tester
 SG_ RCJ7Stat_PCH2_MINUS_AUX : 29|1@0+ (1,0) [0|0] ""  HIL_Tester
 SG_ RCJ7Stat_POS_CNTR2_MINUS_AUX : 30|1@0+ (1,0) [0|0] ""  HIL_Tester
 SG_ RCJ7Stat_SCAN_LOW_ALT : 31|1@0+ (1,0) [0|0] ""  HIL_Tester
 SG_ RCJ7Stat_ADDR3_NTC3_ALT : 40|1@0+ (1,0) [0|0] ""  HIL_Tester
 SG_ RCJ7Stat_PRESSURE_SUPPLY_AUX : 41|1@0+ (1,0) [0|0] ""  HIL_Tester

BO_ 530 RCJ7Cntrl: 8 HIL_Tester
 SG_ RC_HVIL_Cntrl_R4007 : 63|1@0+ (1,0) [0|0] "" Vector__XXX
 SG_ RC_HVIL_Cntrl_R4006 : 62|1@0+ (1,0) [0|0] "" Vector__XXX
 SG_ RC_HVIL_Cntrl_R4005 : 61|1@0+ (1,0) [0|0] "" Vector__XXX
 SG_ RC_HVIL_Cntrl_R4004 : 60|1@0+ (1,0) [0|0] "" Vector__XXX
 SG_ RC_HVIL_Cntrl_R4003 : 55|1@0+ (1,0) [0|0] "" Vector__XXX
 SG_ RC_HVIL_Cntrl_R4002 : 54|1@0+ (1,0) [0|0] "" Vector__XXX
 SG_ RC_HVIL_Cntrl_R4001 : 53|1@0+ (1,0) [0|0] "" Vector__XXX
 SG_ RC_HVIL_Cntrl_R4000 : 52|1@0+ (1,0) [0|0] "" Vector__XXX
 SG_ RCJ1Cntrl_ADDR4_OC : 48|1@0+ (1,0) [0|0] "" Vector__XXX
 SG_ RCJ1Cntrl_ADDR4_ALT : 56|1@0+ (1,0) [0|0] "" Vector__XXX
 SG_ RCJ7Cntrl_ADDR_GND_NTC4_GND_OC : 0|1@0+ (1,0) [0|0] ""  HIL_Tester
 SG_ RCJ7Cntrl_NEG_CNTR3_PLUS_OC : 1|1@0+ (1,0) [0|0] ""  HIL_Tester
 SG_ RCJ7Cntrl_POS_CNTR3_PLUS_OC : 2|1@0+ (1,0) [0|0] ""  HIL_Tester
 SG_ RCJ7Cntrl_NEG_CNTR2_PLUS_OC : 3|1@0+ (1,0) [0|0] ""  HIL_Tester
 SG_ RCJ7Cntrl_PCH_CNTR2_PLUS_OC : 4|1@0+ (1,0) [0|0] ""  HIL_Tester
 SG_ RCJ7Cntrl_POS_CNTR2_PLUS_OC : 5|1@0+ (1,0) [0|0] ""  HIL_Tester
 SG_ RCJ7Cntrl_SCAN_HIGH_OC : 6|1@0+ (1,0) [0|0] ""  HIL_Tester
 SG_ RCJ7Cntrl_ADDR_GND_NTC3_GND_OC : 7|1@0+ (1,0) [0|0] ""  HIL_Tester
 SG_ RCJ7Cntrl_ADDR4_NTC4_PRES_OC : 16|1@0+ (1,0) [0|0] ""  HIL_Tester
 SG_ RCJ7Cntrl_GPIO2_PLUS_OC : 17|1@0+ (1,0) [0|0] ""  HIL_Tester
 SG_ RCJ7Cntrl_NEG_CNTR3_MINUS_OC : 18|1@0+ (1,0) [0|0] ""  HIL_Tester
 SG_ RCJ7Cntrl_POS_CNTR3_MINUS_OC : 19|1@0+ (1,0) [0|0] ""  HIL_Tester
 SG_ RCJ7Cntrl_NEG_CNTR2_MINUS_OC : 20|1@0+ (1,0) [0|0] ""  HIL_Tester
 SG_ RCJ7Cntrl_PCH2_MINUS_OC : 21|1@0+ (1,0) [0|0] ""  HIL_Tester
 SG_ RCJ7Cntrl_POS_CNTR2_MINUS_OC : 22|1@0+ (1,0) [0|0] ""  HIL_Tester
 SG_ RCJ7Cntrl_SCAN_LOW_OC : 23|1@0+ (1,0) [0|0] ""  HIL_Tester
 SG_ RCJ7Cntrl_ADDR3_NTC3_OC : 32|1@0+ (1,0) [0|0] ""  HIL_Tester
 SG_ RCJ7Cntrl_PRESSURE_SUPPLY_OC : 33|1@0+ (1,0) [0|0] ""  HIL_Tester
 SG_ RCJ7Cntrl_ADDR_GND_NTC4_GND_ALT : 8|1@0+ (1,0) [0|0] ""  HIL_Tester
 SG_ RCJ7Cntrl_NEG_CNTR3_PLUS_AUX : 9|1@0+ (1,0) [0|0] ""  HIL_Tester
 SG_ RCJ7Cntrl_POS_CNTR3_PLUS_AUX : 10|1@0+ (1,0) [0|0] ""  HIL_Tester
 SG_ RCJ7Cntrl_NEG_CNTR2_PLUS_AUX : 11|1@0+ (1,0) [0|0] ""  HIL_Tester
 SG_ RCJ7Cntrl_PCH_CNTR2_PLUS_AUX : 12|1@0+ (1,0) [0|0] ""  HIL_Tester
 SG_ RCJ7Cntrl_POS_CNTR2_PLUS_AUX : 13|1@0+ (1,0) [0|0] ""  HIL_Tester
 SG_ RCJ7Cntrl_SCAN_HIGH_ALT : 14|1@0+ (1,0) [0|0] ""  HIL_Tester
 SG_ RCJ7Cntrl_ADDR_GND_NTC3_GND_AUX : 15|1@0+ (1,0) [0|0] ""  HIL_Tester
 SG_ RCJ7Cntrl_ADDR4_NTC4_PRES_ALT : 24|1@0+ (1,0) [0|0] ""  HIL_Tester
 SG_ RCJ7Cntrl_GPIO2_PLUS_ALT : 25|1@0+ (1,0) [0|0] ""  HIL_Tester
 SG_ RCJ7Cntrl_NEG_CNTR3_MINUS_AUX : 26|1@0+ (1,0) [0|0] ""  HIL_Tester
 SG_ RCJ7Cntrl_POS_CNTR3_MINUS_AUX : 27|1@0+ (1,0) [0|0] ""  HIL_Tester
 SG_ RCJ7Cntrl_NEG_CNTR2_MINUS_AUX : 28|1@0+ (1,0) [0|0] ""  HIL_Tester
 SG_ RCJ7Cntrl_PCH2_MINUS_AUX : 29|1@0+ (1,0) [0|0] ""  HIL_Tester
 SG_ RCJ7Cntrl_POS_CNTR2_MINUS_AUX : 30|1@0+ (1,0) [0|0] ""  HIL_Tester
 SG_ RCJ7Cntrl_SCAN_LOW_ALT : 31|1@0+ (1,0) [0|0] ""  HIL_Tester
 SG_ RCJ7Cntrl_ADDR3_NTC3_ALT : 40|1@0+ (1,0) [0|0] ""  HIL_Tester
 SG_ RCJ7Cntrl_PRESSURE_SUPPLY_AUX : 41|1@0+ (1,0) [0|0] ""  HIL_Tester

BO_ 282 RCCMBStat: 8 HIL
 SG_ RCCMBStat_SupplyPlus_HImp : 43|1@0+ (1,0) [0|0] "" Vector__XXX
 SG_ RCCMBStat_SupplyMinus_HImp : 44|1@0+ (1,0) [0|0] "" Vector__XXX
 SG_ RCCMBStat_CV0_OC : 34|1@0+ (1,0) [0|0] "" Vector__XXX
 SG_ RCCMBStat_CV0_HImp : 42|1@0+ (1,0) [0|0] "" Vector__XXX
 SG_ RCCMBStat_CV9_HImp : 24|1@0+ (1,0) [0|0] "" Vector__XXX
 SG_ RCCMBStat_CV8_HImp : 15|1@0+ (1,0) [0|0] "" Vector__XXX
 SG_ RCCMBStat_CV7_HImp : 14|1@0+ (1,0) [0|0] "" Vector__XXX
 SG_ RCCMBStat_CV6_HImp : 13|1@0+ (1,0) [0|0] "" Vector__XXX
 SG_ RCCMBStat_CV5_HImp : 12|1@0+ (1,0) [0|0] "" Vector__XXX
 SG_ RCCMBStat_CV4_HImp : 11|1@0+ (1,0) [0|0] "" Vector__XXX
 SG_ RCCMBStat_CV3_HImp : 10|1@0+ (1,0) [0|0] "" Vector__XXX
 SG_ RCCMBStat_CV2_HImp : 9|1@0+ (1,0) [0|0] "" Vector__XXX
 SG_ RCCMBStat_CV1_HImp : 8|1@0+ (1,0) [0|0] "" Vector__XXX
 SG_ RCCMBStat_CV18_HImp : 41|1@0+ (1,0) [0|0] "" Vector__XXX
 SG_ RCCMBStat_CV17_HImp : 40|1@0+ (1,0) [0|0] "" Vector__XXX
 SG_ RCCMBStat_CV16_HImp : 31|1@0+ (1,0) [0|0] "" Vector__XXX
 SG_ RCCMBStat_CV15_HImp : 30|1@0+ (1,0) [0|0] "" Vector__XXX
 SG_ RCCMBStat_CV14_HImp : 29|1@0+ (1,0) [0|0] "" Vector__XXX
 SG_ RCCMBStat_CV13_HImp : 28|1@0+ (1,0) [0|0] "" Vector__XXX
 SG_ RCCMBStat_CV12_HImp : 27|1@0+ (1,0) [0|0] "" Vector__XXX
 SG_ RCCMBStat_CV11_HImp : 26|1@0+ (1,0) [0|0] "" Vector__XXX
 SG_ RCCMBStat_CV10_HImp : 25|1@0+ (1,0) [0|0] "" Vector__XXX
 SG_ RCCMBStat_CV1_OC : 0|1@0+ (1,0) [0|0] ""  HIL_Tester
 SG_ RCCMBStat_CV2_OC : 1|1@0+ (1,0) [0|0] ""  HIL_Tester
 SG_ RCCMBStat_CV3_OC : 2|1@0+ (1,0) [0|0] ""  HIL_Tester
 SG_ RCCMBStat_CV4_OC : 3|1@0+ (1,0) [0|0] ""  HIL_Tester
 SG_ RCCMBStat_CV5_OC : 4|1@0+ (1,0) [0|0] ""  HIL_Tester
 SG_ RCCMBStat_CV6_OC : 5|1@0+ (1,0) [0|0] ""  HIL_Tester
 SG_ RCCMBStat_CV7_OC : 6|1@0+ (1,0) [0|0] ""  HIL_Tester
 SG_ RCCMBStat_CV8_OC : 7|1@0+ (1,0) [0|0] ""  HIL_Tester
 SG_ RCCMBStat_CV9_OC : 16|1@0+ (1,0) [0|0] ""  HIL_Tester
 SG_ RCCMBStat_CV10_OC : 17|1@0+ (1,0) [0|0] ""  HIL_Tester
 SG_ RCCMBStat_CV11_OC : 18|1@0+ (1,0) [0|0] ""  HIL_Tester
 SG_ RCCMBStat_CV12_OC : 19|1@0+ (1,0) [0|0] ""  HIL_Tester
 SG_ RCCMBStat_CV13_OC : 20|1@0+ (1,0) [0|0] ""  HIL_Tester
 SG_ RCCMBStat_CV14_OC : 21|1@0+ (1,0) [0|0] ""  HIL_Tester
 SG_ RCCMBStat_CV15_OC : 22|1@0+ (1,0) [0|0] ""  HIL_Tester
 SG_ RCCMBStat_CV16_OC : 23|1@0+ (1,0) [0|0] ""  HIL_Tester
 SG_ RCCMBStat_CV17_OC : 32|1@0+ (1,0) [0|0] ""  HIL_Tester
 SG_ RCCMBStat_CV18_OC : 33|1@0+ (1,0) [0|0] ""  HIL_Tester
 SG_ RCCMBStat_SupplyPlus : 35|1@0+ (1,0) [0|0] ""  HIL_Tester
 SG_ RCCMBStat_SupplyMinus : 36|1@0+ (1,0) [0|0] ""  HIL_Tester
 SG_ RCCMBStat_CommDaisyChain1 : 37|1@0+ (1,0) [0|0] ""  HIL_Tester
 SG_ RCCMBStat_CommDaisyChain2 : 38|1@0+ (1,0) [0|0] ""  HIL_Tester

BO_ 538 RCCMBCntrl: 8 HIL_Tester
 SG_ RCCMBCntrl_SupplyPlus_HImp : 43|1@0+ (1,0) [0|0] "" Vector__XXX
 SG_ RCCMBCntrl_SupplyMinus_HImp : 44|1@0+ (1,0) [0|0] "" Vector__XXX
 SG_ RCCMBCntrl_CV0_OC : 34|1@0+ (1,0) [0|0] "" Vector__XXX
 SG_ RCCMBCntrl_CV0_HImp : 42|1@0+ (1,0) [0|0] "" Vector__XXX
 SG_ RCCMBCntrl_CV9_HImp : 24|1@0+ (1,0) [0|0] "" Vector__XXX
 SG_ RCCMBCntrl_CV8_HImp : 15|1@0+ (1,0) [0|0] "" Vector__XXX
 SG_ RCCMBCntrl_CV7_HImp : 14|1@0+ (1,0) [0|0] "" Vector__XXX
 SG_ RCCMBCntrl_CV6_HImp : 13|1@0+ (1,0) [0|0] "" Vector__XXX
 SG_ RCCMBCntrl_CV5_HImp : 12|1@0+ (1,0) [0|0] "" Vector__XXX
 SG_ RCCMBCntrl_CV4_HImp : 11|1@0+ (1,0) [0|0] "" Vector__XXX
 SG_ RCCMBCntrl_CV3_HImp : 10|1@0+ (1,0) [0|0] "" Vector__XXX
 SG_ RCCMBCntrl_CV2_HImp : 9|1@0+ (1,0) [0|0] "" Vector__XXX
 SG_ RCCMBCntrl_CV18_HImp : 41|1@0+ (1,0) [0|0] "" Vector__XXX
 SG_ RCCMBCntrl_CV17_HImp : 40|1@0+ (1,0) [0|0] "" Vector__XXX
 SG_ RCCMBCntrl_CV16_HImp : 31|1@0+ (1,0) [0|0] "" Vector__XXX
 SG_ RCCMBCntrl_CV15_HImp : 30|1@0+ (1,0) [0|0] "" Vector__XXX
 SG_ RCCMBCntrl_CV14_HImp : 29|1@0+ (1,0) [0|0] "" Vector__XXX
 SG_ RCCMBCntrl_CV13_HImp : 28|1@0+ (1,0) [0|0] "" Vector__XXX
 SG_ RCCMBCntrl_CV12_HImp : 27|1@0+ (1,0) [0|0] "" Vector__XXX
 SG_ RCCMBCntrl_CV11_HImp : 26|1@0+ (1,0) [0|0] "" Vector__XXX
 SG_ RCCMBCntrl_CV10_HImp : 25|1@0+ (1,0) [0|0] "" Vector__XXX
 SG_ RCCMBCntrl_CV1_HImp : 8|1@0+ (1,0) [0|0] "" Vector__XXX
 SG_ RCCMBCntrl_CV1_OC : 0|1@0+ (1,0) [0|0] ""  HIL
 SG_ RCCMBCntrl_CV2_OC : 1|1@0+ (1,0) [0|0] ""  HIL
 SG_ RCCMBCntrl_CV3_OC : 2|1@0+ (1,0) [0|0] ""  HIL
 SG_ RCCMBCntrl_CV4_OC : 3|1@0+ (1,0) [0|0] ""  HIL
 SG_ RCCMBCntrl_CV5_OC : 4|1@0+ (1,0) [0|0] ""  HIL
 SG_ RCCMBCntrl_CV6_OC : 5|1@0+ (1,0) [0|0] ""  HIL
 SG_ RCCMBCntrl_CV7_OC : 6|1@0+ (1,0) [0|0] ""  HIL
 SG_ RCCMBCntrl_CV8_OC : 7|1@0+ (1,0) [0|0] ""  HIL
 SG_ RCCMBCntrl_CV9_OC : 16|1@0+ (1,0) [0|0] ""  HIL
 SG_ RCCMBCntrl_CV10_OC : 17|1@0+ (1,0) [0|0] ""  HIL
 SG_ RCCMBCntrl_CV11_OC : 18|1@0+ (1,0) [0|0] ""  HIL
 SG_ RCCMBCntrl_CV12_OC : 19|1@0+ (1,0) [0|0] ""  HIL
 SG_ RCCMBCntrl_CV13_OC : 20|1@0+ (1,0) [0|0] ""  HIL
 SG_ RCCMBCntrl_CV14_OC : 21|1@0+ (1,0) [0|0] ""  HIL
 SG_ RCCMBCntrl_CV15_OC : 22|1@0+ (1,0) [0|0] ""  HIL
 SG_ RCCMBCntrl_CV16_OC : 23|1@0+ (1,0) [0|0] ""  HIL
 SG_ RCCMBCntrl_CV17_OC : 32|1@0+ (1,0) [0|0] ""  HIL
 SG_ RCCMBCntrl_CV18_OC : 33|1@0+ (1,0) [0|0] ""  HIL
 SG_ RCCMBCntrl_SupplyPlus : 35|1@0+ (1,0) [0|0] ""  HIL
 SG_ RCCMBCntrl_SupplyMinus : 36|1@0+ (1,0) [0|0] ""  HIL
 SG_ RCCMBCntrl_CommDaisyChain1 : 37|1@0+ (1,0) [0|0] ""  HIL
 SG_ RCCMBCntrl_CommDaisyChain2 : 38|1@0+ (1,0) [0|0] ""  HIL
 SG_ RCCMBCntrl_IsoPlus : 46|1@0+ (1,0) [0|0] ""  HIL
 SG_ RCCMBCntrl_IsoMinus : 47|1@0+ (1,0) [0|0] ""  HIL

CM_ BO_ 3221225472 "This is a message for not used signals, created by Vector CANdb++ DBC OLE DB Provider.";
CM_ SG_ 363 LinStatus_Error_crc_Slave2 "to be added to crc data";
CM_ SG_ 363 LinStatus_Error_cnt_Slave2 "to be added to cnt";
CM_ SG_ 362 LinStatus_Error_crc_Slave1 "to be added to crc data";
CM_ SG_ 362 LinStatus_Error_cnt_Slave1 "to be added to cnt";
CM_ SG_ 361 LinStatus_Error_crc_Master "to be added to crc data";
CM_ SG_ 361 LinStatus_Error_cnt_Master "to be added to cnt";
CM_ SG_ 619 LinCntrl_Error_crc_Slave2 "to be added to crc data";
CM_ SG_ 619 LinCntrl_Error_cnt_Slave2 "to be added to cnt";
CM_ SG_ 618 LinCntrl_Error_crc_Slave1 "to be added to crc data";
CM_ SG_ 618 LinCntrl_Error_cnt_Slave1 "to be added to cnt";
CM_ SG_ 617 LinCntrl_Error_crc_Master "to be added to crc data";
CM_ SG_ 617 LinCntrl_Error_cnt_Master "to be added to cnt";
BA_DEF_ SG_  "GenSigSendType" ENUM  "Cyclic","OnWrite","OnWriteWithRepetition","OnChange","OnChangeWithRepetition","IfActive","IfActiveWithRepetition","NoSigSendType";
BA_DEF_ BO_  "GenMsgCycleTime" INT 0 0;
BA_DEF_ BO_  "GenMsgSendType" ENUM  "Cyclic","not_used","not_used","not_used","not_used","Cyclic","not_used","IfActive","NoMsgSendType";
BA_DEF_ BU_  "NmStationAddress" HEX 0 0;
BA_DEF_  "DBName" STRING ;
BA_DEF_  "BusType" STRING ;
BA_DEF_DEF_  "GenSigSendType" "Cyclic";
BA_DEF_DEF_  "GenMsgCycleTime" 0;
BA_DEF_DEF_  "GenMsgSendType" "NoMsgSendType";
BA_DEF_DEF_  "NmStationAddress" 0;
BA_DEF_DEF_  "DBName" "";
BA_DEF_DEF_  "BusType" "CAN";
BA_ "DBName" "hil";
BA_ "NmStationAddress" BU_ LOGGER 1;
BA_ "GenMsgSendType" BO_ 553 0;
BA_ "GenMsgCycleTime" BO_ 553 20;
BA_ "GenMsgSendType" BO_ 544 0;
BA_ "GenMsgCycleTime" BO_ 544 20;
BA_ "GenMsgCycleTime" BO_ 659 100;
BA_ "GenMsgCycleTime" BO_ 658 100;
BA_ "GenMsgCycleTime" BO_ 657 100;
BA_ "GenMsgCycleTime" BO_ 656 100;
BA_ "GenMsgCycleTime" BO_ 289 100;
BA_ "GenMsgCycleTime" BO_ 290 100;
BA_ "GenMsgCycleTime" BO_ 291 100;
BA_ "GenMsgCycleTime" BO_ 292 100;
BA_ "GenMsgCycleTime" BO_ 293 100;
BA_ "GenMsgCycleTime" BO_ 545 100;
BA_ "GenMsgCycleTime" BO_ 546 100;
BA_ "GenMsgCycleTime" BO_ 547 100;
BA_ "GenMsgCycleTime" BO_ 548 100;
BA_ "GenMsgCycleTime" BO_ 549 100;
BA_ "GenMsgCycleTime" BO_ 298 100;
BA_ "GenMsgCycleTime" BO_ 299 100;
BA_ "GenMsgCycleTime" BO_ 300 100;
BA_ "GenMsgCycleTime" BO_ 301 100;
BA_ "GenMsgCycleTime" BO_ 302 100;
BA_ "GenMsgCycleTime" BO_ 554 100;
BA_ "GenMsgCycleTime" BO_ 555 100;
BA_ "GenMsgCycleTime" BO_ 556 100;
BA_ "GenMsgCycleTime" BO_ 557 100;
BA_ "GenMsgCycleTime" BO_ 558 100;
BA_ "GenMsgCycleTime" BO_ 321 100;
BA_ "GenMsgCycleTime" BO_ 322 100;
BA_ "GenMsgCycleTime" BO_ 323 100;
BA_ "GenMsgCycleTime" BO_ 324 100;
BA_ "GenMsgCycleTime" BO_ 325 100;
BA_ "GenMsgCycleTime" BO_ 326 100;
BA_ "GenMsgCycleTime" BO_ 327 100;
BA_ "GenMsgCycleTime" BO_ 328 100;
BA_ "GenMsgCycleTime" BO_ 329 100;
BA_ "GenMsgCycleTime" BO_ 337 100;
BA_ "GenMsgCycleTime" BO_ 338 100;
BA_ "GenMsgCycleTime" BO_ 339 100;
BA_ "GenMsgCycleTime" BO_ 340 100;
BA_ "GenMsgCycleTime" BO_ 341 100;
BA_ "GenMsgCycleTime" BO_ 342 100;
BA_ "GenMsgCycleTime" BO_ 343 100;
BA_ "GenMsgCycleTime" BO_ 344 100;
BA_ "GenMsgCycleTime" BO_ 345 100;
BA_ "GenMsgCycleTime" BO_ 593 100;
BA_ "GenMsgCycleTime" BO_ 594 100;
BA_ "GenMsgCycleTime" BO_ 595 100;
BA_ "GenMsgCycleTime" BO_ 596 100;
BA_ "GenMsgCycleTime" BO_ 597 100;
BA_ "GenMsgCycleTime" BO_ 598 100;
BA_ "GenMsgCycleTime" BO_ 599 100;
BA_ "GenMsgCycleTime" BO_ 600 100;
BA_ "GenMsgCycleTime" BO_ 601 100;
BA_ "GenMsgCycleTime" BO_ 258 100;
BA_ "GenMsgCycleTime" BO_ 257 100;
BA_ "GenMsgCycleTime" BO_ 359 100;
BA_ "GenMsgCycleTime" BO_ 363 100;
BA_ "GenMsgCycleTime" BO_ 362 100;
BA_ "GenMsgCycleTime" BO_ 361 100;
BA_ "GenMsgCycleTime" BO_ 619 100;
BA_ "GenMsgCycleTime" BO_ 618 100;
BA_ "GenMsgCycleTime" BO_ 617 100;
BA_ "GenMsgCycleTime" BO_ 353 100;
BA_ "GenMsgCycleTime" BO_ 610 100;
BA_ "GenMsgCycleTime" BO_ 355 100;
BA_ "GenMsgCycleTime" BO_ 609 100;
BA_ "GenMsgCycleTime" BO_ 354 100;
BA_ "GenMsgCycleTime" BO_ 611 100;
BA_ "GenMsgCycleTime" BO_ 2 100;
BA_ "GenMsgCycleTime" BO_ 273 100;
BA_ "GenMsgCycleTime" BO_ 529 100;
BA_ "GenMsgCycleTime" BO_ 275 100;
BA_ "GenMsgCycleTime" BO_ 531 100;
BA_ "GenMsgCycleTime" BO_ 274 100;
BA_ "GenMsgCycleTime" BO_ 530 100;
BA_ "GenMsgCycleTime" BO_ 282 100;
BA_ "GenMsgCycleTime" BO_ 538 100;
VAL_ 3221225472 ISOSPI_request_03 13 "Self Tests

" 12 "Clear all Balancing R

" 11 "Enable Balancing

" 9 "Read raw config data

" 8 "Read Status registers

" 7 "Start Status Meas

" 6 "Read GPIO voltages

" 5 "Start GPIO Meas

" 4 "Read Cellvoltages

" 3 "Start Cellvoltage Meas

" 2 "Read ASIC Config

" 1 "Write ASIC config" ;
VAL_ 3221225472 ISOSPI_request_04 13 "Self Tests

" 12 "Clear all Balancing R

" 11 "Enable Balancing

" 9 "Read raw config data

" 8 "Read Status registers

" 7 "Start Status Meas

" 6 "Read GPIO voltages

" 5 "Start GPIO Meas

" 4 "Read Cellvoltages

" 3 "Start Cellvoltage Meas

" 2 "Read ASIC Config

" 1 "Write ASIC config" ;
VAL_ 3221225472 ISOSPI_request_05 13 "Self Tests

" 12 "Clear all Balancing R

" 11 "Enable Balancing

" 9 "Read raw config data

" 8 "Read Status registers

" 7 "Start Status Meas

" 6 "Read GPIO voltages

" 5 "Start GPIO Meas

" 4 "Read Cellvoltages

" 3 "Start Cellvoltage Meas

" 2 "Read ASIC Config

" 1 "Write ASIC config" ;
VAL_ 3221225472 ISOSPI_request_02 13 "Self Tests

" 12 "Clear all Balancing R

" 11 "Enable Balancing

" 9 "Read raw config data

" 8 "Read Status registers

" 7 "Start Status Meas

" 6 "Read GPIO voltages

" 5 "Start GPIO Meas

" 4 "Read Cellvoltages

" 3 "Start Cellvoltage Meas

" 2 "Read ASIC Config

" 1 "Write ASIC config" ;
VAL_ 3221225472 ISOSPI_request_01 13 "Self Tests

" 12 "Clear all Balancing R

" 11 "Enable Balancing

" 9 "Read raw config data

" 8 "Read Status registers

" 7 "Start Status Meas

" 6 "Read GPIO voltages

" 5 "Start GPIO Meas

" 4 "Read Cellvoltages

" 3 "Start Cellvoltage Meas

" 2 "Read ASIC Config

" 1 "Write ASIC config" ;
VAL_ 368 ISOSPI_request_00 13 "Self Tests

" 12 "Clear all Balancing R

" 11 "Enable Balancing

" 9 "Read raw config data

" 8 "Read Status registers

" 7 "Start Status Meas

" 6 "Read GPIO voltages

" 5 "Start GPIO Meas

" 4 "Read Cellvoltages

" 3 "Start Cellvoltage Meas

" 2 "Read ASIC Config

" 1 "Write ASIC config" ;
VAL_ 629 ISOSPI_request_00 13 "Self Tests

" 12 "Clear all Balancing R

" 11 "Enable Balancing

" 9 "Read raw config data

" 8 "Read Status registers

" 7 "Start Status Meas

" 6 "Read GPIO voltages

" 5 "Start GPIO Meas

" 4 "Read Cellvoltages

" 3 "Start Cellvoltage Meas

" 2 "Read ASIC Config

" 1 "Write ASIC config" ;
VAL_ 628 ISOSPI_request_00 13 "Self Tests

" 12 "Clear all Balancing R

" 11 "Enable Balancing

" 9 "Read raw config data

" 8 "Read Status registers

" 7 "Start Status Meas

" 6 "Read GPIO voltages

" 5 "Start GPIO Meas

" 4 "Read Cellvoltages

" 3 "Start Cellvoltage Meas

" 2 "Read ASIC Config

" 1 "Write ASIC config" ;
VAL_ 627 ISOSPI_request_00 13 "Self Tests

" 12 "Clear all Balancing R

" 11 "Enable Balancing

" 9 "Read raw config data

" 8 "Read Status registers

" 7 "Start Status Meas

" 6 "Read GPIO voltages

" 5 "Start GPIO Meas

" 4 "Read Cellvoltages

" 3 "Start Cellvoltage Meas

" 2 "Read ASIC Config

" 1 "Write ASIC config" ;
VAL_ 626 ISOSPI_request_00 13 "Self Tests

" 12 "Clear all Balancing R

" 11 "Enable Balancing

" 9 "Read raw config data

" 8 "Read Status registers

" 7 "Start Status Meas

" 6 "Read GPIO voltages

" 5 "Start GPIO Meas

" 4 "Read Cellvoltages

" 3 "Start Cellvoltage Meas

" 2 "Read ASIC Config

" 1 "Write ASIC config" ;
VAL_ 625 ISOSPI_request_00 13 "Self Tests

" 12 "Clear all Balancing R

" 11 "Enable Balancing

" 9 "Read raw config data

" 8 "Read Status registers

" 7 "Start Status Meas

" 6 "Read GPIO voltages

" 5 "Start GPIO Meas

" 4 "Read Cellvoltages

" 3 "Start Cellvoltage Meas

" 2 "Read ASIC Config

" 1 "Write ASIC config" ;
VAL_ 624 ISOSPI_selftests 4 "ADC Memory self test

" 3 "Open wire self test

" 2 "ADC Redundancy Self Test

" 1 "ADC Overlap Self Test

" 0 "MUX Decoder Self Test" ;
VAL_ 624 ISOSPI_ChanneltoBalance 18 "Cell 18

" 17 "Cell 17

" 16 "Cell 16

" 15 "Cell 15

" 14 "Cell 14

" 13 "Cell 13

" 12 "Cell 12

" 11 "Cell 11

" 10 "Cell 10

" 9 "Cell 9

" 8 "Cell 8

" 7 "Cell 7

" 6 "Cell 6

" 5 "Cell 5

" 4 "Cell 4

" 3 "Cell 3

" 2 "Cell 2

" 1 "Cell 1" 0 "all Cells" ;
VAL_ 624 ISOSPI_request_00 13 "Self Tests

" 12 "Clear all Balancing R

" 11 "Enable Balancing

" 9 "Read raw config data

" 8 "Read Status registers

" 7 "Start Status Meas

" 6 "Read GPIO voltages

" 5 "Start GPIO Meas

" 4 "Read Cellvoltages

" 3 "Start Cellvoltage Meas

" 2 "Read ASIC Config

" 1 "Write ASIC config" ;
VAL_ 297 DAC_CMB_Status_Channel 67 "05_04" 66 "05_03" 65 "05_02" 64 "05_01" 51 "04_04" 50 "04_03" 49 "04_02" 48 "04_01" 35 "03_04" 34 "03_03" 33 "03_02" 32 "03_01" 19 "02_04" 18 "02_03" 17 "02_02" 16 "02_01" 3 "01_04" 2 "01_03" 1 "01_02" 0 "01_01" ;
VAL_ 553 DAC_CMB_Cntrl_Channel 67 "05_04" 66 "05_03" 65 "05_02" 64 "05_01" 51 "04_04" 50 "04_03" 49 "04_02" 48 "04_01" 35 "03_04" 34 "03_03" 33 "03_02" 32 "03_01" 19 "02_04" 18 "02_03" 17 "02_02" 16 "02_01" 3 "01_04" 2 "01_03" 1 "01_02" 0 "01_01" ;
VAL_ 288 DAC_BMS_Status_Channel 67 "05_04" 66 "05_03" 65 "05_02" 64 "05_01" 51 "04_04" 50 "04_03" 49 "04_02" 48 "04_01" 35 "03_04" 34 "03_03" 33 "03_02" 32 "03_01" 19 "02_04" 18 "02_03" 17 "02_02" 16 "02_01" 3 "01_04" 2 "01_03" 1 "01_02" 0 "01_01" ;
VAL_ 544 DAC_BMS_Cntrl_Channel 67 "05_04" 66 "05_03" 65 "05_02" 64 "05_01" 51 "04_04" 50 "04_03" 49 "04_02" 48 "04_01" 35 "03_04" 34 "03_03" 33 "03_02" 32 "03_01" 19 "02_04" 18 "02_03" 17 "02_02" 16 "02_01" 3 "01_04" 2 "01_03" 1 "01_02" 0 "01_01" ;
VAL_ 658 HIL_TestStatus_TCS 2 "TestStepFail" 1 "TestStepPass" 0 "TestStepRunning" ;
VAL_ 363 LinStatus_Error_on_Slave2 1 "ON" 0 "OFF" ;
VAL_ 363 LinStatus_Error_missing_Slave2 1 "missing" 0 "send message" ;
VAL_ 362 LinStatus_Error_on_Slave1 1 "ON" 0 "OFF" ;
VAL_ 362 LinStatus_Error_missing_Slave1 1 "missing" 0 "send message" ;
VAL_ 361 LinStatus_Error_on_Master 1 "ON" 0 "OFF" ;
VAL_ 361 LinStatus_Error_missing_Master 1 "missing" 0 "send message" ;
VAL_ 619 LinCntrl_Error_on_Slave2 1 "ON" 0 "OFF" ;
VAL_ 619 LinCntrl_Error_missing_Slave2 1 "missing" 0 "send message" ;
VAL_ 618 LinCntrl_Error_on_Slave1 1 "ON" 0 "OFF" ;
VAL_ 618 LinCntrl_Error_missing_Slave1 1 "missing" 0 "send message" ;
VAL_ 617 LinCntrl_Error_on_Master 1 "ON" 0 "OFF" ;
VAL_ 617 LinCntrl_Error_missing_Master 1 "missing" 0 "send message" ;
VAL_ 353 LinStatus_itemState_Master 15 "ITEM_INVALID" 2 "ITEM_EMERGENCY" 1 "ITEM_OFF" 0 "ITEM_ON" ;
VAL_ 353 LinStatus_hvilState_Master 1 "SAFESTATE_UNSAFE" 0 "SAFESTATE_SAFE" ;
VAL_ 610 LinCntrl_on_Slave1 1 "ON" 0 "OFF" ;
VAL_ 610 LinCntrl_itemState_Slave1 15 "ITEM_INVALID" 2 "ITEM_EMERGENCY" 1 "ITEM_OFF" 0 "ITEM_ON" ;
VAL_ 610 LinCntrl_hvilState_Slave1 1 "SAFESTATE_UNSAFE" 0 "SAFESTATE_SAFE" ;
VAL_ 355 LinStatus_itemState_Slave2 15 "ITEM_INVALID" 2 "ITEM_EMERGENCY" 1 "ITEM_OFF" 0 "ITEM_ON" ;
VAL_ 355 LinStatus_hvilState_Slave2 1 "SAFESTATE_UNSAFE" 0 "SAFESTATE_SAFE" ;
VAL_ 609 LinCntrl_askSlaves_Master 2 "ask 2 Slaves for LIN message" 1 "ask 1 Slave for LIN message" 0 "ask 0 Slaves for LIN message" ;
VAL_ 609 LinCntrl_on_Master 1 "ON" 0 "OFF" ;
VAL_ 609 LinCntrl_itemState_Master 15 "ITEM_INVALID" 2 "ITEM_EMERGENCY" 1 "ITEM_OFF" 0 "ITEM_ON" ;
VAL_ 609 LinCntrl_hvilState_Master 1 "SAFESTATE_UNSAFE" 0 "SAFESTATE_SAFE" ;
VAL_ 354 LinStatus_itemState_Slave1 15 "ITEM_INVALID" 2 "ITEM_EMERGENCY" 1 "ITEM_OFF" 0 "ITEM_ON" ;
VAL_ 354 LinStatus_hvilState_Slave1 1 "SAFESTATE_UNSAFE" 0 "SAFESTATE_SAFE" ;
VAL_ 611 LinCntrl_on_Slave2 1 "ON" 0 "OFF" ;
VAL_ 611 LinCntrl_itemState_Slave2 15 "ITEM_INVALID" 2 "ITEM_EMERGENCY" 1 "ITEM_OFF" 0 "ITEM_ON" ;
VAL_ 611 LinCntrl_hvilState_Slave2 1 "SAFESTATE_UNSAFE" 0 "SAFESTATE_SAFE" ;
